VERSION ""

NS_ :

BS_:

BU_: MDC PAS

BO_ 517 PAS_SonarInfo_Rear: 64 PAS
 SG_ PAS_Sonar6_Echo_TOF1 : 7|16@0+ (1,0) [0|65535] "us"  MDC
 SG_ PAS_Sonar6_Echo_Width1 : 23|8@0+ (16,0) [0|4080] "us"  MDC
 SG_ PAS_Sonar6_Echo_TOF2 : 31|16@0+ (1,0) [0|65535] "us"  MDC
 SG_ PAS_Sonar6_Echo_Width2 : 47|8@0+ (16,0) [0|4080] "us"  MDC
 SG_ PAS_Sonar6_Echo_Peak1 : 391|6@0+ (1,0) [0|63] ""  MDC
 SG_ PAS_Sonar6_Echo_Peak2 : 385|6@0+ (1,0) [0|63] ""  MDC
 SG_ PAS_Sonar6_Emit : 457|2@0+ (1,0) [0|2] "bit"  MDC
 SG_ PAS_Sonar6_RingingTime : 55|16@0+ (0.0412,300) [300|3000] "us"  MDC
 SG_ PAS_Sonar6_Counter : 471|4@0+ (1,0) [0|15] "bit"  MDC
 SG_ PAS_Sonar7_Echo_TOF1 : 71|16@0+ (1,0) [0|65535] "us"  MDC
 SG_ PAS_Sonar7_Echo_Width1 : 87|8@0+ (16,0) [0|4080] "us"  MDC
 SG_ PAS_Sonar7_Echo_TOF2 : 95|16@0+ (1,0) [0|65535] "us"  MDC
 SG_ PAS_Sonar7_Echo_Width2 : 111|8@0+ (16,0) [0|4080] "us"  MDC
 SG_ PAS_Sonar7_Echo_Peak1 : 395|6@0+ (1,0) [0|63] ""  MDC
 SG_ PAS_Sonar7_Echo_Peak2 : 405|6@0+ (1,0) [0|63] ""  MDC
 SG_ PAS_Sonar7_Emit : 459|2@0+ (1,0) [0|2] "bit"  MDC
 SG_ PAS_Sonar7_RingingTime : 119|16@0+ (0.0412,300) [300|3000] "us"  MDC
 SG_ PAS_Sonar7_Counter : 475|4@0+ (1,0) [0|15] "bit"  MDC
 SG_ PAS_Sonar8_Echo_TOF1 : 135|16@0+ (1,0) [0|65535] "us"  MDC
 SG_ PAS_Sonar8_Echo_Width1 : 151|8@0+ (16,0) [0|4080] "us"  MDC
 SG_ PAS_Sonar8_Echo_TOF2 : 159|16@0+ (1,0) [0|65535] "us"  MDC
 SG_ PAS_Sonar8_Echo_Width2 : 175|8@0+ (16,0) [0|4080] "us"  MDC
 SG_ PAS_Sonar8_Echo_Peak1 : 415|6@0+ (1,0) [0|63] ""  MDC
 SG_ PAS_Sonar8_Echo_Peak2 : 409|6@0+ (1,0) [0|63] ""  MDC
 SG_ PAS_Sonar8_Emit : 461|2@0+ (1,0) [0|2] "bit"  MDC
 SG_ PAS_Sonar8_RingingTime : 183|16@0+ (0.0412,300) [300|3000] "us"  MDC
 SG_ PAS_Sonar8_Counter : 479|4@0+ (1,0) [0|15] "bit"  MDC
 SG_ PAS_Sonar9_Echo_TOF1 : 199|16@0+ (1,0) [0|65535] "us"  MDC
 SG_ PAS_Sonar9_Echo_Width1 : 215|8@0+ (16,0) [0|4080] "us"  MDC
 SG_ PAS_Sonar9_Echo_TOF2 : 223|16@0+ (1,0) [0|65535] "us"  MDC
 SG_ PAS_Sonar9_Echo_Width2 : 239|8@0+ (16,0) [0|4080] "us"  MDC
 SG_ PAS_Sonar9_Echo_Peak1 : 419|6@0+ (1,0) [0|63] ""  MDC
 SG_ PAS_Sonar9_Echo_Peak2 : 429|6@0+ (1,0) [0|63] ""  MDC
 SG_ PAS_Sonar9_Emit : 463|2@0+ (1,0) [0|2] "bit"  MDC
 SG_ PAS_Sonar9_RingingTime : 247|16@0+ (0.0412,300) [300|3000] "us"  MDC
 SG_ PAS_Sonar9_Counter : 483|4@0+ (1,0) [0|15] "bit"  MDC
 SG_ PAS_Sonar10_Echo_TOF1 : 263|16@0+ (1,0) [0|65535] "us"  MDC
 SG_ PAS_Sonar10_Echo_Width1 : 279|8@0+ (16,0) [0|4080] "us"  MDC
 SG_ PAS_Sonar10_Echo_TOF2 : 287|16@0+ (1,0) [0|65535] "us"  MDC
 SG_ PAS_Sonar10_Echo_Width2 : 303|8@0+ (16,0) [0|4080] "us"  MDC
 SG_ PAS_Sonar10_Echo_Peak1 : 439|6@0+ (1,0) [0|63] ""  MDC
 SG_ PAS_Sonar10_Echo_Peak2 : 433|6@0+ (1,0) [0|63] ""  MDC
 SG_ PAS_Sonar10_Emit : 465|2@0+ (1,0) [0|2] "bit"  MDC
 SG_ PAS_Sonar10_RingingTime : 311|16@0+ (0.0412,300) [300|3000] "us"  MDC
 SG_ PAS_Sonar10_Counter : 487|4@0+ (1,0) [0|15] "bit"  MDC
 SG_ PAS_Sonar11_Echo_TOF1 : 327|16@0+ (1,0) [0|65535] "us"  MDC
 SG_ PAS_Sonar11_Echo_Width1 : 343|8@0+ (16,0) [0|4080] "us"  MDC
 SG_ PAS_Sonar11_Echo_TOF2 : 351|16@0+ (1,0) [0|65535] "us"  MDC
 SG_ PAS_Sonar11_Echo_Width2 : 367|8@0+ (16,0) [0|4080] "us"  MDC
 SG_ PAS_Sonar11_Echo_Peak1 : 443|6@0+ (1,0) [0|63] ""  MDC
 SG_ PAS_Sonar11_Echo_Peak2 : 453|6@0+ (1,0) [0|63] ""  MDC
 SG_ PAS_Sonar11_Emit : 467|2@0+ (1,0) [0|2] "bit"  MDC
 SG_ PAS_Sonar11_RingingTime : 375|16@0+ (0.0412,300) [300|3000] "us"  MDC
 SG_ PAS_Sonar11_Counter : 491|4@0+ (1,0) [0|15] "bit"  MDC
 SG_ PASSonarInfoRearRollingCounter : 507|4@0+ (1,0) [0|14] "bit"  MDC
 SG_ PAS_SonarInfo_Rear_Checksum : 503|8@0+ (1,0) [0|255] "bit"  MDC
 SG_ Fill4bit : 511|4@0+ (1,0) [0|15] "bit"  MDC

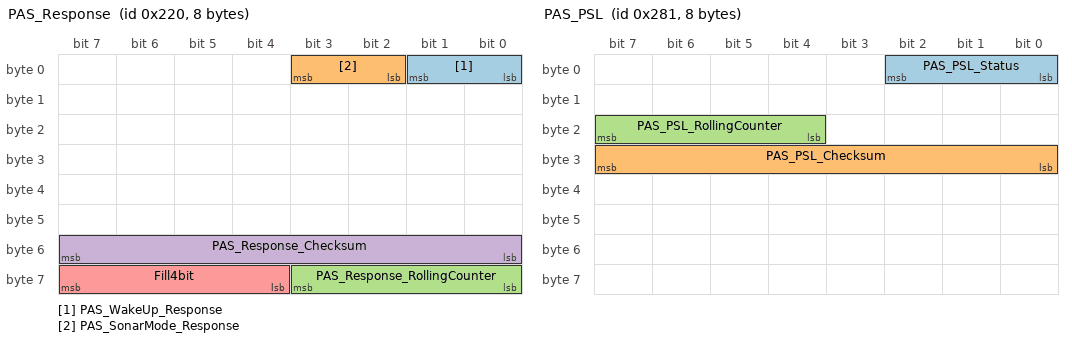
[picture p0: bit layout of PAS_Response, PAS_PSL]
BO_ 544 PAS_Response: 8 PAS
 SG_ PAS_WakeUp_Response : 1|2@0+ (1,0) [0|1] "bit"  MDC
 SG_ PAS_SonarMode_Response : 3|2@0+ (1,0) [0|1] "bit"  MDC
 SG_ PAS_Response_RollingCounter : 59|4@0+ (1,0) [0|14] "bit"  MDC
 SG_ PAS_Response_Checksum : 55|8@0+ (1,0) [0|255] "bit"  MDC
 SG_ Fill4bit : 63|4@0+ (1,0) [0|15] "bit"  MDC

BO_ 560 PAS_SensorStatus: 8 PAS
 SG_ PAS_SensorStsLR_FLS : 1|2@0+ (1,0) [0|1] "bit"  MDC
 SG_ PAS_SensorStsLR_FRS : 3|2@0+ (1,0) [0|1] "bit"  MDC
 SG_ PAS_SensorStsSR_FL : 5|2@0+ (1,0) [0|1] "bit"  MDC
 SG_ PAS_SensorStsSR_FML : 7|2@0+ (1,0) [0|1] "bit"  MDC
 SG_ PAS_SensorStsSR_FMR : 9|2@0+ (1,0) [0|1] "bit"  MDC
 SG_ PAS_SensorStsSR_FR : 11|2@0+ (1,0) [0|1] "bit"  MDC
 SG_ PAS_SensorStsLR_RLS : 13|2@0+ (1,0) [0|1] "bit"  MDC
 SG_ PAS_SensorStsLR_RRS : 15|2@0+ (1,0) [0|1] "bit"  MDC
 SG_ PAS_SensorStsSR_RL : 17|2@0+ (1,0) [0|1] "bit"  MDC
 SG_ PAS_SensorStsSR_RML : 19|2@0+ (1,0) [0|1] "bit"  MDC
 SG_ PAS_SensorStsSR_RMR : 21|2@0+ (1,0) [0|1] "bit"  MDC
 SG_ PAS_SensorStsSR_RR : 23|2@0+ (1,0) [0|1] "bit"  MDC
 SG_ PAS_ECU_Status : 25|2@0+ (1,0) [0|1] "bit"  MDC
 SG_ PAS_ECU_VehStatus_Reponse : 27|2@0+ (1,0) [0|1] "bit"  MDC
 SG_ sensorVersion_Status : 33|2@0+ (1,0) [0|1] "bit"  MDC
 SG_ PAS_SensorStatus_RollingCounter : 59|4@0+ (1,0) [0|14] "bit"  MDC
 SG_ PAS_SensorStatus_Checksum : 55|8@0+ (1,0) [0|255] "bit"  MDC
 SG_ Fill4bit : 63|4@0+ (1,0) [0|15] "bit"  MDC

BO_ 576 PAS_ECU_Version: 12 PAS
 SG_ PAS_ECU_Information_Ver_Hard : 7|8@0+ (1,0) [0|255] "bit"  MDC
 SG_ PAS_ECU_Information_Ver_Soft : 15|8@0+ (1,0) [0|255] "bit"  MDC
 SG_ PAS_ECU_Information_Ver_Boot : 23|8@0+ (1,0) [0|255] "bit"  MDC
 SG_ PAS_ECU_Information_Date_Year : 31|16@0+ (1,0) [0|65535] "bit"  MDC
 SG_ PAS_ECU_Information_Date_Month : 47|8@0+ (1,0) [0|255] "bit"  MDC
 SG_ PAS_ECU_Information_Date_Day : 55|8@0+ (1,0) [0|255] "bit"  MDC
 SG_ PAS_ECU_Version_Checksum : 87|8@0+ (1,0) [0|255] "bit"  MDC
 SG_ PAS_ECUInfo_RollingCounter : 91|4@0+ (1,0) [0|14] "bit"  MDC
 SG_ Fill4bit : 95|4@0+ (1,0) [0|15] "bit"  MDC

BO_ 592 PAS_RptAlarm: 12 PAS
 SG_ Rpt_Alarm_Id : 7|8@0+ (1,0) [0|255] "bit"  MDC
 SG_ Rpt_Alarm_State : 8|1@0+ (1,0) [0|1] "bit"  MDC
 SG_ Rpt_Alarm_Level : 11|2@0+ (1,0) [0|2] "bit"  MDC
 SG_ Rpt_Transaction_Id : 15|4@0+ (1,0) [0|15] "bit"  MDC
 SG_ Rpt_Alarm_Para1 : 23|16@0+ (1,0) [0|65535] "bit"  MDC
 SG_ Rpt_Alarm_Para2 : 39|16@0+ (1,0) [0|65535] "bit"  MDC
 SG_ Rpt_Alarm_Para3 : 55|16@0+ (1,0) [0|65535] "bit"  MDC
 SG_ Rpt_Alarm_Checksum : 87|8@0+ (1,0) [0|255] "bit"  MDC
 SG_ Rpt_Alarm_RollingCounter : 91|4@0+ (1,0) [0|14] "bit"  MDC
 SG_ Fill4bit : 95|4@0+ (1,0) [0|15] "bit"  MDC

BO_ 593 PAS_DiagnosisInfo: 16 PAS
 SG_ PAS_Sonar1_ControlBusFailure : 0|1@0+ (1,0) [0|1] "bit"  MDC
 SG_ PAS_Sonar1_RingingTimeFailure : 1|1@0+ (1,0) [0|1] "bit"  MDC
 SG_ PAS_Sonar1_ShortToGND : 2|1@0+ (1,0) [0|1] "bit"  MDC
 SG_ PAS_Sonar1_ShortToPositivePole : 3|1@0+ (1,0) [0|1] "bit"  MDC
 SG_ PAS_Sonar1_TypeMismatch : 4|1@0+ (1,0) [0|1] "bit"  MDC
 SG_ PAS_Sonar2_ControlBusFailure : 8|1@0+ (1,0) [0|1] "bit"  MDC
 SG_ PAS_Sonar2_RingingTimeFailure : 9|1@0+ (1,0) [0|1] "bit"  MDC
 SG_ PAS_Sonar2_ShortToGND : 10|1@0+ (1,0) [0|1] "bit"  MDC
 SG_ PAS_Sonar2_ShortToPositivePole : 11|1@0+ (1,0) [0|1] "bit"  MDC
 SG_ PAS_Sonar2_TypeMismatch : 12|1@0+ (1,0) [0|1] "bit"  MDC
 SG_ PAS_Sonar3_ControlBusFailure : 16|1@0+ (1,0) [0|1] "bit"  MDC
 SG_ PAS_Sonar3_RingingTimeFailure : 17|1@0+ (1,0) [0|1] "bit"  MDC
 SG_ PAS_Sonar3_ShortToGND : 18|1@0+ (1,0) [0|1] "bit"  MDC
 SG_ PAS_Sonar3_ShortToPositivePole : 19|1@0+ (1,0) [0|1] "bit"  MDC
 SG_ PAS_Sonar3_TypeMismatch : 20|1@0+ (1,0) [0|1] "bit"  MDC
 SG_ PAS_Sonar3_PowerVoltage_Low : 21|1@0+ (1,0) [0|1] "bit"  MDC
 SG_ PAS_Sonar3_PowerVoltage_High : 22|1@0+ (1,0) [0|1] "bit"  MDC
 SG_ PAS_Sonar4_ControlBusFailure : 24|1@0+ (1,0) [0|1] "bit"  MDC
 SG_ PAS_Sonar4_RingingTimeFailure : 25|1@0+ (1,0) [0|1] "bit"  MDC
 SG_ PAS_Sonar4_ShortToGND : 26|1@0+ (1,0) [0|1] "bit"  MDC
 SG_ PAS_Sonar4_ShortToPositivePole : 27|1@0+ (1,0) [0|1] "bit"  MDC
 SG_ PAS_Sonar4_TypeMismatch : 28|1@0+ (1,0) [0|1] "bit"  MDC
 SG_ PAS_Sonar7_ControlBusFailure : 32|1@0+ (1,0) [0|1] "bit"  MDC
 SG_ PAS_Sonar7_RingingTimeFailure : 33|1@0+ (1,0) [0|1] "bit"  MDC
 SG_ PAS_Sonar7_ShortToGND : 34|1@0+ (1,0) [0|1] "bit"  MDC
 SG_ PAS_Sonar7_ShortToPositivePole : 35|1@0+ (1,0) [0|1] "bit"  MDC
 SG_ PAS_Sonar7_TypeMismatch : 36|1@0+ (1,0) [0|1] "bit"  MDC
 SG_ PAS_Sonar8_ControlBusFailure : 40|1@0+ (1,0) [0|1] "bit"  MDC
 SG_ PAS_Sonar8_RingingTimeFailure : 41|1@0+ (1,0) [0|1] "bit"  MDC
 SG_ PAS_Sonar8_ShortToGND : 42|1@0+ (1,0) [0|1] "bit"  MDC
 SG_ PAS_Sonar8_ShortToPositivePole : 43|1@0+ (1,0) [0|1] "bit"  MDC
 SG_ PAS_Sonar8_TypeMismatch : 44|1@0+ (1,0) [0|1] "bit"  MDC
 SG_ PAS_Sonar9_ControlBusFailure : 48|1@0+ (1,0) [0|1] "bit"  MDC
 SG_ PAS_Sonar9_RingingTimeFailure : 49|1@0+ (1,0) [0|1] "bit"  MDC
 SG_ PAS_Sonar9_ShortToGND : 50|1@0+ (1,0) [0|1] "bit"  MDC
 SG_ PAS_Sonar9_ShortToPositivePole : 51|1@0+ (1,0) [0|1] "bit"  MDC
 SG_ PAS_Sonar9_TypeMismatch : 52|1@0+ (1,0) [0|1] "bit"  MDC
 SG_ PAS_Sonar10_ControlBusFailure : 56|1@0+ (1,0) [0|1] "bit"  MDC
 SG_ PAS_Sonar10_RingingTimeFailure : 57|1@0+ (1,0) [0|1] "bit"  MDC
 SG_ PAS_Sonar10_ShortToGND : 58|1@0+ (1,0) [0|1] "bit"  MDC
 SG_ PAS_Sonar10_ShortToPositivePole : 59|1@0+ (1,0) [0|1] "bit"  MDC
 SG_ PAS_Sonar10_TypeMismatch : 60|1@0+ (1,0) [0|1] "bit"  MDC
 SG_ PAS_Sonar0_ControlBusFailure : 64|1@0+ (1,0) [0|1] "bit"  MDC
 SG_ PAS_Sonar0_RingingTimeFailure : 65|1@0+ (1,0) [0|1] "bit"  MDC
 SG_ PAS_Sonar0_ShortToGND : 66|1@0+ (1,0) [0|1] "bit"  MDC
 SG_ PAS_Sonar0_ShortToPositivePole : 67|1@0+ (1,0) [0|1] "bit"  MDC
 SG_ PAS_Sonar0_TypeMismatch : 68|1@0+ (1,0) [0|1] "bit"  MDC
 SG_ PAS_Sonar5_ControlBusFailure : 72|1@0+ (1,0) [0|1] "bit"  MDC
 SG_ PAS_Sonar5_RingingTimeFailure : 73|1@0+ (1,0) [0|1] "bit"  MDC
 SG_ PAS_Sonar5_ShortToGND : 74|1@0+ (1,0) [0|1] "bit"  MDC
 SG_ PAS_Sonar5_ShortToPositivePole : 75|1@0+ (1,0) [0|1] "bit"  MDC
 SG_ PAS_Sonar5_TypeMismatch : 76|1@0+ (1,0) [0|1] "bit"  MDC
 SG_ PAS_Sonar6_ControlBusFailure : 80|1@0+ (1,0) [0|1] "bit"  MDC
 SG_ PAS_Sonar6_RingingTimeFailure : 81|1@0+ (1,0) [0|1] "bit"  MDC
 SG_ PAS_Sonar6_ShortToGND : 82|1@0+ (1,0) [0|1] "bit"  MDC
 SG_ PAS_Sonar6_ShortToPositivePole : 83|1@0+ (1,0) [0|1] "bit"  MDC
 SG_ PAS_Sonar6_TypeMismatch : 84|1@0+ (1,0) [0|1] "bit"  MDC
 SG_ PAS_Sonar11_ControlBusFailure : 88|1@0+ (1,0) [0|1] "bit"  MDC
 SG_ PAS_Sonar11_RingingTimeFailure : 89|1@0+ (1,0) [0|1] "bit"  MDC
 SG_ PAS_Sonar11_ShortToGND : 90|1@0+ (1,0) [0|1] "bit"  MDC
 SG_ PAS_Sonar11_ShortToPositivePole : 91|1@0+ (1,0) [0|1] "bit"  MDC
 SG_ PAS_Sonar11_TypeMismatch : 92|1@0+ (1,0) [0|1] "bit"  MDC
 SG_ PAS_ECU_OverVoltage : 96|1@0+ (1,0) [0|1] "bit"  MDC
 SG_ PAS_ECU_UnderVoltage : 97|1@0+ (1,0) [0|1] "bit"  MDC
 SG_ PAS_ECU_BusOff_ERROR : 98|1@0+ (1,0) [0|1] "bit"  MDC
 SG_ PAS_MDC_COMMU_ERROR : 99|1@0+ (1,0) [0|1] "bit"  MDC
 SG_ PAS_ECU_EEPROM_ERROR : 100|1@0+ (1,0) [0|1] "bit"  MDC
 SG_ PAS_DiagnosisInfo_RollingCounter : 123|4@0+ (1,0) [0|14] "bit"  MDC
 SG_ PAS_DiagnosisInfo_Checksum : 119|8@0+ (1,0) [0|255] "bit"  MDC
 SG_ Fill4bit : 127|4@0+ (1,0) [0|15] "bit"  MDC
 SG_ PAS_MDCSIGNAL_ERROR : 109|1@0+ (1,0) [0|1] "bit"  MDC
 SG_ PAS_ECU_INTERNAL_ERROR : 105|1@0+ (1,0) [0|1] "bit"  MDC
 SG_ PAS_TIMESYNC_ERROR : 106|1@0+ (1,0) [0|1] "bit"  MDC
 SG_ PAS_KEYLEARN_ERROR : 107|1@0+ (1,0) [0|1] "bit"  MDC
 SG_ PAS_AUTHEN_ERROR : 108|1@0+ (1,0) [0|1] "bit"  MDC
 SG_ PAS_Sonar0_Internal_failure : 29|1@0+ (1,0) [0|1] "bit"  MDC
 SG_ PAS_Sonar1_Internal_failure : 30|1@0+ (1,0) [0|1] "bit"  MDC
 SG_ PAS_Sonar2_Internal_failure : 31|1@0+ (1,0) [0|1] "bit"  MDC
 SG_ PAS_Sonar3_Internal_failure : 37|1@0+ (1,0) [0|1] "bit"  MDC
 SG_ PAS_Sonar4_Internal_failure : 38|1@0+ (1,0) [0|1] "bit"  MDC
 SG_ PAS_Sonar5_Internal_failure : 39|1@0+ (1,0) [0|1] "bit"  MDC
 SG_ PAS_Sonar6_Internal_failure : 45|1@0+ (1,0) [0|1] "bit"  MDC
 SG_ PAS_Sonar7_Internal_failure : 46|1@0+ (1,0) [0|1] "bit"  MDC
 SG_ PAS_Sonar8_Internal_failure : 47|1@0+ (1,0) [0|1] "bit"  MDC
 SG_ PAS_Sonar9_Internal_failure : 53|1@0+ (1,0) [0|1] "bit"  MDC
 SG_ PAS_Sonar10_Internal_failure : 54|1@0+ (1,0) [0|1] "bit"  MDC
 SG_ PAS_Sonar11_Internal_failure : 55|1@0+ (1,0) [0|1] "bit"  MDC
 SG_ USS_Front_ShortToGND : 61|1@0+ (1,0) [0|1] "bit"  MDC
 SG_ USS_Front_ShortToUbat : 62|1@0+ (1,0) [0|1] "bit"  MDC
 SG_ USS_Rear_ShortToGND : 63|1@0+ (1,0) [0|1] "bit"  MDC
 SG_ USS_Rear_ShortToUbat : 69|1@0+ (1,0) [0|1] "bit"  MDC
 SG_ VHM_Error : 70|1@0+ (1,0) [0|1] "bit"  MDC
 SG_ Sensor_Version_Fail : 71|1@0+ (1,0) [0|1] "bit"  MDC

BO_ 672 PAS_DeviceVertifyReq: 8 PAS
 SG_ PAS_Device_Vertify_Times : 7|8@0+ (1,0) [0|255] ""  MDC
 SG_ PAS_Device_Vertify_Status : 15|8@0+ (1,0) [0|1] ""  MDC

BO_ 673 PAS_Challenge_K1: 12 PAS
 SG_ PAS_RandomByte1 : 7|8@0+ (1,0) [0|255] "bit"  MDC
 SG_ PAS_RandomByte2 : 15|8@0+ (1,0) [0|255] "bit"  MDC
 SG_ PAS_RandomByte3 : 23|8@0+ (1,0) [0|255] "bit"  MDC
 SG_ PAS_RandomByte4 : 31|8@0+ (1,0) [0|255] "bit"  MDC
 SG_ PAS_RandomByte5 : 39|8@0+ (1,0) [0|255] "bit"  MDC
 SG_ PAS_RandomByte6 : 47|8@0+ (1,0) [0|255] "bit"  MDC
 SG_ PAS_RandomByte7 : 55|8@0+ (1,0) [0|255] "bit"  MDC
 SG_ PAS_RandomByte8 : 63|8@0+ (1,0) [0|255] "bit"  MDC
 SG_ PAS_SessionID : 71|8@0+ (1,0) [0|255] "bit"  MDC

BO_ 674 PAS_Response_K2: 12 PAS
 SG_ PAS_Verification_Result : 2|3@0+ (1,0) [0|1] ""  MDC
 SG_ PAS_SessionID : 15|8@0+ (1,0) [0|255] "" Vector__XXX
 SG_ PAS_CMACByte1 : 23|8@0+ (1,0) [0|255] "bit"  MDC
 SG_ PAS_CMACByte2 : 31|8@0+ (1,0) [0|255] "bit"  MDC
 SG_ PAS_CMACByte3 : 39|8@0+ (1,0) [0|255] "bit"  MDC
 SG_ PAS_CMACByte4 : 47|8@0+ (1,0) [0|255] "bit"  MDC
 SG_ PAS_CMACByte5 : 55|8@0+ (1,0) [0|255] "bit"  MDC
 SG_ PAS_CMACByte6 : 63|8@0+ (1,0) [0|255] "bit"  MDC
 SG_ PAS_CMACByte7 : 71|8@0+ (1,0) [0|255] "bit"  MDC
 SG_ PAS_CMACByte8 : 79|8@0+ (1,0) [0|255] "bit"  MDC

BO_ 706 PAS_Key_Learn_Status: 64 PAS
 SG_ PAS_Key_Learn_SubID : 7|8@0+ (1,0) [0|7] ""  MDC
 SG_ PAS_Key_Learn_Numbers : 15|8@0+ (1,0) [1|12] ""  MDC
 SG_ PAS_SKID1 : 23|8@0+ (1,0) [1|12] ""  MDC
 SG_ PAS_SK_Learn_Status1 : 31|8@0+ (1,0) [0|1] ""  MDC
 SG_ PAS_SKID2 : 39|8@0+ (1,0) [1|12] ""  MDC
 SG_ PAS_SK_Learn_Status2 : 47|8@0+ (1,0) [0|1] ""  MDC
 SG_ PAS_SKID3 : 55|8@0+ (1,0) [1|12] ""  MDC
 SG_ PAS_SK_Learn_Status3 : 63|8@0+ (1,0) [0|1] ""  MDC
 SG_ PAS_SKID4 : 71|8@0+ (1,0) [1|12] ""  MDC
 SG_ PAS_SK_Learn_Status4 : 79|8@0+ (1,0) [0|1] ""  MDC
 SG_ PAS_SKID5 : 87|8@0+ (1,0) [1|12] ""  MDC
 SG_ PAS_SK_Learn_Status5 : 95|8@0+ (1,0) [0|1] ""  MDC
 SG_ PAS_SKID6 : 103|8@0+ (1,0) [1|12] ""  MDC
 SG_ PAS_SK_Learn_Status6 : 111|8@0+ (1,0) [0|1] ""  MDC
 SG_ PAS_SKID7 : 119|8@0+ (1,0) [1|12] ""  MDC
 SG_ PAS_SK_Learn_Status7 : 127|8@0+ (1,0) [0|1] ""  MDC
 SG_ PAS_SKID8 : 135|8@0+ (1,0) [1|12] ""  MDC
 SG_ PAS_SK_Learn_Status8 : 143|8@0+ (1,0) [0|1] ""  MDC
 SG_ PAS_SKID9 : 151|8@0+ (1,0) [1|12] ""  MDC
 SG_ PAS_SK_Learn_Status9 : 159|8@0+ (1,0) [0|1] ""  MDC
 SG_ PAS_SKID10 : 167|8@0+ (1,0) [1|12] ""  MDC
 SG_ PAS_SK_Learn_Status10 : 175|8@0+ (1,0) [0|1] ""  MDC
 SG_ PAS_SKID11 : 183|8@0+ (1,0) [1|12] ""  MDC
 SG_ PAS_SK_Learn_Status11 : 191|8@0+ (1,0) [0|1] ""  MDC
 SG_ PAS_SKID12 : 199|8@0+ (1,0) [1|12] ""  MDC
 SG_ PAS_SK_Learn_Status12 : 207|8@0+ (1,0) [0|1] ""  MDC

BO_ 708 PAS_SK_Setting_Status: 64 PAS
 SG_ PASKeyLearnSubIDSettingResponse : 7|8@0+ (1,0) [0|7] ""  MDC
 SG_ PAS_SK_Setting_Response : 15|8@0+ (1,0) [1|12] ""  MDC
 SG_ PAS_SK_Setting_Status : 23|8@0+ (1,0) [0|1] ""  MDC

BO_ 707 PAS_SK_Verify_Result: 64 PAS
 SG_ PAS_VerifySubID : 7|8@0+ (1,0) [0|6] ""  MDC
 SG_ PAS_Verify_SKID : 15|8@0+ (1,0) [1|12] ""  MDC
 SG_ PAS_Verify_AES_Result : 23|32@0+ (1,0) [0|255] ""  MDC
 SG_ PAS_Verify_MACbyte1 : 55|8@0+ (1,0) [0|255] ""  MDC
 SG_ PAS_Verify_MACbyte2 : 63|8@0+ (1,0) [0|255] "" Vector__XXX
 SG_ PAS_Verify_MACbyte3 : 71|8@0+ (1,0) [0|255] "" Vector__XXX
 SG_ PAS_Verify_MACbyte4 : 79|8@0+ (1,0) [0|255] "" Vector__XXX
 SG_ PAS_Verify_MACbyte5 : 87|8@0+ (1,0) [0|255] "" Vector__XXX
 SG_ PAS_Verify_MACbyte6 : 95|8@0+ (1,0) [0|255] "" Vector__XXX
 SG_ PAS_Verify_MACbyte7 : 103|8@0+ (1,0) [0|255] "" Vector__XXX
 SG_ PAS_Verify_MACbyte8 : 111|8@0+ (1,0) [0|255] "" Vector__XXX
 SG_ PAS_Verify_MACbyte9 : 119|8@0+ (1,0) [0|255] "" Vector__XXX
 SG_ PAS_Verify_MACbyte10 : 127|8@0+ (1,0) [0|255] "" Vector__XXX
 SG_ PAS_Verify_MACbyte11 : 135|8@0+ (1,0) [0|255] "" Vector__XXX
 SG_ PAS_Verify_MACbyte12 : 143|8@0+ (1,0) [0|255] "" Vector__XXX
 SG_ PAS_Verify_MACbyte13 : 151|8@0+ (1,0) [0|255] "" Vector__XXX
 SG_ PAS_Verify_MACbyte14 : 159|8@0+ (1,0) [0|255] "" Vector__XXX
 SG_ PAS_Verify_MACbyte15 : 167|8@0+ (1,0) [0|255] "" Vector__XXX
 SG_ PAS_Verify_MACbyte16 : 175|8@0+ (1,0) [0|255] "" Vector__XXX
 SG_ PAS_Verify_IVByte1 : 183|8@0+ (1,0) [0|255] ""  MDC
 SG_ PAS_Verify_IVByte2 : 191|8@0+ (1,0) [0|255] "" Vector__XXX
 SG_ PAS_Verify_IVByte3 : 199|8@0+ (1,0) [0|255] "" Vector__XXX
 SG_ PAS_Verify_IVByte4 : 207|8@0+ (1,0) [0|255] "" Vector__XXX
 SG_ PAS_Verify_IVByte5 : 215|8@0+ (1,0) [0|255] "" Vector__XXX
 SG_ PAS_Verify_IVByte6 : 223|8@0+ (1,0) [0|255] "" Vector__XXX
 SG_ PAS_Verify_IVByte7 : 231|8@0+ (1,0) [0|255] "" Vector__XXX
 SG_ PAS_Verify_IVByte8 : 239|8@0+ (1,0) [0|255] "" Vector__XXX
 SG_ PAS_Verify_IVByte9 : 247|8@0+ (1,0) [0|255] "" Vector__XXX
 SG_ PAS_Verify_IVByte10 : 255|8@0+ (1,0) [0|255] "" Vector__XXX
 SG_ PAS_Verify_IVByte11 : 263|8@0+ (1,0) [0|255] "" Vector__XXX
 SG_ PAS_Verify_IVByte12 : 271|8@0+ (1,0) [0|255] "" Vector__XXX

BO_ 608 UPC_Object1_5: 64 PAS
 SG_ UPC_Object1_Type : 2|3@0+ (1,0) [0|7] ""  MDC
 SG_ UPC_Object1_ExistProbability : 14|7@0+ (1,0) [0|100] "%"  MDC
 SG_ UPC_Object1_Height : 4|2@0+ (1,0) [0|3] ""  MDC
 SG_ UPC_Object1_HeightProbability : 7|3@0+ (20,0) [0|100] "%"  MDC
 SG_ UPCObject1PositionUpdateTime : 23|12@0+ (0.5,0) [0|1000] "ms"  MDC
 SG_ UPC_Object1_Point1PositionX : 26|11@0+ (1,-1024) [-1024|1023] "cm"  MDC
 SG_ UPC_Object1_Point1PositionY : 47|11@0+ (1,-1024) [-1024|1023] "cm"  MDC
 SG_ UPC_Object1_Point2PositionX : 50|11@0+ (1,-1024) [-1024|1023] "cm"  MDC
 SG_ UPC_Object1_Point2PositionY : 71|11@0+ (1,-1024) [-1024|1023] "cm"  MDC
 SG_ UPC_Object1_ID : 87|16@0+ (1,0) [0|65535] ""  MDC
 SG_ UPC_Object2_Type : 98|3@0+ (1,0) [0|7] ""  MDC
 SG_ UPC_Object2_ExistProbability : 110|7@0+ (1,0) [0|100] "%"  MDC
 SG_ UPC_Object2_Height : 100|2@0+ (1,0) [0|3] ""  MDC
 SG_ UPC_Object2_HeightProbability : 103|3@0+ (20,0) [0|100] "%"  MDC
 SG_ UPCObject2PositionUpdateTime : 119|12@0+ (0.5,0) [0|1000] "ms"  MDC
 SG_ UPC_Object2_Point1PositionX : 122|11@0+ (1,-1024) [-1024|1023] "cm"  MDC
 SG_ UPC_Object2_Point1PositionY : 143|11@0+ (1,-1024) [-1024|1023] "cm"  MDC
 SG_ UPC_Object2_Point2PositionX : 146|11@0+ (1,-1024) [-1024|1023] "cm"  MDC
 SG_ UPC_Object2_Point2PositionY : 167|11@0+ (1,-1024) [-1024|1023] "cm"  MDC
 SG_ UPC_Object2_ID : 183|16@0+ (1,0) [0|65535] ""  MDC
 SG_ UPC_Object3_Type : 194|3@0+ (1,0) [0|7] ""  MDC
 SG_ UPC_Object3_ExistProbability : 206|7@0+ (1,0) [0|100] "%"  MDC
 SG_ UPC_Object3_Height : 196|2@0+ (1,0) [0|3] ""  MDC
 SG_ UPC_Object3_HeightProbability : 199|3@0+ (20,0) [0|100] "%"  MDC
 SG_ UPCObject3PositionUpdateTime : 215|12@0+ (0.5,0) [0|1000] "ms"  MDC
 SG_ UPC_Object3_Point1PositionX : 218|11@0+ (1,-1024) [-1024|1023] "cm"  MDC
 SG_ UPC_Object3_Point1PositionY : 239|11@0+ (1,-1024) [-1024|1023] "cm"  MDC
 SG_ UPC_Object3_Point2PositionX : 242|11@0+ (1,-1024) [-1024|1023] "cm"  MDC
 SG_ UPC_Object3_Point2PositionY : 263|11@0+ (1,-1024) [-1024|1023] "cm"  MDC
 SG_ UPC_Object3_ID : 279|16@0+ (1,0) [0|65535] ""  MDC
 SG_ UPC_Object4_Type : 290|3@0+ (1,0) [0|7] ""  MDC
 SG_ UPC_Object4_ExistProbability : 302|7@0+ (1,0) [0|100] "%"  MDC
 SG_ UPC_Object4_Height : 292|2@0+ (1,0) [0|3] ""  MDC
 SG_ UPC_Object4_HeightProbability : 295|3@0+ (20,0) [0|100] "%"  MDC
 SG_ UPCObject4PositionUpdateTime : 311|12@0+ (0.5,0) [0|1000] "ms"  MDC
 SG_ UPC_Object4_Point1PositionX : 314|11@0+ (1,-1024) [-1024|1023] "cm"  MDC
 SG_ UPC_Object4_Point1PositionY : 335|11@0+ (1,-1024) [-1024|1023] "cm"  MDC
 SG_ UPC_Object4_Point2PositionX : 338|11@0+ (1,-1024) [-1024|1023] "cm"  MDC
 SG_ UPC_Object4_Point2PositionY : 359|11@0+ (1,-1024) [-1024|1023] "cm"  MDC
 SG_ UPC_Object4_ID : 375|16@0+ (1,0) [0|65535] ""  MDC
 SG_ UPC_Object5_Type : 386|3@0+ (1,0) [0|7] ""  MDC
 SG_ UPC_Object5_ExistProbability : 398|7@0+ (1,0) [0|100] "%"  MDC
 SG_ UPC_Object5_Height : 388|2@0+ (1,0) [0|3] ""  MDC
 SG_ UPC_Object5_HeightProbability : 391|3@0+ (20,0) [0|100] "%"  MDC
 SG_ UPCObject5PositionUpdateTime : 407|12@0+ (0.5,0) [0|1000] "ms"  MDC
 SG_ UPC_Object5_Point1PositionX : 410|11@0+ (1,-1024) [-1024|1023] "cm"  MDC
 SG_ UPC_Object5_Point1PositionY : 431|11@0+ (1,-1024) [-1024|1023] "cm"  MDC
 SG_ UPC_Object5_Point2PositionX : 434|11@0+ (1,-1024) [-1024|1023] "cm"  MDC
 SG_ UPC_Object5_Point2PositionY : 455|11@0+ (1,-1024) [-1024|1023] "cm"  MDC
 SG_ UPC_Object5_ID : 471|16@0+ (1,0) [0|65535] ""  MDC
 SG_ PAS_Obj1_5_Checksum : 511|8@0+ (1,0) [0|255] "bit"  MDC
 SG_ PAS_Obj1_5_RollingCounter : 499|4@0+ (1,0) [0|14] "bit"  MDC

BO_ 609 UPC_Object6_10: 64 PAS
 SG_ UPC_Object6_Type : 2|3@0+ (1,0) [0|7] ""  MDC
 SG_ UPC_Object6_ExistProbability : 14|7@0+ (1,0) [0|100] "%"  MDC
 SG_ UPC_Object6_Height : 4|2@0+ (1,0) [0|3] ""  MDC
 SG_ UPC_Object6_HeightProbability : 7|3@0+ (20,0) [0|100] "%"  MDC
 SG_ UPCObject6PositionUpdateTime : 23|12@0+ (0.5,0) [0|1000] "ms"  MDC
 SG_ UPC_Object6_Point1PositionX : 26|11@0+ (1,-1024) [-1024|1023] "cm"  MDC
 SG_ UPC_Object6_Point1PositionY : 47|11@0+ (1,-1024) [-1024|1023] "cm"  MDC
 SG_ UPC_Object6_Point2PositionX : 50|11@0+ (1,-1024) [-1024|1023] "cm"  MDC
 SG_ UPC_Object6_Point2PositionY : 71|11@0+ (1,-1024) [-1024|1023] "cm"  MDC
 SG_ UPC_Object6_ID : 87|16@0+ (1,0) [0|65535] ""  MDC
 SG_ UPC_Object7_Type : 98|3@0+ (1,0) [0|7] ""  MDC
 SG_ UPC_Object7_ExistProbability : 110|7@0+ (1,0) [0|100] "%"  MDC
 SG_ UPC_Object7_Height : 100|2@0+ (1,0) [0|3] ""  MDC
 SG_ UPC_Object7_HeightProbability : 103|3@0+ (20,0) [0|100] "%"  MDC
 SG_ UPCObject7PositionUpdateTime : 119|12@0+ (0.5,0) [0|1000] "ms"  MDC
 SG_ UPC_Object7_Point1PositionX : 122|11@0+ (1,-1024) [-1024|1023] "cm"  MDC
 SG_ UPC_Object7_Point1PositionY : 143|11@0+ (1,-1024) [-1024|1023] "cm"  MDC
 SG_ UPC_Object7_Point2PositionX : 146|11@0+ (1,-1024) [-1024|1023] "cm"  MDC
 SG_ UPC_Object7_Point2PositionY : 167|11@0+ (1,-1024) [-1024|1023] "cm"  MDC
 SG_ UPC_Object7_ID : 183|16@0+ (1,0) [0|65535] ""  MDC
 SG_ UPC_Object8_Type : 194|3@0+ (1,0) [0|7] ""  MDC
 SG_ UPC_Object8_ExistProbability : 206|7@0+ (1,0) [0|100] "%"  MDC
 SG_ UPC_Object8_Height : 196|2@0+ (1,0) [0|3] ""  MDC
 SG_ UPC_Object8_HeightProbability : 199|3@0+ (20,0) [0|100] "%"  MDC
 SG_ UPCObject8PositionUpdateTime : 215|12@0+ (0.5,0) [0|1000] "ms"  MDC
 SG_ UPC_Object8_Point1PositionX : 218|11@0+ (1,-1024) [-1024|1023] "cm"  MDC
 SG_ UPC_Object8_Point1PositionY : 239|11@0+ (1,-1024) [-1024|1023] "cm"  MDC
 SG_ UPC_Object8_Point2PositionX : 242|11@0+ (1,-1024) [-1024|1023] "cm"  MDC
 SG_ UPC_Object8_Point2PositionY : 263|11@0+ (1,-1024) [-1024|1023] "cm"  MDC
 SG_ UPC_Object8_ID : 279|16@0+ (1,0) [0|65535] ""  MDC
 SG_ UPC_Object9_Type : 290|3@0+ (1,0) [0|7] ""  MDC
 SG_ UPC_Object9_ExistProbability : 302|7@0+ (1,0) [0|100] "%"  MDC
 SG_ UPC_Object9_Height : 292|2@0+ (1,0) [0|3] ""  MDC
 SG_ UPC_Object9_HeightProbability : 295|3@0+ (20,0) [0|100] "%"  MDC
 SG_ UPCObject9PositionUpdateTime : 311|12@0+ (0.5,0) [0|1000] "ms"  MDC
 SG_ UPC_Object9_Point1PositionX : 314|11@0+ (1,-1024) [-1024|1023] "cm"  MDC
 SG_ UPC_Object9_Point1PositionY : 335|11@0+ (1,-1024) [-1024|1023] "cm"  MDC
 SG_ UPC_Object9_Point2PositionX : 338|11@0+ (1,-1024) [-1024|1023] "cm"  MDC
 SG_ UPC_Object9_Point2PositionY : 359|11@0+ (1,-1024) [-1024|1023] "cm"  MDC
 SG_ UPC_Object9_ID : 375|16@0+ (1,0) [0|65535] ""  MDC
 SG_ UPC_Object10_Type : 386|3@0+ (1,0) [0|7] ""  MDC
 SG_ UPC_Object10_ExistProbability : 398|7@0+ (1,0) [0|100] "%"  MDC
 SG_ UPC_Object10_Height : 388|2@0+ (1,0) [0|3] ""  MDC
 SG_ UPC_Object10_HeightProbability : 391|3@0+ (20,0) [0|100] "%"  MDC
 SG_ UPCObject10PositionUpdateTime : 407|12@0+ (0.5,0) [0|1000] "ms"  MDC
 SG_ UPC_Object10_Point1PositionX : 410|11@0+ (1,-1024) [-1024|1023] "cm"  MDC
 SG_ UPC_Object10_Point1PositionY : 431|11@0+ (1,-1024) [-1024|1023] "cm"  MDC
 SG_ UPC_Object10_Point2PositionX : 434|11@0+ (1,-1024) [-1024|1023] "cm"  MDC
 SG_ UPC_Object10_Point2PositionY : 455|11@0+ (1,-1024) [-1024|1023] "cm"  MDC
 SG_ UPC_Object10_ID : 471|16@0+ (1,0) [0|65535] ""  MDC
 SG_ PAS_Obj6_10_Checksum : 511|8@0+ (1,0) [0|255] "bit"  MDC
 SG_ PAS_Obj6_10_RollingCounter : 499|4@0+ (1,0) [0|14] "bit"  MDC

BO_ 610 UPC_Object11_15: 64 PAS
 SG_ UPC_Object11_Type : 2|3@0+ (1,0) [0|7] ""  MDC
 SG_ UPC_Object11_ExistProbability : 14|7@0+ (1,0) [0|100] "%"  MDC
 SG_ UPC_Object11_Height : 4|2@0+ (1,0) [0|3] ""  MDC
 SG_ UPC_Object11_HeightProbability : 7|3@0+ (20,0) [0|100] "%"  MDC
 SG_ UPCObject11PositionUpdateTime : 23|12@0+ (0.5,0) [0|1000] "ms"  MDC
 SG_ UPC_Object11_Point1PositionX : 26|11@0+ (1,-1024) [-1024|1023] "cm"  MDC
 SG_ UPC_Object11_Point1PositionY : 47|11@0+ (1,-1024) [-1024|1023] "cm"  MDC
 SG_ UPC_Object11_Point2PositionX : 50|11@0+ (1,-1024) [-1024|1023] "cm"  MDC
 SG_ UPC_Object11_Point2PositionY : 71|11@0+ (1,-1024) [-1024|1023] "cm"  MDC
 SG_ UPC_Object11_ID : 87|16@0+ (1,0) [0|65535] ""  MDC
 SG_ UPC_Object12_Type : 98|3@0+ (1,0) [0|7] ""  MDC
 SG_ UPC_Object12_ExistProbability : 110|7@0+ (1,0) [0|100] "%"  MDC
 SG_ UPC_Object12_Height : 100|2@0+ (1,0) [0|3] ""  MDC
 SG_ UPC_Object12_HeightProbability : 103|3@0+ (20,0) [0|100] "%"  MDC
 SG_ UPCObject12PositionUpdateTime : 119|12@0+ (0.5,0) [0|1000] "ms"  MDC
 SG_ UPC_Object12_Point1PositionX : 122|11@0+ (1,-1024) [-1024|1023] "cm"  MDC
 SG_ UPC_Object12_Point1PositionY : 143|11@0+ (1,-1024) [-1024|1023] "cm"  MDC
 SG_ UPC_Object12_Point2PositionX : 146|11@0+ (1,-1024) [-1024|1023] "cm"  MDC
 SG_ UPC_Object12_Point2PositionY : 167|11@0+ (1,-1024) [-1024|1023] "cm"  MDC
 SG_ UPC_Object12_ID : 183|16@0+ (1,0) [0|65535] ""  MDC
 SG_ UPC_Object13_Type : 194|3@0+ (1,0) [0|7] ""  MDC
 SG_ UPC_Object13_ExistProbability : 206|7@0+ (1,0) [0|100] "%"  MDC
 SG_ UPC_Object13_Height : 196|2@0+ (1,0) [0|3] ""  MDC
 SG_ UPC_Object13_HeightProbability : 199|3@0+ (20,0) [0|100] "%"  MDC
 SG_ UPCObject13PositionUpdateTime : 215|12@0+ (0.5,0) [0|1000] "ms"  MDC
 SG_ UPC_Object13_Point1PositionX : 218|11@0+ (1,-1024) [-1024|1023] "cm"  MDC
 SG_ UPC_Object13_Point1PositionY : 239|11@0+ (1,-1024) [-1024|1023] "cm"  MDC
 SG_ UPC_Object13_Point2PositionX : 242|11@0+ (1,-1024) [-1024|1023] "cm"  MDC
 SG_ UPC_Object13_Point2PositionY : 263|11@0+ (1,-1024) [-1024|1023] "cm"  MDC
 SG_ UPC_Object13_ID : 279|16@0+ (1,0) [0|65535] ""  MDC
 SG_ UPC_Object14_Type : 290|3@0+ (1,0) [0|7] ""  MDC
 SG_ UPC_Object14_ExistProbability : 302|7@0+ (1,0) [0|100] "%"  MDC
 SG_ UPC_Object14_Height : 292|2@0+ (1,0) [0|3] ""  MDC
 SG_ UPC_Object14_HeightProbability : 295|3@0+ (20,0) [0|100] "%"  MDC
 SG_ UPCObject14PositionUpdateTime : 311|12@0+ (0.5,0) [0|1000] "ms"  MDC
 SG_ UPC_Object14_Point1PositionX : 314|11@0+ (1,-1024) [-1024|1023] "cm"  MDC
 SG_ UPC_Object14_Point1PositionY : 335|11@0+ (1,-1024) [-1024|1023] "cm"  MDC
 SG_ UPC_Object14_Point2PositionX : 338|11@0+ (1,-1024) [-1024|1023] "cm"  MDC
 SG_ UPC_Object14_Point2PositionY : 359|11@0+ (1,-1024) [-1024|1023] "cm"  MDC
 SG_ UPC_Object14_ID : 375|16@0+ (1,0) [0|65535] ""  MDC
 SG_ UPC_Object15_Type : 386|3@0+ (1,0) [0|7] ""  MDC
 SG_ UPC_Object15_ExistProbability : 398|7@0+ (1,0) [0|100] "%"  MDC
 SG_ UPC_Object15_Height : 388|2@0+ (1,0) [0|3] ""  MDC
 SG_ UPC_Object15_HeightProbability : 391|3@0+ (20,0) [0|100] "%"  MDC
 SG_ UPCObject15PositionUpdateTime : 407|12@0+ (0.5,0) [0|1000] "ms"  MDC
 SG_ UPC_Object15_Point1PositionX : 410|11@0+ (1,-1024) [-1024|1023] "cm"  MDC
 SG_ UPC_Object15_Point1PositionY : 431|11@0+ (1,-1024) [-1024|1023] "cm"  MDC
 SG_ UPC_Object15_Point2PositionX : 434|11@0+ (1,-1024) [-1024|1023] "cm"  MDC
 SG_ UPC_Object15_Point2PositionY : 455|11@0+ (1,-1024) [-1024|1023] "cm"  MDC
 SG_ UPC_Object15_ID : 471|16@0+ (1,0) [0|65535] ""  MDC
 SG_ PAS_Obj11_15_Checksum : 511|8@0+ (1,0) [0|255] "bit"  MDC
 SG_ PAS_Obj11_15_RollingCounter : 499|4@0+ (1,0) [0|14] "bit"  MDC

BO_ 611 UPC_Object16_20: 64 PAS
 SG_ UPC_Object16_Type : 2|3@0+ (1,0) [0|7] ""  MDC
 SG_ UPC_Object16_ExistProbability : 14|7@0+ (1,0) [0|100] "%"  MDC
 SG_ UPC_Object16_Height : 4|2@0+ (1,0) [0|3] ""  MDC
 SG_ UPC_Object16_HeightProbability : 7|3@0+ (20,0) [0|100] "%"  MDC
 SG_ UPCObject16PositionUpdateTime : 23|12@0+ (0.5,0) [0|1000] "ms"  MDC
 SG_ UPC_Object16_Point1PositionX : 26|11@0+ (1,-1024) [-1024|1023] "cm"  MDC
 SG_ UPC_Object16_Point1PositionY : 47|11@0+ (1,-1024) [-1024|1023] "cm"  MDC
 SG_ UPC_Object16_Point2PositionX : 50|11@0+ (1,-1024) [-1024|1023] "cm"  MDC
 SG_ UPC_Object16_Point2PositionY : 71|11@0+ (1,-1024) [-1024|1023] "cm"  MDC
 SG_ UPC_Object16_ID : 87|16@0+ (1,0) [0|65535] ""  MDC
 SG_ UPC_Object17_Type : 98|3@0+ (1,0) [0|7] ""  MDC
 SG_ UPC_Object17_ExistProbability : 110|7@0+ (1,0) [0|100] "%"  MDC
 SG_ UPC_Object17_Height : 100|2@0+ (1,0) [0|3] ""  MDC
 SG_ UPC_Object17_HeightProbability : 103|3@0+ (20,0) [0|100] "%"  MDC
 SG_ UPCObject17PositionUpdateTime : 119|12@0+ (0.5,0) [0|1000] "ms"  MDC
 SG_ UPC_Object17_Point1PositionX : 122|11@0+ (1,-1024) [-1024|1023] "cm"  MDC
 SG_ UPC_Object17_Point1PositionY : 143|11@0+ (1,-1024) [-1024|1023] "cm"  MDC
 SG_ UPC_Object17_Point2PositionX : 146|11@0+ (1,-1024) [-1024|1023] "cm"  MDC
 SG_ UPC_Object17_Point2PositionY : 167|11@0+ (1,-1024) [-1024|1023] "cm"  MDC
 SG_ UPC_Object17_ID : 183|16@0+ (1,0) [0|65535] ""  MDC
 SG_ UPC_Object18_Type : 194|3@0+ (1,0) [0|7] ""  MDC
 SG_ UPC_Object18_ExistProbability : 206|7@0+ (1,0) [0|100] "%"  MDC
 SG_ UPC_Object18_Height : 196|2@0+ (1,0) [0|3] ""  MDC
 SG_ UPC_Object18_HeightProbability : 199|3@0+ (20,0) [0|100] "%"  MDC
 SG_ UPCObject18PositionUpdateTime : 215|12@0+ (0.5,0) [0|1000] "ms"  MDC
 SG_ UPC_Object18_Point1PositionX : 218|11@0+ (1,-1024) [-1024|1023] "cm"  MDC
 SG_ UPC_Object18_Point1PositionY : 239|11@0+ (1,-1024) [-1024|1023] "cm"  MDC
 SG_ UPC_Object18_Point2PositionX : 242|11@0+ (1,-1024) [-1024|1023] "cm"  MDC
 SG_ UPC_Object18_Point2PositionY : 263|11@0+ (1,-1024) [-1024|1023] "cm"  MDC
 SG_ UPC_Object18_ID : 279|16@0+ (1,0) [0|65535] ""  MDC
 SG_ UPC_Object19_Type : 290|3@0+ (1,0) [0|7] ""  MDC
 SG_ UPC_Object19_ExistProbability : 302|7@0+ (1,0) [0|100] "%"  MDC
 SG_ UPC_Object19_Height : 292|2@0+ (1,0) [0|3] ""  MDC
 SG_ UPC_Object19_HeightProbability : 295|3@0+ (20,0) [0|100] "%"  MDC
 SG_ UPCObject19PositionUpdateTime : 311|12@0+ (0.5,0) [0|1000] "ms"  MDC
 SG_ UPC_Object19_Point1PositionX : 314|11@0+ (1,-1024) [-1024|1023] "cm"  MDC
 SG_ UPC_Object19_Point1PositionY : 335|11@0+ (1,-1024) [-1024|1023] "cm"  MDC
 SG_ UPC_Object19_Point2PositionX : 338|11@0+ (1,-1024) [-1024|1023] "cm"  MDC
 SG_ UPC_Object19_Point2PositionY : 359|11@0+ (1,-1024) [-1024|1023] "cm"  MDC
 SG_ UPC_Object19_ID : 375|16@0+ (1,0) [0|65535] ""  MDC
 SG_ UPC_Object20_Type : 386|3@0+ (1,0) [0|7] ""  MDC
 SG_ UPC_Object20_ExistProbability : 398|7@0+ (1,0) [0|100] "%"  MDC
 SG_ UPC_Object20_Height : 388|2@0+ (1,0) [0|3] ""  MDC
 SG_ UPC_Object20_HeightProbability : 391|3@0+ (20,0) [0|100] "%"  MDC
 SG_ UPCObject20PositionUpdateTime : 407|12@0+ (0.5,0) [0|1000] "ms"  MDC
 SG_ UPC_Object20_Point1PositionX : 410|11@0+ (1,-1024) [-1024|1023] "cm"  MDC
 SG_ UPC_Object20_Point1PositionY : 431|11@0+ (1,-1024) [-1024|1023] "cm"  MDC
 SG_ UPC_Object20_Point2PositionX : 434|11@0+ (1,-1024) [-1024|1023] "cm"  MDC
 SG_ UPC_Object20_Point2PositionY : 455|11@0+ (1,-1024) [-1024|1023] "cm"  MDC
 SG_ UPC_Object20_ID : 471|16@0+ (1,0) [0|65535] ""  MDC
 SG_ PAS_Obj16_20_Checksum : 511|8@0+ (1,0) [0|255] "bit"  MDC
 SG_ PAS_Obj16_20_RollingCounter : 499|4@0+ (1,0) [0|14] "bit"  MDC

BO_ 624 UPC_ParkingSlot1_3: 64 PAS
 SG_ UPC_ParkingSlot1_ID : 7|8@0+ (1,0) [0|255] ""  MDC
 SG_ UPC_ParkingSlot1_Status : 20|2@0+ (1,0) [0|3] ""  MDC
 SG_ UPC_ParkingSlot1_Type : 18|3@0+ (1,0) [0|7] ""  MDC
 SG_ UPC_ParkingSlot1_ObjectType : 37|3@0+ (1,0) [0|7] ""  MDC
 SG_ UPC_ParkingSlot1_Length : 15|11@0+ (1,0) [0|2045] "cm"  MDC
 SG_ UPC_ParkingSlot1_Depth : 31|10@0+ (1,0) [0|1021] "cm"  MDC
 SG_ UPCParkSlot1Point1ObjectType : 34|2@0+ (1,0) [0|3] ""  MDC
 SG_ UPCParkSlot1Point2ObjectType : 74|2@0+ (1,0) [0|3] ""  MDC
 SG_ UPCParkSlot1Point1PositionAngle : 46|7@0+ (1,-64) [-64|63] "degree"  MDC
 SG_ UPCParkSlot1Point2PositionAngle : 62|7@0+ (1,-64) [-64|63] "degree"  MDC
 SG_ UPCParkSlot1Point1PositionX : 71|13@0+ (1,-4095) [-4095|4094] "cm"  MDC
 SG_ UPCParkSlot1Point1PositionY : 87|13@0+ (1,-4095) [-4095|4094] "cm"  MDC
 SG_ UPCParkSlot1Point2PositionX : 103|13@0+ (1,-4095) [-4095|4094] "cm"  MDC
 SG_ UPCParkSlot1Point2PositionY : 119|13@0+ (1,-4095) [-4095|4094] "cm"  MDC
 SG_ UPCParkSlot1PositionUpdateTime : 135|12@0+ (0.5,0) [0|1000] "ms"  MDC
 SG_ UPC_ParkingSlot2_ID : 151|8@0+ (1,0) [0|255] ""  MDC
 SG_ UPC_ParkingSlot2_Status : 164|2@0+ (1,0) [0|3] ""  MDC
 SG_ UPC_ParkingSlot2_Type : 162|3@0+ (1,0) [0|7] ""  MDC
 SG_ UPC_ParkingSlot2_ObjectType : 181|3@0+ (1,0) [0|7] ""  MDC
 SG_ UPC_ParkingSlot2_Length : 159|11@0+ (1,0) [0|2045] "cm"  MDC
 SG_ UPC_ParkingSlot2_Depth : 175|10@0+ (1,0) [0|1021] "cm"  MDC
 SG_ UPCParkSlot2Point1ObjectType : 178|2@0+ (1,0) [0|3] ""  MDC
 SG_ UPCParkSlot2Point2ObjectType : 218|2@0+ (1,0) [0|3] ""  MDC
 SG_ UPCParkSlot2Point1PositionAngle : 190|7@0+ (1,-64) [-64|63] "degree"  MDC
 SG_ UPCParkSlot2Point2PositionAngle : 206|7@0+ (1,-64) [-64|63] "degree"  MDC
 SG_ UPCParkSlot2Point1PositionX : 215|13@0+ (1,-4095) [-4095|4094] "cm"  MDC
 SG_ UPCParkSlot2Point1PositionY : 231|13@0+ (1,-4095) [-4095|4094] "cm"  MDC
 SG_ UPCParkSlot2Point2PositionX : 247|13@0+ (1,-4095) [-4095|4094] "cm"  MDC
 SG_ UPCParkSlot2Point2PositionY : 263|13@0+ (1,-4095) [-4095|4094] "cm"  MDC
 SG_ UPCParkSlot2PositionUpdateTime : 279|12@0+ (0.5,0) [0|1000] "ms"  MDC
 SG_ UPC_ParkingSlot3_ID : 295|8@0+ (1,0) [0|255] ""  MDC
 SG_ UPC_ParkingSlot3_Status : 308|2@0+ (1,0) [0|3] ""  MDC
 SG_ UPC_ParkingSlot3_Type : 306|3@0+ (1,0) [0|7] ""  MDC
 SG_ UPC_ParkingSlot3_ObjectType : 325|3@0+ (1,0) [0|7] ""  MDC
 SG_ UPC_ParkingSlot3_Length : 303|11@0+ (1,0) [0|2045] "cm"  MDC
 SG_ UPC_ParkingSlot3_Depth : 319|10@0+ (1,0) [0|1021] "cm"  MDC
 SG_ UPCParkSlot3Point1ObjectType : 322|2@0+ (1,0) [0|3] ""  MDC
 SG_ UPCParkSlot3Point2ObjectType : 362|2@0+ (1,0) [0|3] ""  MDC
 SG_ UPCParkSlot3Point1PositionAngle : 334|7@0+ (1,-64) [-64|63] "degree"  MDC
 SG_ UPCParkSlot3Point2PositionAngle : 350|7@0+ (1,-64) [-64|63] "degree"  MDC
 SG_ UPCParkSlot3Point1PositionX : 359|13@0+ (1,-4095) [-4095|4094] "cm"  MDC
 SG_ UPCParkSlot3Point1PositionY : 375|13@0+ (1,-4095) [-4095|4094] "cm"  MDC
 SG_ UPCParkSlot3Point2PositionX : 391|13@0+ (1,-4095) [-4095|4094] "cm"  MDC
 SG_ UPCParkSlot3Point2PositionY : 407|13@0+ (1,-4095) [-4095|4094] "cm"  MDC
 SG_ UPCParkSlot3PositionUpdateTime : 423|12@0+ (0.5,0) [0|1000] "ms"  MDC
 SG_ PAS_Slot1_3_Checksum : 511|8@0+ (1,0) [0|255] "bit"  MDC
 SG_ PAS_Slot1_3_RollingCounter : 503|4@0+ (1,0) [0|14] "bit"  MDC

BO_ 625 UPC_ParkingSlot4_6: 64 PAS
 SG_ UPC_ParkingSlot4_ID : 7|8@0+ (1,0) [0|255] ""  MDC
 SG_ UPC_ParkingSlot4_Status : 20|2@0+ (1,0) [0|3] ""  MDC
 SG_ UPC_ParkingSlot4_Type : 18|3@0+ (1,0) [0|7] ""  MDC
 SG_ UPC_ParkingSlot4_ObjectType : 37|3@0+ (1,0) [0|7] ""  MDC
 SG_ UPC_ParkingSlot4_Length : 15|11@0+ (1,0) [0|2045] "cm"  MDC
 SG_ UPC_ParkingSlot4_Depth : 31|10@0+ (1,0) [0|1021] "cm"  MDC
 SG_ UPCParkSlot4Point1ObjectType : 34|2@0+ (1,0) [0|3] ""  MDC
 SG_ UPCParkSlot4Point2ObjectType : 74|2@0+ (1,0) [0|3] ""  MDC
 SG_ UPCParkSlot4Point1PositionAngle : 46|7@0+ (1,-64) [-64|63] "degree"  MDC
 SG_ UPCParkSlot4Point2PositionAngle : 62|7@0+ (1,-64) [-64|63] "degree"  MDC
 SG_ UPCParkSlot4Point1PositionX : 71|13@0+ (1,-4095) [-4095|4094] "cm"  MDC
 SG_ UPCParkSlot4Point1PositionY : 87|13@0+ (1,-4095) [-4095|4094] "cm"  MDC
 SG_ UPCParkSlot4Point2PositionX : 103|13@0+ (1,-4095) [-4095|4094] "cm"  MDC
 SG_ UPCParkSlot4Point2PositionY : 119|13@0+ (1,-4095) [-4095|4094] "cm"  MDC
 SG_ UPCParkSlot4PositionUpdateTime : 135|12@0+ (0.5,0) [0|1000] "ms"  MDC
 SG_ UPC_ParkingSlot5_ID : 151|8@0+ (1,0) [0|255] ""  MDC
 SG_ UPC_ParkingSlot5_Status : 164|2@0+ (1,0) [0|3] ""  MDC
 SG_ UPC_ParkingSlot5_Type : 162|3@0+ (1,0) [0|7] ""  MDC
 SG_ UPC_ParkingSlot5_ObjectType : 181|3@0+ (1,0) [0|7] ""  MDC
 SG_ UPC_ParkingSlot5_Length : 159|11@0+ (1,0) [0|2045] "cm"  MDC
 SG_ UPC_ParkingSlot5_Depth : 175|10@0+ (1,0) [0|1021] "cm"  MDC
 SG_ UPCParkSlot5Point1ObjectType : 178|2@0+ (1,0) [0|3] ""  MDC
 SG_ UPCParkSlot5Point2ObjectType : 218|2@0+ (1,0) [0|3] ""  MDC
 SG_ UPCParkSlot5Point1PositionAngle : 190|7@0+ (1,-64) [-64|63] "degree"  MDC
 SG_ UPCParkSlot5Point2PositionAngle : 206|7@0+ (1,-64) [-64|63] "degree"  MDC
 SG_ UPCParkSlot5Point1PositionX : 215|13@0+ (1,-4095) [-4095|4094] "cm"  MDC
 SG_ UPCParkSlot5Point1PositionY : 231|13@0+ (1,-4095) [-4095|4094] "cm"  MDC
 SG_ UPCParkSlot5Point2PositionX : 247|13@0+ (1,-4095) [-4095|4094] "cm"  MDC
 SG_ UPCParkSlot5Point2PositionY : 263|13@0+ (1,-4095) [-4095|4094] "cm"  MDC
 SG_ UPCParkSlot5PositionUpdateTime : 279|12@0+ (0.5,0) [0|1000] "ms"  MDC
 SG_ UPC_ParkingSlot6_ID : 295|8@0+ (1,0) [0|255] ""  MDC
 SG_ UPC_ParkingSlot6_Status : 308|2@0+ (1,0) [0|3] ""  MDC
 SG_ UPC_ParkingSlot6_Type : 306|3@0+ (1,0) [0|7] ""  MDC
 SG_ UPC_ParkingSlot6_ObjectType : 325|3@0+ (1,0) [0|7] ""  MDC
 SG_ UPC_ParkingSlot6_Length : 303|11@0+ (1,0) [0|2045] "cm"  MDC
 SG_ UPC_ParkingSlot6_Depth : 319|10@0+ (1,0) [0|1021] "cm"  MDC
 SG_ UPCParkSlot6Point1ObjectType : 322|2@0+ (1,0) [0|3] ""  MDC
 SG_ UPCParkSlot6Point2ObjectType : 362|2@0+ (1,0) [0|3] ""  MDC
 SG_ UPCParkSlot6Point1PositionAngle : 334|7@0+ (1,-64) [-64|63] "degree"  MDC
 SG_ UPCParkSlot6Point2PositionAngle : 350|7@0+ (1,-64) [-64|63] "degree"  MDC
 SG_ UPCParkSlot6Point1PositionX : 359|13@0+ (1,-4095) [-4095|4094] "cm"  MDC
 SG_ UPCParkSlot6Point1PositionY : 375|13@0+ (1,-4095) [-4095|4094] "cm"  MDC
 SG_ UPCParkSlot6Point2PositionX : 391|13@0+ (1,-4095) [-4095|4094] "cm"  MDC
 SG_ UPCParkSlot6Point2PositionY : 407|13@0+ (1,-4095) [-4095|4094] "cm"  MDC
 SG_ UPCParkSlot6PositionUpdateTime : 423|12@0+ (0.5,0) [0|1000] "ms"  MDC
 SG_ PAS_Slot4_6_Checksum : 511|8@0+ (1,0) [0|255] "bit"  MDC
 SG_ PAS_Slot4_6_RollingCounter : 503|4@0+ (1,0) [0|14] "bit"  MDC

BO_ 626 UPC_ParkingSlot7_8: 48 PAS
 SG_ UPC_ParkingSlot7_ID : 7|8@0+ (1,0) [0|255] ""  MDC
 SG_ UPC_ParkingSlot7_Status : 20|2@0+ (1,0) [0|3] ""  MDC
 SG_ UPC_ParkingSlot7_Type : 18|3@0+ (1,0) [0|7] ""  MDC
 SG_ UPC_ParkingSlot7_ObjectType : 37|3@0+ (1,0) [0|7] ""  MDC
 SG_ UPC_ParkingSlot7_Length : 15|11@0+ (1,0) [0|2045] "cm"  MDC
 SG_ UPC_ParkingSlot7_Depth : 31|10@0+ (1,0) [0|1021] "cm"  MDC
 SG_ UPCParkSlot7Point1ObjectType : 34|2@0+ (1,0) [0|3] ""  MDC
 SG_ UPCParkSlot7Point2ObjectType : 74|2@0+ (1,0) [0|3] ""  MDC
 SG_ UPCParkSlot7Point1PositionAngle : 46|7@0+ (1,-64) [-64|63] "degree"  MDC
 SG_ UPCParkSlot7Point2PositionAngle : 62|7@0+ (1,-64) [-64|63] "degree"  MDC
 SG_ UPCParkSlot7Point1PositionX : 71|13@0+ (1,-4095) [-4095|4094] "cm"  MDC
 SG_ UPCParkSlot7Point1PositionY : 87|13@0+ (1,-4095) [-4095|4094] "cm"  MDC
 SG_ UPCParkSlot7Point2PositionX : 103|13@0+ (1,-4095) [-4095|4094] "cm"  MDC
 SG_ UPCParkSlot7Point2PositionY : 119|13@0+ (1,-4095) [-4095|4094] "cm"  MDC
 SG_ UPCParkSlot7PositionUpdateTime : 135|12@0+ (0.5,0) [0|1000] "ms"  MDC
 SG_ UPC_ParkingSlot8_ID : 151|8@0+ (1,0) [0|255] ""  MDC
 SG_ UPC_ParkingSlot8_Status : 164|2@0+ (1,0) [0|3] ""  MDC
 SG_ UPC_ParkingSlot8_Type : 162|3@0+ (1,0) [0|7] ""  MDC
 SG_ UPC_ParkingSlot8_ObjectType : 181|3@0+ (1,0) [0|7] ""  MDC
 SG_ UPC_ParkingSlot8_Length : 159|11@0+ (1,0) [0|2045] "cm"  MDC
 SG_ UPC_ParkingSlot8_Depth : 175|10@0+ (1,0) [0|1021] "cm"  MDC
 SG_ UPCParkSlot8Point1ObjectType : 178|2@0+ (1,0) [0|3] ""  MDC
 SG_ UPCParkSlot8Point2ObjectType : 218|2@0+ (1,0) [0|3] ""  MDC
 SG_ UPCParkSlot8Point1PositionAngle : 190|7@0+ (1,-64) [-64|63] "degree"  MDC
 SG_ UPCParkSlot8Point2PositionAngle : 206|7@0+ (1,-64) [-64|63] "degree"  MDC
 SG_ UPCParkSlot8Point1PositionX : 215|13@0+ (1,-4095) [-4095|4094] "cm"  MDC
 SG_ UPCParkSlot8Point1PositionY : 231|13@0+ (1,-4095) [-4095|4094] "cm"  MDC
 SG_ UPCParkSlot8Point2PositionX : 247|13@0+ (1,-4095) [-4095|4094] "cm"  MDC
 SG_ UPCParkSlot8Point2PositionY : 263|13@0+ (1,-4095) [-4095|4094] "cm"  MDC
 SG_ UPCParkSlot8PositionUpdateTime : 279|12@0+ (0.5,0) [0|1000] "ms"  MDC
 SG_ PAS_Slot7_8_Checksum : 367|8@0+ (1,0) [0|255] "bit"  MDC
 SG_ PAS_Slot7_8_RollingCounter : 359|4@0+ (1,0) [0|14] "bit" Vector__XXX

BO_ 640 UPC_VehiclePosition: 24 PAS
 SG_ UPC_VehiclePosition_X : 7|16@0+ (0.01,-327.68) [-327.68|327.67] "m"  MDC
 SG_ UPC_VehiclePosition_Y : 23|16@0+ (0.01,-327.68) [-327.68|327.67] "m"  MDC
 SG_ UPCVehiclePositionUpdateTime : 39|12@0+ (0.5,0) [0|1000] "ms"  MDC
 SG_ UPC_VehiclePosition_Curvature : 43|17@0+ (6.103515625E-005,-2) [-2|2] "1/m"  MDC
 SG_ UPC_VehiclePosition_YawAngle : 71|16@0+ (0.000244140625,-3.1415926536) [-3.1415926536|3.1415926536] "rad"  MDC
 SG_ UPCVehiclePositionDriveDistance : 87|16@0+ (0.01,-327.68) [-327.68|327.67] "m"  MDC
 SG_ PAS_VehPos_Checksum : 175|8@0+ (1,0) [0|255] "bit"  MDC
 SG_ PAS_VehPos_RollingCounter : 167|4@0+ (1,0) [0|14] "bit"  MDC

BO_ 641 PAS_PSL: 8 PAS
 SG_ PAS_PSL_Status : 2|3@0+ (1,0) [0|7] ""  MDC
 SG_ PAS_PSL_Checksum : 31|8@0+ (1,0) [0|255] "bit"  MDC
 SG_ PAS_PSL_RollingCounter : 23|4@0+ (1,0) [0|14] "bit"  MDC

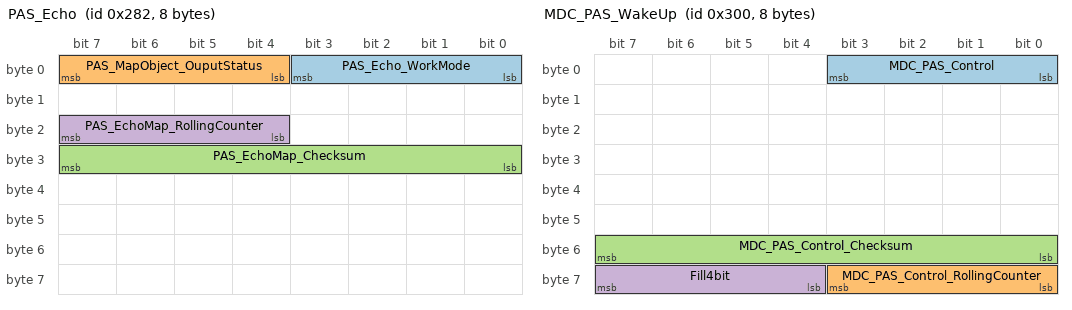
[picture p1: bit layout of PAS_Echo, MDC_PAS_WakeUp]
BO_ 642 PAS_Echo: 8 PAS
 SG_ PAS_Echo_WorkMode : 3|4@0+ (1,0) [0|15] ""  MDC
 SG_ PAS_MapObject_OuputStatus : 7|4@0+ (1,0) [0|15] ""  MDC
 SG_ PAS_EchoMap_Checksum : 31|8@0+ (1,0) [0|255] "bit"  MDC
 SG_ PAS_EchoMap_RollingCounter : 23|4@0+ (1,0) [0|14] "bit"  MDC

BO_ 768 MDC_PAS_WakeUp: 8 MDC
 SG_ MDC_PAS_Control : 3|4@0+ (1,0) [0|3] ""  PAS
 SG_ MDC_PAS_Control_RollingCounter : 59|4@0+ (1,0) [0|15] ""  PAS
 SG_ MDC_PAS_Control_Checksum : 55|8@0+ (1,0) [0|255] "bit"  PAS
 SG_ Fill4bit : 63|4@0+ (1,0) [0|15] "bit"  PAS

BO_ 769 MDC_VehStatus: 48 MDC
 SG_ MDC_ESC_VehicleSpeed : 87|14@0+ (0.1,-100) [-100|500] "KPH"  PAS
 SG_ MDC_ESC_VehicleSpeed_Valid : 108|1@0+ (1,0) [0|1] "bit"  PAS
 SG_ MDC_SAS_SteerWheelAngle : 55|16@0+ (0.1,-780) [-780|780] "°"  PAS
 SG_ MDC_SAS_SteerWheelAngle_Valid : 106|1@0+ (1,0) [0|1] "bit"  PAS
 SG_ MDC_BCM_OutTemp : 71|16@0+ (1,-45) [-45|80] "℃"  PAS
 SG_ MDC_BCM_OutTemp_Valid : 107|1@0+ (1,0) [0|1] "bit"  PAS
 SG_ MDC_VCU_GearStatus : 119|4@0+ (1,0) [0|3] "bit"  PAS
 SG_ MDC_VCU_GearStatus_Valid : 120|1@0+ (1,0) [0|1] "bit"  PAS
 SG_ MDC_ESC_FLWheelSpeedRC : 7|12@0+ (1,0) [0|4095] "bit"  PAS
 SG_ MDC_ESC_FLWheelSpeedRC_Valid : 102|1@0+ (1,0) [0|1] "bit"  PAS
 SG_ MDC_ESC_FRWheelSpeedRC : 11|12@0+ (1,0) [0|4095] "bit"  PAS
 SG_ MDC_ESC_FRWheelSpeedRC_Valid : 103|1@0+ (1,0) [0|1] "bit"  PAS
 SG_ MDC_ESC_RLWheelSpeedRC : 31|12@0+ (1,0) [0|4095] "bit"  PAS
 SG_ MDC_ESC_RLWheelSpeedRC_Valid : 104|1@0+ (1,0) [0|1] "bit"  PAS
 SG_ MDC_ESC_RRWheelSpeedRC : 35|12@0+ (1,0) [0|4095] "bit"  PAS
 SG_ MDC_ESC_RRWheelSpeedRC_Valid : 105|1@0+ (1,0) [0|1] "bit"  PAS
 SG_ MDC_ESC_FLWheelDirection : 89|2@0+ (1,0) [0|3] "bit"  PAS
 SG_ MDC_ESC_FLWheelDirection_Valid : 109|1@0+ (1,0) [0|1] "bit"  PAS
 SG_ MDC_ESC_FRWheelDirection : 97|2@0+ (1,0) [0|3] "bit"  PAS
 SG_ MDC_ESC_FRWheelDirection_Valid : 110|1@0+ (1,0) [0|1] "bit"  PAS
 SG_ MDC_ESC_RLWheelDirection : 99|2@0+ (1,0) [0|3] "bit"  PAS
 SG_ MDC_ESC_RLWheelDirection_Valid : 111|1@0+ (1,0) [0|1] "bit"  PAS
 SG_ MDC_ESC_RRWheelDirection : 101|2@0+ (1,0) [0|3] "bit"  PAS
 SG_ MDC_ESC_RRWheelDirection_Valid : 121|1@0+ (1,0) [0|1] "bit"  PAS
 SG_ MDC_VehStatus_RollingCounter : 155|4@0+ (1,0) [0|15] ""  PAS
 SG_ MDC_VehStatus_Checksum : 151|8@0+ (1,0) [0|255] "bit"  PAS
 SG_ YawRate : 135|16@0+ (0.01,-300) [-300|300] "°/s"  PAS
 SG_ YawRateSensor_St : 122|1@0+ (1,0) [0|1] ""  PAS
 SG_ wheelspeedValid : 167|1@0+ (1,0) [0|1] ""  PAS
 SG_ wheelspeedFl : 166|15@0+ (0.01,-100) [-100|100] "m/s"  PAS
 SG_ wheelspeedFr : 182|15@0+ (0.01,-100) [-100|100] "m/s"  PAS
 SG_ wheelspeedRr : 198|15@0+ (0.01,-100) [-100|100] "m/s"  PAS
 SG_ wheelspeedRl : 214|15@0+ (0.01,-100) [-100|100] "m/s"  PAS
 SG_ ecasVehiclePositionState : 226|3@0+ (1,0) [0|7] "bit" Vector__XXX
 SG_ ecasVehicleUpDownState : 230|3@0+ (1,0) [0|7] "bit" Vector__XXX
 SG_ VehiclePositionStateValid : 227|1@0+ (1,0) [0|1] "bit" Vector__XXX
 SG_ VehicleUpDownStateValid : 231|1@0+ (1,0) [0|1] "bit" Vector__XXX

BO_ 770 PAS_SonarMode_Req: 12 MDC
 SG_ PAS_Sonar1_Req : 7|2@0+ (1,0) [0|2] ""  PAS
 SG_ PAS_Sonar1_Req_counter : 5|4@0+ (1,0) [0|15] ""  PAS
 SG_ PAS_Sonar2_Req : 1|2@0+ (1,0) [0|2] ""  PAS
 SG_ PAS_Sonar2_Req_counter : 15|4@0+ (1,0) [0|15] ""  PAS
 SG_ PAS_Sonar3_Req : 11|2@0+ (1,0) [0|2] ""  PAS
 SG_ PAS_Sonar3_Req_counter : 9|4@0+ (1,0) [0|15] ""  PAS
 SG_ PAS_Sonar4_Req : 21|2@0+ (1,0) [0|2] ""  PAS
 SG_ PAS_Sonar4_Req_counter : 19|4@0+ (1,0) [0|15] ""  PAS
 SG_ PAS_Sonar7_Req : 31|2@0+ (1,0) [0|2] ""  PAS
 SG_ PAS_Sonar7_Req_counter : 29|4@0+ (1,0) [0|15] ""  PAS
 SG_ PAS_Sonar8_Req : 25|2@0+ (1,0) [0|2] ""  PAS
 SG_ PAS_Sonar8_Req_counter : 39|4@0+ (1,0) [0|15] ""  PAS
 SG_ PAS_Sonar9_Req : 35|2@0+ (1,0) [0|2] ""  PAS
 SG_ PAS_Sonar9_Req_counter : 33|4@0+ (1,0) [0|15] ""  PAS
 SG_ PAS_Sonar10_Req : 45|2@0+ (1,0) [0|2] ""  PAS
 SG_ PAS_Sonar10_Req_counter : 43|4@0+ (1,0) [0|15] ""  PAS
 SG_ PAS_Sonar0_Req : 55|2@0+ (1,0) [0|2] ""  PAS
 SG_ PAS_Sonar0_Req_counter : 53|4@0+ (1,0) [0|15] ""  PAS
 SG_ PAS_Sonar5_Req : 49|2@0+ (1,0) [0|2] ""  PAS
 SG_ PAS_Sonar5_Req_counter : 63|4@0+ (1,0) [0|15] ""  PAS
 SG_ PAS_Sonar6_Req : 59|2@0+ (1,0) [0|2] ""  PAS
 SG_ PAS_Sonar6_Req_counter : 57|4@0+ (1,0) [0|15] ""  PAS
 SG_ PAS_Sonar11_Req : 69|2@0+ (1,0) [0|2] ""  PAS
 SG_ PAS_Sonar11_Req_counter : 67|4@0+ (1,0) [0|15] ""  PAS
 SG_ Sonar_Req_RollingCounter : 91|4@0+ (1,0) [0|15] ""  PAS
 SG_ Sonar_Req_Checksum : 87|8@0+ (1,0) [0|255] "bit"  PAS
 SG_ Fill4bit : 95|4@0+ (1,0) [0|15] "bit"  PAS
 SG_ PAS_Function_Req : 74|3@0+ (1,0) [0|7] "bit"  PAS

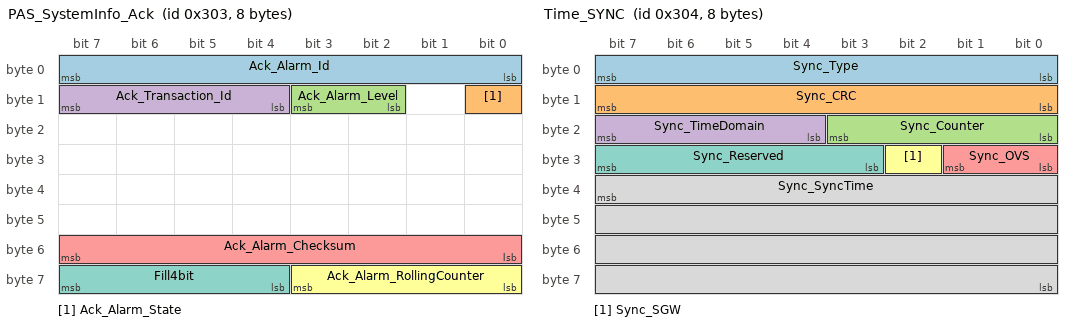
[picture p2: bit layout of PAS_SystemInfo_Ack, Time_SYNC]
BO_ 771 PAS_SystemInfo_Ack: 8 MDC
 SG_ Ack_Alarm_Id : 7|8@0+ (1,0) [0|255] "bit"  PAS
 SG_ Ack_Alarm_State : 8|1@0+ (1,0) [0|1] "bit"  PAS
 SG_ Ack_Alarm_Level : 11|2@0+ (1,0) [0|2] "bit"  PAS
 SG_ Ack_Transaction_Id : 15|4@0+ (1,0) [0|15] "bit"  PAS
 SG_ Ack_Alarm_Checksum : 55|8@0+ (1,0) [0|255] "bit"  PAS
 SG_ Ack_Alarm_RollingCounter : 59|4@0+ (1,0) [0|15] "bit"  PAS
 SG_ Fill4bit : 63|4@0+ (1,0) [0|15] "bit"  PAS

BO_ 772 Time_SYNC: 8 MDC
 SG_ Sync_Type : 7|8@0+ (1,0) [0|255] ""  PAS
 SG_ Sync_CRC : 15|8@0+ (1,0) [0|255] ""  PAS
 SG_ Sync_Counter : 19|4@0+ (1,0) [0|15] ""  PAS
 SG_ Sync_TimeDomain : 23|4@0+ (1,0) [0|15] ""  PAS
 SG_ Sync_OVS : 25|2@0+ (1,0) [0|3] ""  PAS
 SG_ Sync_SGW : 26|1@0+ (1,0) [0|1] ""  PAS
 SG_ Sync_Reserved : 31|5@0+ (1,0) [0|31] ""  PAS
 SG_ Sync_SyncTime : 39|32@0+ (1,0) [0|4294967295] ""  PAS

BO_ 928 MDC_Challenge_M1: 12 MDC
 SG_ MDC_RandomByte1 : 7|8@0+ (1,0) [0|255] ""  PAS
 SG_ MDC_RandomByte2 : 15|8@0+ (1,0) [0|255] ""  PAS
 SG_ MDC_RandomByte3 : 23|8@0+ (1,0) [0|255] ""  PAS
 SG_ MDC_RandomByte4 : 31|8@0+ (1,0) [0|255] ""  PAS
 SG_ MDC_RandomByte5 : 39|8@0+ (1,0) [0|255] ""  PAS
 SG_ MDC_RandomByte6 : 47|8@0+ (1,0) [0|255] ""  PAS
 SG_ MDC_RandomByte7 : 55|8@0+ (1,0) [0|255] ""  PAS
 SG_ MDC_RandomByte8 : 63|8@0+ (1,0) [0|255] ""  PAS
 SG_ MDC_SessionID : 71|8@0+ (1,0) [0|255] ""  PAS

BO_ 929 MDC_Response_CMAC_M2: 12 MDC
 SG_ MDC_Response_Result : 2|3@0+ (1,0) [0|1] ""  PAS
 SG_ MDC_Response_SessionID : 15|8@0+ (1,0) [0|255] ""  PAS
 SG_ MDC_Response_CMACByte1 : 23|8@0+ (1,0) [0|255] ""  PAS
 SG_ MDC_Response_CMACByte2 : 31|8@0+ (1,0) [0|255] ""  PAS
 SG_ MDC_Response_CMACByte3 : 39|8@0+ (1,0) [0|255] ""  PAS
 SG_ MDC_Response_CMACByte4 : 47|8@0+ (1,0) [0|255] ""  PAS
 SG_ MDC_Response_CMACByte5 : 55|8@0+ (1,0) [0|255] ""  PAS
 SG_ MDC_Response_CMACByte6 : 63|8@0+ (1,0) [0|255] ""  PAS
 SG_ MDC_Response_CMACByte7 : 71|8@0+ (1,0) [0|255] ""  PAS
 SG_ MDC_Response_CMACByte8 : 79|8@0+ (1,0) [0|255] ""  PAS

BO_ 960 Mdc_KeyLearn_Status: 64 MDC
 SG_ Mdc_KeyLearnSubID : 7|8@0+ (1,0) [0|7] ""  PAS
 SG_ Mdc_KeyLearn_Numbers : 15|8@0+ (1,0) [1|12] ""  PAS
 SG_ Mdc_KeyLearn_SKID1 : 23|8@0+ (1,0) [1|12] ""  PAS
 SG_ Mdc_KeyLearn_SKID2 : 31|8@0+ (1,0) [1|12] ""  PAS
 SG_ Mdc_KeyLearn_SKID3 : 39|8@0+ (1,0) [1|12] ""  PAS
 SG_ Mdc_KeyLearn_SKID4 : 47|8@0+ (1,0) [1|12] ""  PAS
 SG_ Mdc_KeyLearn_SKID5 : 55|8@0+ (1,0) [1|12] ""  PAS
 SG_ Mdc_KeyLearn_SKID6 : 63|8@0+ (1,0) [1|12] ""  PAS
 SG_ Mdc_KeyLearn_SKID7 : 71|8@0+ (1,0) [1|12] ""  PAS
 SG_ Mdc_KeyLearn_SKID8 : 79|8@0+ (1,0) [1|12] ""  PAS
 SG_ Mdc_KeyLearn_SKID9 : 87|8@0+ (1,0) [1|12] ""  PAS
 SG_ Mdc_KeyLearn_SKID10 : 95|8@0+ (1,0) [1|12] ""  PAS
 SG_ Mdc_KeyLearn_SKID11 : 103|8@0+ (1,0) [1|12] ""  PAS
 SG_ Mdc_KeyLearn_SKID12 : 111|8@0+ (1,0) [1|12] ""  PAS

BO_ 962 Mdc_KeyLearn_SendSKCSC: 64 MDC
 SG_ Mdc_KeyLearnSubID_Send : 7|8@0+ (1,0) [0|7] ""  PAS
 SG_ Mdc_KeyLearn_transmit_SKID : 15|8@0+ (1,0) [1|12] ""  PAS
 SG_ Mdc_KeyLearn_update_SKID : 23|8@0+ (1,0) [1|12] ""  PAS
 SG_ Mdc_KeyLearn_SKCByte1 : 31|8@0+ (1,0) [0|255] ""  PAS
 SG_ Mdc_KeyLearn_SKCByte2 : 39|8@0+ (1,0) [0|255] ""  PAS
 SG_ Mdc_KeyLearn_SKCByte3 : 47|8@0+ (1,0) [0|255] ""  PAS
 SG_ Mdc_KeyLearn_SKCByte4 : 55|8@0+ (1,0) [0|255] ""  PAS
 SG_ Mdc_KeyLearn_SKCByte5 : 63|8@0+ (1,0) [0|255] ""  PAS
 SG_ Mdc_KeyLearn_SKCByte6 : 71|8@0+ (1,0) [0|255] ""  PAS
 SG_ Mdc_KeyLearn_SKCByte7 : 79|8@0+ (1,0) [0|255] ""  PAS
 SG_ Mdc_KeyLearn_SKCByte8 : 87|8@0+ (1,0) [0|255] ""  PAS
 SG_ Mdc_KeyLearn_SKCByte9 : 95|8@0+ (1,0) [0|255] ""  PAS
 SG_ Mdc_KeyLearn_SKCByte10 : 103|8@0+ (1,0) [0|255] ""  PAS
 SG_ Mdc_KeyLearn_SKCByte11 : 111|8@0+ (1,0) [0|255] ""  PAS
 SG_ Mdc_KeyLearn_SKCByte12 : 119|8@0+ (1,0) [0|255] ""  PAS
 SG_ Mdc_KeyLearn_SKCByte13 : 127|8@0+ (1,0) [0|255] ""  PAS
 SG_ Mdc_KeyLearn_SKCByte14 : 135|8@0+ (1,0) [0|255] ""  PAS
 SG_ Mdc_KeyLearn_SKCByte15 : 143|8@0+ (1,0) [0|255] ""  PAS
 SG_ Mdc_KeyLearn_SKCByte16 : 151|8@0+ (1,0) [0|255] ""  PAS
 SG_ Mdc_KeyLearn_MACByte1 : 159|8@0+ (1,0) [0|255] ""  PAS
 SG_ Mdc_KeyLearn_MACByte2 : 167|8@0+ (1,0) [0|255] ""  PAS
 SG_ Mdc_KeyLearn_MACByte3 : 175|8@0+ (1,0) [0|255] ""  PAS
 SG_ Mdc_KeyLearn_MACByte4 : 183|8@0+ (1,0) [0|255] ""  PAS
 SG_ Mdc_KeyLearn_MACByte5 : 191|8@0+ (1,0) [0|255] ""  PAS
 SG_ Mdc_KeyLearn_MACByte6 : 199|8@0+ (1,0) [0|255] ""  PAS
 SG_ Mdc_KeyLearn_MACByte7 : 207|8@0+ (1,0) [0|255] ""  PAS
 SG_ Mdc_KeyLearn_MACByte8 : 215|8@0+ (1,0) [0|255] ""  PAS
 SG_ Mdc_KeyLearn_MACByte9 : 223|8@0+ (1,0) [0|255] ""  PAS
 SG_ Mdc_KeyLearn_MACByte10 : 231|8@0+ (1,0) [0|255] ""  PAS
 SG_ Mdc_KeyLearn_MACByte11 : 239|8@0+ (1,0) [0|255] ""  PAS
 SG_ Mdc_KeyLearn_MACByte12 : 247|8@0+ (1,0) [0|255] ""  PAS
 SG_ Mdc_KeyLearn_MACByte13 : 255|8@0+ (1,0) [0|255] ""  PAS
 SG_ Mdc_KeyLearn_MACByte14 : 263|8@0+ (1,0) [0|255] ""  PAS
 SG_ Mdc_KeyLearn_MACByte15 : 271|8@0+ (1,0) [0|255] ""  PAS
 SG_ Mdc_KeyLearn_MACByte16 : 279|8@0+ (1,0) [0|255] ""  PAS
 SG_ Mdc_KeyLearn_IVByte1 : 287|8@0+ (1,0) [0|255] ""  PAS
 SG_ Mdc_KeyLearn_IVByte2 : 295|8@0+ (1,0) [0|255] ""  PAS
 SG_ Mdc_KeyLearn_IVByte3 : 303|8@0+ (1,0) [0|255] ""  PAS
 SG_ Mdc_KeyLearn_IVByte4 : 311|8@0+ (1,0) [0|255] ""  PAS
 SG_ Mdc_KeyLearn_IVByte5 : 319|8@0+ (1,0) [0|255] ""  PAS
 SG_ Mdc_KeyLearn_IVByte6 : 327|8@0+ (1,0) [0|255] ""  PAS
 SG_ Mdc_KeyLearn_IVByte7 : 335|8@0+ (1,0) [0|255] ""  PAS
 SG_ Mdc_KeyLearn_IVByte8 : 343|8@0+ (1,0) [0|255] ""  PAS
 SG_ Mdc_KeyLearn_IVByte9 : 351|8@0+ (1,0) [0|255] ""  PAS
 SG_ Mdc_KeyLearn_IVByte10 : 359|8@0+ (1,0) [0|255] ""  PAS
 SG_ Mdc_KeyLearn_IVByte11 : 367|8@0+ (1,0) [0|255] ""  PAS
 SG_ Mdc_KeyLearn_IVByte12 : 375|8@0+ (1,0) [0|255] ""  PAS
 SG_ Mdc_KeyLearn_SC : 383|24@0+ (1,0) [0|16777215] ""  PAS

BO_ 963 Mdc_KeyLearn_SKSetting: 64 MDC
 SG_ Mdc_KeyLearnSubID_SKSetting : 7|8@0+ (1,0) [0|7] ""  PAS
 SG_ Mdc_KeyLearn_SKID : 15|8@0+ (1,0) [1|12] ""  PAS

BO_ 964 Mdc_KeyLearn_Clean: 64 MDC
 SG_ Mdc_KeyLearnSubID_CleanID : 7|8@0+ (1,0) [0|7] ""  PAS
 SG_ Mdc_KeyLearn_Clean_SKID : 15|8@0+ (1,0) [1|12] ""  PAS
 SG_ Mdc_KeyLearn_Clean_SCByte1 : 23|8@0+ (1,0) [0|255] ""  PAS
 SG_ Mdc_KeyLearn_Clean_SCByte2 : 31|8@0+ (1,0) [0|255] ""  PAS
 SG_ Mdc_KeyLearn_Clean_SCByte3 : 39|8@0+ (1,0) [0|255] ""  PAS
 SG_ Mdc_KeyLearn_Clean_SCByte4 : 47|8@0+ (1,0) [0|255] ""  PAS
 SG_ Mdc_KeyLearn_Clean_SCByte5 : 55|8@0+ (1,0) [0|255] ""  PAS
 SG_ Mdc_KeyLearn_Clean_SCByte6 : 63|8@0+ (1,0) [0|255] ""  PAS
 SG_ Mdc_KeyLearn_Clean_SCByte7 : 71|8@0+ (1,0) [0|255] ""  PAS
 SG_ Mdc_KeyLearn_Clean_SCByte8 : 79|8@0+ (1,0) [0|255] ""  PAS
 SG_ Mdc_KeyLearn_Clean_SCByte9 : 87|8@0+ (1,0) [0|255] ""  PAS
 SG_ Mdc_KeyLearn_Clean_SCByte10 : 95|8@0+ (1,0) [0|255] ""  PAS
 SG_ Mdc_KeyLearn_Clean_SCByte11 : 103|8@0+ (1,0) [0|255] ""  PAS
 SG_ Mdc_KeyLearn_Clean_SCByte12 : 111|8@0+ (1,0) [0|255] ""  PAS
 SG_ Mdc_KeyLearn_Clean_SCByte13 : 119|8@0+ (1,0) [0|255] ""  PAS
 SG_ Mdc_KeyLearn_Clean_SCByte14 : 127|8@0+ (1,0) [0|255] ""  PAS
 SG_ Mdc_KeyLearn_Clean_SCByte15 : 135|8@0+ (1,0) [0|255] ""  PAS
 SG_ Mdc_KeyLearn_Clean_SCByte16 : 143|8@0+ (1,0) [0|255] ""  PAS
 SG_ Mdc_KeyLearn_Clean_MACByte1 : 151|8@0+ (1,0) [0|255] ""  PAS
 SG_ Mdc_KeyLearn_Clean_MACByte2 : 159|8@0+ (1,0) [0|255] ""  PAS
 SG_ Mdc_KeyLearn_Clean_MACByte3 : 167|8@0+ (1,0) [0|255] ""  PAS
 SG_ Mdc_KeyLearn_Clean_MACByte4 : 175|8@0+ (1,0) [0|255] ""  PAS
 SG_ Mdc_KeyLearn_Clean_MACByte5 : 183|8@0+ (1,0) [0|255] ""  PAS
 SG_ Mdc_KeyLearn_Clean_MACByte6 : 191|8@0+ (1,0) [0|255] ""  PAS
 SG_ Mdc_KeyLearn_Clean_MACByte7 : 199|8@0+ (1,0) [0|255] ""  PAS
 SG_ Mdc_KeyLearn_Clean_MACByte8 : 207|8@0+ (1,0) [0|255] ""  PAS
 SG_ Mdc_KeyLearn_Clean_MACByte9 : 215|8@0+ (1,0) [0|255] ""  PAS
 SG_ Mdc_KeyLearn_Clean_MACByte10 : 223|8@0+ (1,0) [0|255] ""  PAS
 SG_ Mdc_KeyLearn_Clean_MACByte11 : 231|8@0+ (1,0) [0|255] ""  PAS
 SG_ Mdc_KeyLearn_Clean_MACByte12 : 239|8@0+ (1,0) [0|255] ""  PAS
 SG_ Mdc_KeyLearn_Clean_MACByte13 : 247|8@0+ (1,0) [0|255] ""  PAS
 SG_ Mdc_KeyLearn_Clean_MACByte14 : 255|8@0+ (1,0) [0|255] ""  PAS
 SG_ Mdc_KeyLearn_Clean_MACByte15 : 263|8@0+ (1,0) [0|255] ""  PAS
 SG_ Mdc_KeyLearn_Clean_MACByte16 : 271|8@0+ (1,0) [0|255] ""  PAS
 SG_ Mdc_KeyLearn_Clean_IVByte1 : 279|8@0+ (1,0) [0|255] ""  PAS
 SG_ Mdc_KeyLearn_Clean_IVByte2 : 287|8@0+ (1,0) [0|255] ""  PAS
 SG_ Mdc_KeyLearn_Clean_IVByte3 : 295|8@0+ (1,0) [0|255] ""  PAS
 SG_ Mdc_KeyLearn_Clean_IVByte4 : 303|8@0+ (1,0) [0|255] ""  PAS
 SG_ Mdc_KeyLearn_Clean_IVByte5 : 311|8@0+ (1,0) [0|255] ""  PAS
 SG_ Mdc_KeyLearn_Clean_IVByte6 : 319|8@0+ (1,0) [0|255] ""  PAS
 SG_ Mdc_KeyLearn_Clean_IVByte7 : 327|8@0+ (1,0) [0|255] ""  PAS
 SG_ Mdc_KeyLearn_Clean_IVByte8 : 335|8@0+ (1,0) [0|255] ""  PAS
 SG_ Mdc_KeyLearn_Clean_IVByte9 : 343|8@0+ (1,0) [0|255] ""  PAS
 SG_ Mdc_KeyLearn_Clean_IVByte10 : 351|8@0+ (1,0) [0|255] ""  PAS
 SG_ Mdc_KeyLearn_Clean_IVByte11 : 359|8@0+ (1,0) [0|255] ""  PAS
 SG_ Mdc_KeyLearn_Clean_IVByte12 : 367|8@0+ (1,0) [0|255] ""  PAS

BO_ 961 Mdc_Verify_Random: 64 MDC
 SG_ Mdc_VerifySubID_Random : 7|8@0+ (1,0) [0|2] ""  PAS
 SG_ Mdc_Verify_SKID : 15|8@0+ (1,0) [1|12] ""  PAS
 SG_ Mdc_Verify_Random : 23|32@0+ (1,0) [0|4294967295] ""  PAS

BO_ 965 Mdc_Verify_Result: 64 MDC
 SG_ Mdc_Verify_ResultID : 7|8@0+ (1,0) [0|2] ""  PAS
 SG_ Mdc_Verify_Result_SKID : 15|8@0+ (1,0) [1|12] ""  PAS
 SG_ Mdc_Verify_Result_Status : 23|8@0+ (1,0) [0|1] ""  PAS

BO_ 773 Mdc_Sensor_Version: 8 MDC
 SG_ sensorVersion : 7|8@0+ (1,0) [0|255] "bit"  PAS

CM_ SG_ 517 PAS_Sonar6_Echo_TOF1 "第一次回波时间";
CM_ SG_ 517 PAS_Sonar6_Echo_Width1 "第一次回波宽度";
CM_ SG_ 517 PAS_Sonar6_Echo_TOF2 "第二次回波时间";
CM_ SG_ 517 PAS_Sonar6_Echo_Width2 "第二次回波宽度";
CM_ SG_ 517 PAS_Sonar6_Echo_Peak1 "第一次回波高度";
CM_ SG_ 517 PAS_Sonar6_Echo_Peak2 "第二次回波高度";
CM_ SG_ 517 PAS_Sonar6_Emit "对应探头是否发波";
CM_ SG_ 517 PAS_Sonar6_RingingTime "余振时间";
CM_ SG_ 517 PAS_Sonar6_Counter "探头工作计数器";
CM_ SG_ 517 PAS_Sonar7_Echo_TOF1 "第一次回波时间";
CM_ SG_ 517 PAS_Sonar7_Echo_Width1 "第一次回波宽度";
CM_ SG_ 517 PAS_Sonar7_Echo_TOF2 "第二次回波时间";
CM_ SG_ 517 PAS_Sonar7_Echo_Width2 "第二次回波宽度";
CM_ SG_ 517 PAS_Sonar7_Echo_Peak1 "第一次回波高度";
CM_ SG_ 517 PAS_Sonar7_Echo_Peak2 "第二次回波高度";
CM_ SG_ 517 PAS_Sonar7_Emit "对应探头是否发波";
CM_ SG_ 517 PAS_Sonar7_RingingTime "余振时间";
CM_ SG_ 517 PAS_Sonar7_Counter "探头工作计数器";
CM_ SG_ 517 PAS_Sonar8_Echo_TOF1 "第一次回波时间";
CM_ SG_ 517 PAS_Sonar8_Echo_Width1 "第一次回波宽度";
CM_ SG_ 517 PAS_Sonar8_Echo_TOF2 "第二次回波时间";
CM_ SG_ 517 PAS_Sonar8_Echo_Width2 "第二次回波宽度";
CM_ SG_ 517 PAS_Sonar8_Echo_Peak1 "第一次回波高度";
CM_ SG_ 517 PAS_Sonar8_Echo_Peak2 "第二次回波高度";
CM_ SG_ 517 PAS_Sonar8_Emit "对应探头是否发波";
CM_ SG_ 517 PAS_Sonar8_RingingTime "余振时间";
CM_ SG_ 517 PAS_Sonar8_Counter "探头工作计数器";
CM_ SG_ 517 PAS_Sonar9_Echo_TOF1 "第一次回波时间";
CM_ SG_ 517 PAS_Sonar9_Echo_Width1 "第一次回波宽度";
CM_ SG_ 517 PAS_Sonar9_Echo_TOF2 "第二次回波时间";
CM_ SG_ 517 PAS_Sonar9_Echo_Width2 "第二次回波宽度";
CM_ SG_ 517 PAS_Sonar9_Echo_Peak1 "第一次回波高度";
CM_ SG_ 517 PAS_Sonar9_Echo_Peak2 "第二次回波高度";
CM_ SG_ 517 PAS_Sonar9_Emit "对应探头是否发波";
CM_ SG_ 517 PAS_Sonar9_RingingTime "余振时间";
CM_ SG_ 517 PAS_Sonar9_Counter "探头工作计数器";
CM_ SG_ 517 PAS_Sonar10_Echo_TOF1 "第一次回波时间";
CM_ SG_ 517 PAS_Sonar10_Echo_Width1 "第一次回波宽度";
CM_ SG_ 517 PAS_Sonar10_Echo_TOF2 "第二次回波时间";
CM_ SG_ 517 PAS_Sonar10_Echo_Width2 "第二次回波宽度";
CM_ SG_ 517 PAS_Sonar10_Echo_Peak1 "第一次回波高度";
CM_ SG_ 517 PAS_Sonar10_Echo_Peak2 "第二次回波高度";
CM_ SG_ 517 PAS_Sonar10_Emit "对应探头是否发波";
CM_ SG_ 517 PAS_Sonar10_RingingTime "余振时间";
CM_ SG_ 517 PAS_Sonar10_Counter "探头工作计数器";
CM_ SG_ 517 PAS_Sonar11_Echo_TOF1 "第一次回波时间";
CM_ SG_ 517 PAS_Sonar11_Echo_Width1 "第一次回波宽度";
CM_ SG_ 517 PAS_Sonar11_Echo_TOF2 "第二次回波时间";
CM_ SG_ 517 PAS_Sonar11_Echo_Width2 "第二次回波宽度";
CM_ SG_ 517 PAS_Sonar11_Echo_Peak1 "第一次回波高度";
CM_ SG_ 517 PAS_Sonar11_Echo_Peak2 "第二次回波高度";
CM_ SG_ 517 PAS_Sonar11_Emit "对应探头是否发波";
CM_ SG_ 517 PAS_Sonar11_RingingTime "余振时间";
CM_ SG_ 517 PAS_Sonar11_Counter "探头工作计数器";
CM_ SG_ 517 PASSonarInfoRearRollingCounter "消息计数器";
CM_ SG_ 517 PAS_SonarInfo_Rear_Checksum "校验码";
CM_ SG_ 517 Fill4bit "填充位";
CM_ SG_ 544 PAS_WakeUp_Response "反馈是否收到MDC的唤醒报文（0x300）";
CM_ SG_ 544 PAS_SonarMode_Response "反馈是否收到MDC的探头工作模式指令（0x302）";
CM_ SG_ 544 PAS_Response_RollingCounter "消息计数器";
CM_ SG_ 544 PAS_Response_Checksum "校验码";
CM_ SG_ 544 Fill4bit "填充位";
CM_ SG_ 560 PAS_SensorStsLR_FLS "左前长距离传感器工作状态";
CM_ SG_ 560 PAS_SensorStsLR_FRS "右前长距离传感器工作状态";
CM_ SG_ 560 PAS_SensorStsSR_FL "左前短距离传感器工作状态";
CM_ SG_ 560 PAS_SensorStsSR_FML "左中前短距离传感器工作状态";
CM_ SG_ 560 PAS_SensorStsSR_FMR "右中前短距离传感器工作状态";
CM_ SG_ 560 PAS_SensorStsSR_FR "右前短距离传感器工作状态";
CM_ SG_ 560 PAS_SensorStsLR_RLS "左后长距离传感器工作状态";
CM_ SG_ 560 PAS_SensorStsLR_RRS "右后长距离传感器工作状态";
CM_ SG_ 560 PAS_SensorStsSR_RL "左后短距离传感器工作状态";
CM_ SG_ 560 PAS_SensorStsSR_RML "左中后短距离传感器工作状态";
CM_ SG_ 560 PAS_SensorStsSR_RMR "右中后短距离传感器工作状态";
CM_ SG_ 560 PAS_SensorStsSR_RR "右后短距离传感器工作状态";
CM_ SG_ 560 PAS_ECU_Status "ECU工作状态";
CM_ SG_ 560 PAS_ECU_VehStatus_Reponse "反馈是否接受的车辆状态信息";
CM_ SG_ 560 sensorVersion_Status "反馈是否收到传感器版本信息（0x305）";
CM_ SG_ 560 PAS_SensorStatus_RollingCounter "消息计数器";
CM_ SG_ 560 PAS_SensorStatus_Checksum "校验码";
CM_ SG_ 560 Fill4bit "填充位";
CM_ SG_ 576 PAS_ECU_Information_Ver_Hard "ECU 硬件版本";
CM_ SG_ 576 PAS_ECU_Information_Ver_Soft "ECU 软件版本";
CM_ SG_ 576 PAS_ECU_Information_Ver_Boot "ECU Boot版本";
CM_ SG_ 576 PAS_ECU_Information_Date_Year "升级版本年";
CM_ SG_ 576 PAS_ECU_Information_Date_Month "升级版本月";
CM_ SG_ 576 PAS_ECU_Information_Date_Day "升级版本日";
CM_ SG_ 576 PAS_ECU_Version_Checksum "校验码";
CM_ SG_ 576 PAS_ECUInfo_RollingCounter "消息计数器";
CM_ SG_ 576 Fill4bit "填充位";
CM_ SG_ 592 Rpt_Alarm_Id "告警Id";
CM_ SG_ 592 Rpt_Alarm_State "告警状态";
CM_ SG_ 592 Rpt_Alarm_Level "告警级别";
CM_ SG_ 592 Rpt_Transaction_Id "告警序列号-本质是记录故障发生几次后才得到303应答";
CM_ SG_ 592 Rpt_Alarm_Para1 "告警描述参数1(电压值)";
CM_ SG_ 592 Rpt_Alarm_Para2 "告警描述参数2";
CM_ SG_ 592 Rpt_Alarm_Para3 "告警描述参数3";
CM_ SG_ 592 Rpt_Alarm_Checksum "校验码";
CM_ SG_ 592 Rpt_Alarm_RollingCounter "消息计数器";
CM_ SG_ 592 Fill4bit "填充位";
CM_ SG_ 593 PAS_Sonar1_ControlBusFailure "控制器通信是否失败";
CM_ SG_ 593 PAS_Sonar1_RingingTimeFailure "余震时间是否正常";
CM_ SG_ 593 PAS_Sonar1_ShortToGND "信号线是否对地短路或信号线断开";
CM_ SG_ 593 PAS_Sonar1_ShortToPositivePole "信号线是否对Ubat短路或电源GND开路";
CM_ SG_ 593 PAS_Sonar1_TypeMismatch "探头类型不匹配";
CM_ SG_ 593 PAS_Sonar2_ControlBusFailure "控制器通信是否失败";
CM_ SG_ 593 PAS_Sonar2_RingingTimeFailure "余震时间是否正常";
CM_ SG_ 593 PAS_Sonar2_ShortToGND "是否对地短路或信号线断开";
CM_ SG_ 593 PAS_Sonar2_ShortToPositivePole "是否对Ubat短路或GND开路";
CM_ SG_ 593 PAS_Sonar2_TypeMismatch "探头类型不匹配";
CM_ SG_ 593 PAS_Sonar3_ControlBusFailure "控制器通信是否失败";
CM_ SG_ 593 PAS_Sonar3_RingingTimeFailure "余震时间是否正常";
CM_ SG_ 593 PAS_Sonar3_ShortToGND "是否对地短路或信号线断开";
CM_ SG_ 593 PAS_Sonar3_ShortToPositivePole "是否对Ubat短路或GND开路";
CM_ SG_ 593 PAS_Sonar3_TypeMismatch "探头类型不匹配";
CM_ SG_ 593 PAS_Sonar3_PowerVoltage_Low "供电电压过低";
CM_ SG_ 593 PAS_Sonar3_PowerVoltage_High "供电电压过高";
CM_ SG_ 593 PAS_Sonar4_ControlBusFailure "控制器通信是否失败";
CM_ SG_ 593 PAS_Sonar4_RingingTimeFailure "余震时间是否正常";
CM_ SG_ 593 PAS_Sonar4_ShortToGND "是否对地短路或信号线断开";
CM_ SG_ 593 PAS_Sonar4_ShortToPositivePole "是否对Ubat短路或GND开路";
CM_ SG_ 593 PAS_Sonar4_TypeMismatch "探头类型不匹配";
CM_ SG_ 593 PAS_Sonar7_ControlBusFailure "控制器通信是否失败";
CM_ SG_ 593 PAS_Sonar7_RingingTimeFailure "余震时间是否正常";
CM_ SG_ 593 PAS_Sonar7_ShortToGND "是否对地短路或信号线断开";
CM_ SG_ 593 PAS_Sonar7_ShortToPositivePole "是否对Ubat短路或GND开路";
CM_ SG_ 593 PAS_Sonar7_TypeMismatch "探头类型不匹配";
CM_ SG_ 593 PAS_Sonar8_ControlBusFailure "控制器通信是否失败";
CM_ SG_ 593 PAS_Sonar8_RingingTimeFailure "余震时间是否正常";
CM_ SG_ 593 PAS_Sonar8_ShortToGND "是否对地短路或信号线断开";
CM_ SG_ 593 PAS_Sonar8_ShortToPositivePole "是否对Ubat短路或GND开路";
CM_ SG_ 593 PAS_Sonar8_TypeMismatch "探头类型不匹配";
CM_ SG_ 593 PAS_Sonar9_ControlBusFailure "控制器通信是否失败";
CM_ SG_ 593 PAS_Sonar9_RingingTimeFailure "余震时间是否正常";
CM_ SG_ 593 PAS_Sonar9_ShortToGND "是否对地短路或信号线断开";
CM_ SG_ 593 PAS_Sonar9_ShortToPositivePole "是否对Ubat短路或GND开路";
CM_ SG_ 593 PAS_Sonar9_TypeMismatch "探头类型不匹配";
CM_ SG_ 593 PAS_Sonar10_ControlBusFailure "控制器通信是否失败";
CM_ SG_ 593 PAS_Sonar10_RingingTimeFailure "余震时间是否正常";
CM_ SG_ 593 PAS_Sonar10_ShortToGND "是否对地短路或信号线断开";
CM_ SG_ 593 PAS_Sonar10_ShortToPositivePole "是否对Ubat短路或GND开路";
CM_ SG_ 593 PAS_Sonar10_TypeMismatch "探头类型不匹配";
CM_ SG_ 593 PAS_Sonar0_ControlBusFailure "控制器通信是否失败";
CM_ SG_ 593 PAS_Sonar0_RingingTimeFailure "余震时间是否正常";
CM_ SG_ 593 PAS_Sonar0_ShortToGND "是否对地短路或信号线断开";
CM_ SG_ 593 PAS_Sonar0_ShortToPositivePole "是否对Ubat短路或GND开路";
CM_ SG_ 593 PAS_Sonar0_TypeMismatch "探头类型不匹配";
CM_ SG_ 593 PAS_Sonar5_ControlBusFailure "控制器通信是否失败";
CM_ SG_ 593 PAS_Sonar5_RingingTimeFailure "余震时间是否正常";
CM_ SG_ 593 PAS_Sonar5_ShortToGND "是否对地短路或信号线断开";
CM_ SG_ 593 PAS_Sonar5_ShortToPositivePole "是否对Ubat短路或GND开路";
CM_ SG_ 593 PAS_Sonar5_TypeMismatch "探头类型不匹配";
CM_ SG_ 593 PAS_Sonar6_ControlBusFailure "控制器通信是否失败";
CM_ SG_ 593 PAS_Sonar6_RingingTimeFailure "余震时间是否正常";
CM_ SG_ 593 PAS_Sonar6_ShortToGND "是否对地短路或信号线断开";
CM_ SG_ 593 PAS_Sonar6_ShortToPositivePole "是否对Ubat短路或GND开路";
CM_ SG_ 593 PAS_Sonar6_TypeMismatch "探头类型不匹配";
CM_ SG_ 593 PAS_Sonar11_ControlBusFailure "控制器通信是否失败";
CM_ SG_ 593 PAS_Sonar11_RingingTimeFailure "余震时间是否正常";
CM_ SG_ 593 PAS_Sonar11_ShortToGND "是否对地短路或信号线断开";
CM_ SG_ 593 PAS_Sonar11_ShortToPositivePole "是否对Ubat短路或GND开路";
CM_ SG_ 593 PAS_Sonar11_TypeMismatch "探头类型不匹配";
CM_ SG_ 593 PAS_ECU_OverVoltage "系统过压";
CM_ SG_ 593 PAS_ECU_UnderVoltage "系统欠压";
CM_ SG_ 593 PAS_ECU_BusOff_ERROR "ECU CAN Busoff错误";
CM_ SG_ 593 PAS_MDC_COMMU_ERROR "MDC通信丢失";
CM_ SG_ 593 PAS_ECU_EEPROM_ERROR "EEPROM错误";
CM_ SG_ 593 PAS_DiagnosisInfo_RollingCounter "消息计数器";
CM_ SG_ 593 PAS_DiagnosisInfo_Checksum "校验码";
CM_ SG_ 593 Fill4bit "填充位";
CM_ SG_ 593 PAS_MDCSIGNAL_ERROR "MDC信号无效";
CM_ SG_ 593 PAS_ECU_INTERNAL_ERROR "USS ECU 内部故障";
CM_ SG_ 593 PAS_TIMESYNC_ERROR "时间同步异常";
CM_ SG_ 593 PAS_KEYLEARN_ERROR "密钥学习异常";
CM_ SG_ 593 PAS_AUTHEN_ERROR "设备认证异常";
CM_ SG_ 593 PAS_Sonar0_Internal_failure "Sonar0内部故障";
CM_ SG_ 593 PAS_Sonar1_Internal_failure "Sonar1内部故障";
CM_ SG_ 593 PAS_Sonar2_Internal_failure "Sonar2内部故障";
CM_ SG_ 593 PAS_Sonar3_Internal_failure "Sonar3内部故障";
CM_ SG_ 593 PAS_Sonar4_Internal_failure "Sonar4内部故障";
CM_ SG_ 593 PAS_Sonar5_Internal_failure "Sonar5内部故障";
CM_ SG_ 593 PAS_Sonar6_Internal_failure "Sonar6内部故障";
CM_ SG_ 593 PAS_Sonar7_Internal_failure "Sonar7内部故障";
CM_ SG_ 593 PAS_Sonar8_Internal_failure "Sonar8内部故障";
CM_ SG_ 593 PAS_Sonar9_Internal_failure "Sonar9内部故障";
CM_ SG_ 593 PAS_Sonar10_Internal_failure "Sonar10内部故障";
CM_ SG_ 593 PAS_Sonar11_Internal_failure "Sonar11内部故障";
CM_ SG_ 593 USS_Front_ShortToGND "前部USS系统对地短路";
CM_ SG_ 593 USS_Front_ShortToUbat "前部USS系统对电源短路";
CM_ SG_ 593 USS_Rear_ShortToGND "后部USS系统对地短路";
CM_ SG_ 593 USS_Rear_ShortToUbat "后部USS系统对电源短路";
CM_ SG_ 593 VHM_Error "车辆模型错误";
CM_ SG_ 593 Sensor_Version_Fail "配置失败故障";
CM_ SG_ 672 PAS_Device_Vertify_Times "设备认证次数";
CM_ SG_ 672 PAS_Device_Vertify_Status "当前设备认证状态";
CM_ SG_ 673 PAS_RandomByte1 "随机数_传感器";
CM_ SG_ 673 PAS_RandomByte2 "随机数_传感器";
CM_ SG_ 673 PAS_RandomByte3 "随机数_传感器";
CM_ SG_ 673 PAS_RandomByte4 "随机数_传感器";
CM_ SG_ 673 PAS_RandomByte5 "随机数_传感器";
CM_ SG_ 673 PAS_RandomByte6 "随机数_传感器";
CM_ SG_ 673 PAS_RandomByte7 "随机数_传感器";
CM_ SG_ 673 PAS_RandomByte8 "随机数_传感器";
CM_ SG_ 673 PAS_SessionID "当前挑战应答的会话ID";
CM_ SG_ 674 PAS_Verification_Result "传感器校验结果。如果传感器校验会话ID失败，或者校验CMAC值不一致，设置该值为失败，结束本次认证流程";
CM_ SG_ 674 PAS_SessionID "密钥协商会话ID";
CM_ SG_ 674 PAS_CMACByte1 "CMAC（随机数拼接会话ID）后，取结果的高64位";
CM_ SG_ 674 PAS_CMACByte2 "CMAC（随机数拼接会话ID）后，取结果的高64位";
CM_ SG_ 674 PAS_CMACByte3 "CMAC（随机数拼接会话ID）后，取结果的高64位";
CM_ SG_ 674 PAS_CMACByte4 "CMAC（随机数拼接会话ID）后，取结果的高64位";
CM_ SG_ 674 PAS_CMACByte5 "CMAC（随机数拼接会话ID）后，取结果的高64位";
CM_ SG_ 674 PAS_CMACByte6 "CMAC（随机数拼接会话ID）后，取结果的高64位";
CM_ SG_ 674 PAS_CMACByte7 "CMAC（随机数拼接会话ID）后，取结果的高64位";
CM_ SG_ 674 PAS_CMACByte8 "CMAC（随机数拼接会话ID）后，取结果的高64位";
CM_ SG_ 706 PAS_Key_Learn_SubID "传感器_KeyLearnSubID";
CM_ SG_ 706 PAS_Key_Learn_Numbers "反馈的密钥学习状态个数";
CM_ SG_ 706 PAS_SKID1 "密钥ID1";
CM_ SG_ 706 PAS_SK_Learn_Status1 "密钥学习状态1";
CM_ SG_ 706 PAS_SKID2 "密钥ID2";
CM_ SG_ 706 PAS_SK_Learn_Status2 "密钥学习状态2";
CM_ SG_ 706 PAS_SKID3 "密钥ID3";
CM_ SG_ 706 PAS_SK_Learn_Status3 "密钥学习状态3";
CM_ SG_ 706 PAS_SKID4 "密钥ID4";
CM_ SG_ 706 PAS_SK_Learn_Status4 "密钥学习状态4";
CM_ SG_ 706 PAS_SKID5 "密钥ID5";
CM_ SG_ 706 PAS_SK_Learn_Status5 "密钥学习状态5";
CM_ SG_ 706 PAS_SKID6 "密钥ID6";
CM_ SG_ 706 PAS_SK_Learn_Status6 "密钥学习状态6";
CM_ SG_ 706 PAS_SKID7 "密钥ID7";
CM_ SG_ 706 PAS_SK_Learn_Status7 "密钥学习状态7";
CM_ SG_ 706 PAS_SKID8 "密钥ID8";
CM_ SG_ 706 PAS_SK_Learn_Status8 "密钥学习状态8";
CM_ SG_ 706 PAS_SKID9 "密钥ID9";
CM_ SG_ 706 PAS_SK_Learn_Status9 "密钥学习状态9";
CM_ SG_ 706 PAS_SKID10 "密钥ID10";
CM_ SG_ 706 PAS_SK_Learn_Status10 "密钥学习状态10";
CM_ SG_ 706 PAS_SKID11 "密钥ID11";
CM_ SG_ 706 PAS_SK_Learn_Status11 "密钥学习状态11";
CM_ SG_ 706 PAS_SKID12 "密钥ID12";
CM_ SG_ 706 PAS_SK_Learn_Status12 "密钥学习状态12";
CM_ SG_ 708 PASKeyLearnSubIDSettingResponse "传感器_KeyLearnSubID";
CM_ SG_ 708 PAS_SK_Setting_Response "设置学习状态反馈的密钥ID";
CM_ SG_ 708 PAS_SK_Setting_Status "学习状态";
CM_ SG_ 707 PAS_VerifySubID "传感器反馈AES计算结果，此字段携带1";
CM_ SG_ 707 PAS_Verify_SKID "设置学习状态反馈的密钥ID";
CM_ SG_ 707 PAS_Verify_AES_Result "32bit的加密密文，AES128-GCM，none-padding";
CM_ SG_ 707 PAS_Verify_MACbyte1 "GCM计算的MAC，AES128-GCM，none-padding";
CM_ SG_ 707 PAS_Verify_MACbyte2 "GCM计算的MAC，AES128-GCM，none-padding";
CM_ SG_ 707 PAS_Verify_MACbyte3 "GCM计算的MAC，AES128-GCM，none-padding";
CM_ SG_ 707 PAS_Verify_MACbyte4 "GCM计算的MAC，AES128-GCM，none-padding";
CM_ SG_ 707 PAS_Verify_MACbyte5 "GCM计算的MAC，AES128-GCM，none-padding";
CM_ SG_ 707 PAS_Verify_MACbyte6 "GCM计算的MAC，AES128-GCM，none-padding";
CM_ SG_ 707 PAS_Verify_MACbyte7 "GCM计算的MAC，AES128-GCM，none-padding";
CM_ SG_ 707 PAS_Verify_MACbyte8 "GCM计算的MAC，AES128-GCM，none-padding";
CM_ SG_ 707 PAS_Verify_MACbyte9 "GCM计算的MAC，AES128-GCM，none-padding";
CM_ SG_ 707 PAS_Verify_MACbyte10 "GCM计算的MAC，AES128-GCM，none-padding";
CM_ SG_ 707 PAS_Verify_MACbyte11 "GCM计算的MAC，AES128-GCM，none-padding";
CM_ SG_ 707 PAS_Verify_MACbyte12 "GCM计算的MAC，AES128-GCM，none-padding";
CM_ SG_ 707 PAS_Verify_MACbyte13 "GCM计算的MAC，AES128-GCM，none-padding";
CM_ SG_ 707 PAS_Verify_MACbyte14 "GCM计算的MAC，AES128-GCM，none-padding";
CM_ SG_ 707 PAS_Verify_MACbyte15 "GCM计算的MAC，AES128-GCM，none-padding";
CM_ SG_ 707 PAS_Verify_MACbyte16 "GCM计算的MAC，AES128-GCM，none-padding";
CM_ SG_ 707 PAS_Verify_IVByte1 "96bit 的IV";
CM_ SG_ 707 PAS_Verify_IVByte2 "96bit 的IV";
CM_ SG_ 707 PAS_Verify_IVByte3 "96bit 的IV";
CM_ SG_ 707 PAS_Verify_IVByte4 "96bit 的IV";
CM_ SG_ 707 PAS_Verify_IVByte5 "96bit 的IV";
CM_ SG_ 707 PAS_Verify_IVByte6 "96bit 的IV";
CM_ SG_ 707 PAS_Verify_IVByte7 "96bit 的IV";
CM_ SG_ 707 PAS_Verify_IVByte8 "96bit 的IV";
CM_ SG_ 707 PAS_Verify_IVByte9 "96bit 的IV";
CM_ SG_ 707 PAS_Verify_IVByte10 "96bit 的IV";
CM_ SG_ 707 PAS_Verify_IVByte11 "96bit 的IV";
CM_ SG_ 707 PAS_Verify_IVByte12 "96bit 的IV";
CM_ SG_ 608 UPC_Object1_Type "Map Object 1 Type
1号障碍物类型";
CM_ SG_ 608 UPC_Object1_ExistProbability "Map Object 1 Exist Propability1号障碍物的存在置信度";
CM_ SG_ 608 UPC_Object1_Height "Map Object 1 Height Classification1号障碍物的高度等级";
CM_ SG_ 608 UPC_Object1_HeightProbability "Map Object 1 Height Propability1号障碍物的高度置信度";
CM_ SG_ 608 UPCObject1PositionUpdateTime "Time Stamp for the time when the object 1 position update1号障碍物坐标位置更新的时间戳";
CM_ SG_ 608 UPC_Object1_Point1PositionX "Map object 1, X axis of point 1 in vehicle coordinate system.以车辆后轴中心为原点的1号障碍物point 1的X坐标";
CM_ SG_ 608 UPC_Object1_Point1PositionY "Map object 1, Y axis of point 1 in vehicle coordinate system.以车辆后轴中心为原点的1号障碍物point 1的Y坐标";
CM_ SG_ 608 UPC_Object1_Point2PositionX "Map object 1, X axis of point 2 in vehicle coordinate system.
以车辆后轴中心为原点的1号障碍物point 2的X坐标";
CM_ SG_ 608 UPC_Object1_Point2PositionY "Map object 1, Y axis of point 2 in vehicle coordinate system.
以车辆后轴中心为原点的1号障碍物point 2的Y坐标";
CM_ SG_ 608 UPC_Object1_ID "Object 1 ID
1号障碍物的ID号";
CM_ SG_ 608 UPC_Object2_Type "Map Object 2 Type
2号障碍物类型";
CM_ SG_ 608 UPC_Object2_ExistProbability "Map Object 2 Exist Propability
2号障碍物的存在置信度";
CM_ SG_ 608 UPC_Object2_Height "Map Object 2 Height Classification
2号障碍物的高度等级";
CM_ SG_ 608 UPC_Object2_HeightProbability "Map Object 2 Height Propability
2号障碍物的高度置信度";
CM_ SG_ 608 UPCObject2PositionUpdateTime "Time Stamp for the time when the object 2 position update
2号障碍物坐标位置更新的时间戳";
CM_ SG_ 608 UPC_Object2_Point1PositionX "Map object 2, X axis of point 1 in vehicle coordinate system.
以车辆后轴中心为原点的2号障碍物point 1的X坐标";
CM_ SG_ 608 UPC_Object2_Point1PositionY "Map object 2, Y axis of point 1 in vehicle coordinate system.
以车辆后轴中心为原点的2号障碍物point 1的Y坐标";
CM_ SG_ 608 UPC_Object2_Point2PositionX "Map object 2, X axis of point 2 in vehicle coordinate system.
以车辆后轴中心为原点的2号障碍物point 2的X坐标";
CM_ SG_ 608 UPC_Object2_Point2PositionY "Map object 2, Y axis of point 2 in vehicle coordinate system.
以车辆后轴中心为原点的2号障碍物point 2的Y坐标";
CM_ SG_ 608 UPC_Object2_ID "Object 2 ID
2号障碍物的ID号";
CM_ SG_ 608 UPC_Object3_Type "Map Object 3 Type
3号障碍物类型";
CM_ SG_ 608 UPC_Object3_ExistProbability "Map Object 3 Exist Propability
3号障碍物的存在置信度";
CM_ SG_ 608 UPC_Object3_Height "Map Object 3 Height Classification
3号障碍物的高度等级";
CM_ SG_ 608 UPC_Object3_HeightProbability "Map Object 3 Height Propability
3号障碍物的高度置信度";
CM_ SG_ 608 UPCObject3PositionUpdateTime "Time Stamp for the time when the object 3 position update
3号障碍物坐标位置更新的时间戳";
CM_ SG_ 608 UPC_Object3_Point1PositionX "Map object 3, X axis of point 1 in vehicle coordinate system.
以车辆后轴中心为原点的3号障碍物point 1的X坐标";
CM_ SG_ 608 UPC_Object3_Point1PositionY "Map object 3, Y axis of point 1 in vehicle coordinate system.
以车辆后轴中心为原点的3号障碍物point 1的Y坐标";
CM_ SG_ 608 UPC_Object3_Point2PositionX "Map object 3, X axis of point 2 in vehicle coordinate system.
以车辆后轴中心为原点的3号障碍物point 2的X坐标";
CM_ SG_ 608 UPC_Object3_Point2PositionY "Map object 3, Y axis of point 2 in vehicle coordinate system.
以车辆后轴中心为原点的3号障碍物point 2的Y坐标";
CM_ SG_ 608 UPC_Object3_ID "Object 3 ID
3号障碍物的ID号";
CM_ SG_ 608 UPC_Object4_Type "Map Object 4 Type
4号障碍物类型";
CM_ SG_ 608 UPC_Object4_ExistProbability "Map Object 4 Exist Propability
4号障碍物的存在置信度";
CM_ SG_ 608 UPC_Object4_Height "Map Object 4 Height Classification
4号障碍物的高度等级";
CM_ SG_ 608 UPC_Object4_HeightProbability "Map Object 4 Height Propability
4号障碍物的高度置信度";
CM_ SG_ 608 UPCObject4PositionUpdateTime "Time Stamp for the time when the object 4 position update
4号障碍物坐标位置更新的时间戳";
CM_ SG_ 608 UPC_Object4_Point1PositionX "Map object 4, X axis of point 1 in vehicle coordinate system.
以车辆后轴中心为原点的4号障碍物point 1的X坐标";
CM_ SG_ 608 UPC_Object4_Point1PositionY "Map object 4, Y axis of point 1 in vehicle coordinate system.
以车辆后轴中心为原点的4号障碍物point 1的Y坐标";
CM_ SG_ 608 UPC_Object4_Point2PositionX "Map object 4, X axis of point 2 in vehicle coordinate system.
以车辆后轴中心为原点的4号障碍物point 2的X坐标";
CM_ SG_ 608 UPC_Object4_Point2PositionY "Map object 4, Y axis of point 2 in vehicle coordinate system.
以车辆后轴中心为原点的4号障碍物point 2的Y坐标";
CM_ SG_ 608 UPC_Object4_ID "Object 4 ID
4号障碍物的ID号";
CM_ SG_ 608 UPC_Object5_Type "Map Object 5 Type
5号障碍物类型";
CM_ SG_ 608 UPC_Object5_ExistProbability "Map Object 5 Exist Propability
5号障碍物的存在置信度";
CM_ SG_ 608 UPC_Object5_Height "Map Object 5 Height Classification
5号障碍物的高度等级";
CM_ SG_ 608 UPC_Object5_HeightProbability "Map Object 5 Height Propability
5号障碍物的高度置信度";
CM_ SG_ 608 UPCObject5PositionUpdateTime "Time Stamp for the time when the object 5 position update
5号障碍物坐标位置更新的时间戳";
CM_ SG_ 608 UPC_Object5_Point1PositionX "Map object 5, X axis of point 1 in vehicle coordinate system.
以车辆后轴中心为原点的5号障碍物point 1的X坐标";
CM_ SG_ 608 UPC_Object5_Point1PositionY "Map object 5, Y axis of point 1 in vehicle coordinate system.
以车辆后轴中心为原点的5号障碍物point 1的Y坐标";
CM_ SG_ 608 UPC_Object5_Point2PositionX "Map object 5, X axis of point 2 in vehicle coordinate system.
以车辆后轴中心为原点的5号障碍物point 2的X坐标";
CM_ SG_ 608 UPC_Object5_Point2PositionY "Map object 5, Y axis of point 2 in vehicle coordinate system.
以车辆后轴中心为原点的5号障碍物point 2的Y坐标";
CM_ SG_ 608 UPC_Object5_ID "Object 5 ID
5号障碍物的ID号";
CM_ SG_ 608 PAS_Obj1_5_Checksum "校验码";
CM_ SG_ 608 PAS_Obj1_5_RollingCounter "消息计数器";
CM_ SG_ 609 UPC_Object6_Type "Map Object 6 Type
6号障碍物类型";
CM_ SG_ 609 UPC_Object6_ExistProbability "Map Object 6 Exist Propability
6号障碍物的存在置信度";
CM_ SG_ 609 UPC_Object6_Height "Map Object 6 Height Classification
6号障碍物的高度等级";
CM_ SG_ 609 UPC_Object6_HeightProbability "Map Object 6 Height Propability
6号障碍物的高度置信度";
CM_ SG_ 609 UPCObject6PositionUpdateTime "Time Stamp for the time when the object 6 position update
6号障碍物坐标位置更新的时间戳";
CM_ SG_ 609 UPC_Object6_Point1PositionX "Map object 6, X axis of point 1 in vehicle coordinate system.
以车辆后轴中心为原点的6号障碍物point 1的X坐标";
CM_ SG_ 609 UPC_Object6_Point1PositionY "Map object 6, Y axis of point 1 in vehicle coordinate system.
以车辆后轴中心为原点的6号障碍物point 1的Y坐标";
CM_ SG_ 609 UPC_Object6_Point2PositionX "Map object 6, X axis of point 2 in vehicle coordinate system.
以车辆后轴中心为原点的6号障碍物point 2的X坐标";
CM_ SG_ 609 UPC_Object6_Point2PositionY "Map object 6, Y axis of point 2 in vehicle coordinate system.
以车辆后轴中心为原点的6号障碍物point 2的Y坐标";
CM_ SG_ 609 UPC_Object6_ID "Object 6 ID
6号障碍物的ID号";
CM_ SG_ 609 UPC_Object7_Type "Map Object 7 Type
7号障碍物类型";
CM_ SG_ 609 UPC_Object7_ExistProbability "Map Object 7 Exist Propability
7号障碍物的存在置信度";
CM_ SG_ 609 UPC_Object7_Height "Map Object 7 Height Classification
7号障碍物的高度等级";
CM_ SG_ 609 UPC_Object7_HeightProbability "Map Object 7 Height Propability
7号障碍物的高度置信度";
CM_ SG_ 609 UPCObject7PositionUpdateTime "Time Stamp for the time when the object 7 position update
7号障碍物坐标位置更新的时间戳";
CM_ SG_ 609 UPC_Object7_Point1PositionX "Map object 7, X axis of point 1 in vehicle coordinate system.
以车辆后轴中心为原点的7号障碍物point 1的X坐标";
CM_ SG_ 609 UPC_Object7_Point1PositionY "Map object 7, Y axis of point 1 in vehicle coordinate system.
以车辆后轴中心为原点的7号障碍物point 1的Y坐标";
CM_ SG_ 609 UPC_Object7_Point2PositionX "Map object 7, X axis of point 2 in vehicle coordinate system.
以车辆后轴中心为原点的7号障碍物point 2的X坐标";
CM_ SG_ 609 UPC_Object7_Point2PositionY "Map object 7, Y axis of point 2 in vehicle coordinate system.
以车辆后轴中心为原点的7号障碍物point 2的Y坐标";
CM_ SG_ 609 UPC_Object7_ID "Object 7 ID
7号障碍物的ID号";
CM_ SG_ 609 UPC_Object8_Type "Map Object 8 Type
8号障碍物类型";
CM_ SG_ 609 UPC_Object8_ExistProbability "Map Object 8 Exist Propability
8号障碍物的存在置信度";
CM_ SG_ 609 UPC_Object8_Height "Map Object 8 Height Classification
8号障碍物的高度等级";
CM_ SG_ 609 UPC_Object8_HeightProbability "Map Object 8 Height Propability
8号障碍物的高度置信度";
CM_ SG_ 609 UPCObject8PositionUpdateTime "Time Stamp for the time when the object 8 position update
8号障碍物坐标位置更新的时间戳";
CM_ SG_ 609 UPC_Object8_Point1PositionX "Map object 8, X axis of point 1 in vehicle coordinate system.
以车辆后轴中心为原点的8号障碍物point 1的X坐标";
CM_ SG_ 609 UPC_Object8_Point1PositionY "Map object 8, Y axis of point 1 in vehicle coordinate system.
以车辆后轴中心为原点的8号障碍物point 1的Y坐标";
CM_ SG_ 609 UPC_Object8_Point2PositionX "Map object 8, X axis of point 2 in vehicle coordinate system.
以车辆后轴中心为原点的8号障碍物point 2的X坐标";
CM_ SG_ 609 UPC_Object8_Point2PositionY "Map object 8, Y axis of point 2 in vehicle coordinate system.
以车辆后轴中心为原点的8号障碍物point 2的Y坐标";
CM_ SG_ 609 UPC_Object8_ID "Object 8 ID
8号障碍物的ID号";
CM_ SG_ 609 UPC_Object9_Type "Map Object 9 Type
9号障碍物类型";
CM_ SG_ 609 UPC_Object9_ExistProbability "Map Object 9 Exist Propability
9号障碍物的存在置信度";
CM_ SG_ 609 UPC_Object9_Height "Map Object 9 Height Classification
9号障碍物的高度等级";
CM_ SG_ 609 UPC_Object9_HeightProbability "Map Object 9 Height Propability
9号障碍物的高度置信度";
CM_ SG_ 609 UPCObject9PositionUpdateTime "Time Stamp for the time when the object 9 position update
9号障碍物坐标位置更新的时间戳";
CM_ SG_ 609 UPC_Object9_Point1PositionX "Map object 9, X axis of point 1 in vehicle coordinate system.
以车辆后轴中心为原点的9号障碍物point 1的X坐标";
CM_ SG_ 609 UPC_Object9_Point1PositionY "Map object 9, Y axis of point 1 in vehicle coordinate system.
以车辆后轴中心为原点的9号障碍物point 1的Y坐标";
CM_ SG_ 609 UPC_Object9_Point2PositionX "Map object 9, X axis of point 2 in vehicle coordinate system.
以车辆后轴中心为原点的9号障碍物point 2的X坐标";
CM_ SG_ 609 UPC_Object9_Point2PositionY "Map object 9, Y axis of point 2 in vehicle coordinate system.
以车辆后轴中心为原点的9号障碍物point 2的Y坐标";
CM_ SG_ 609 UPC_Object9_ID "Object 9 ID
9号障碍物的ID号";
CM_ SG_ 609 UPC_Object10_Type "Map Object 10 Type
10号障碍物类型";
CM_ SG_ 609 UPC_Object10_ExistProbability "Map Object 10 Exist Propability
10号障碍物的存在置信度";
CM_ SG_ 609 UPC_Object10_Height "Map Object 10 Height Classification
10号障碍物的高度等级";
CM_ SG_ 609 UPC_Object10_HeightProbability "Map Object 10 Height Propability
10号障碍物的高度置信度";
CM_ SG_ 609 UPCObject10PositionUpdateTime "Time Stamp for the time when the object 10 position update
10号障碍物坐标位置更新的时间戳";
CM_ SG_ 609 UPC_Object10_Point1PositionX "Map object 10, X axis of point 1 in vehicle coordinate system.
以车辆后轴中心为原点的10号障碍物point 1的X坐标";
CM_ SG_ 609 UPC_Object10_Point1PositionY "Map object 10, Y axis of point 1 in vehicle coordinate system.
以车辆后轴中心为原点的10号障碍物point 1的Y坐标";
CM_ SG_ 609 UPC_Object10_Point2PositionX "Map object 10, X axis of point 2 in vehicle coordinate system.
以车辆后轴中心为原点的10号障碍物point 2的X坐标";
CM_ SG_ 609 UPC_Object10_Point2PositionY "Map object 10, Y axis of point 2 in vehicle coordinate system.
以车辆后轴中心为原点的10号障碍物point 2的Y坐标";
CM_ SG_ 609 UPC_Object10_ID "Object 10 ID
10号障碍物的ID号";
CM_ SG_ 609 PAS_Obj6_10_Checksum "Checksum";
CM_ SG_ 609 PAS_Obj6_10_RollingCounter "Message Rolling counter";
CM_ SG_ 610 UPC_Object11_Type "Map Object 11 Type
11号障碍物类型";
CM_ SG_ 610 UPC_Object11_ExistProbability "Map Object 11 Exist Propability
11号障碍物的存在置信度";
CM_ SG_ 610 UPC_Object11_Height "Map Object 11 Height Classification
11号障碍物的高度等级";
CM_ SG_ 610 UPC_Object11_HeightProbability "Map Object 11 Height Propability
11号障碍物的高度置信度";
CM_ SG_ 610 UPCObject11PositionUpdateTime "Time Stamp for the time when the object 11 position update
11号障碍物坐标位置更新的时间戳";
CM_ SG_ 610 UPC_Object11_Point1PositionX "Map object 11, X axis of point 1 in vehicle coordinate system.
以车辆后轴中心为原点的11号障碍物point 1的X坐标";
CM_ SG_ 610 UPC_Object11_Point1PositionY "Map object 11, Y axis of point 1 in vehicle coordinate system.
以车辆后轴中心为原点的11号障碍物point 1的Y坐标";
CM_ SG_ 610 UPC_Object11_Point2PositionX "Map object 11, X axis of point 2 in vehicle coordinate system.
以车辆后轴中心为原点的11号障碍物point 2的X坐标";
CM_ SG_ 610 UPC_Object11_Point2PositionY "Map object 11, Y axis of point 2 in vehicle coordinate system.
以车辆后轴中心为原点的11号障碍物point 2的Y坐标";
CM_ SG_ 610 UPC_Object11_ID "Object 11 ID
11号障碍物的ID号";
CM_ SG_ 610 UPC_Object12_Type "Map Object 12 Type
12号障碍物类型";
CM_ SG_ 610 UPC_Object12_ExistProbability "Map Object 12 Exist Propability
12号障碍物的存在置信度";
CM_ SG_ 610 UPC_Object12_Height "Map Object 12 Height Classification
12号障碍物的高度等级";
CM_ SG_ 610 UPC_Object12_HeightProbability "Map Object 12 Height Propability
12号障碍物的高度置信度";
CM_ SG_ 610 UPCObject12PositionUpdateTime "Time Stamp for the time when the object 12 position update
12号障碍物坐标位置更新的时间戳";
CM_ SG_ 610 UPC_Object12_Point1PositionX "Map object 12, X axis of point 1 in vehicle coordinate system.
以车辆后轴中心为原点的12号障碍物point 1的X坐标";
CM_ SG_ 610 UPC_Object12_Point1PositionY "Map object 12, Y axis of point 1 in vehicle coordinate system.
以车辆后轴中心为原点的12号障碍物point 1的Y坐标";
CM_ SG_ 610 UPC_Object12_Point2PositionX "Map object 12, X axis of point 2 in vehicle coordinate system.
以车辆后轴中心为原点的12号障碍物point 2的X坐标";
CM_ SG_ 610 UPC_Object12_Point2PositionY "Map object 12, Y axis of point 2 in vehicle coordinate system.
以车辆后轴中心为原点的12号障碍物point 2的Y坐标";
CM_ SG_ 610 UPC_Object12_ID "Object 12 ID
12号障碍物的ID号";
CM_ SG_ 610 UPC_Object13_Type "Map Object 13 Type
13号障碍物类型";
CM_ SG_ 610 UPC_Object13_ExistProbability "Map Object 13 Exist Propability
13号障碍物的存在置信度";
CM_ SG_ 610 UPC_Object13_Height "Map Object 13 Height Classification
13号障碍物的高度等级";
CM_ SG_ 610 UPC_Object13_HeightProbability "Map Object 13 Height Propability
13号障碍物的高度置信度";
CM_ SG_ 610 UPCObject13PositionUpdateTime "Time Stamp for the time when the object 13 position update
13号障碍物坐标位置更新的时间戳";
CM_ SG_ 610 UPC_Object13_Point1PositionX "Map object 13, X axis of point 1 in vehicle coordinate system.
以车辆后轴中心为原点的13号障碍物point 1的X坐标";
CM_ SG_ 610 UPC_Object13_Point1PositionY "Map object 13, Y axis of point 1 in vehicle coordinate system.
以车辆后轴中心为原点的13号障碍物point 1的Y坐标";
CM_ SG_ 610 UPC_Object13_Point2PositionX "Map object 13, X axis of point 2 in vehicle coordinate system.
以车辆后轴中心为原点的13号障碍物point 2的X坐标";
CM_ SG_ 610 UPC_Object13_Point2PositionY "Map object 13, Y axis of point 2 in vehicle coordinate system.
以车辆后轴中心为原点的13号障碍物point 2的Y坐标";
CM_ SG_ 610 UPC_Object13_ID "Object 13 ID
13号障碍物的ID号";
CM_ SG_ 610 UPC_Object14_Type "Map Object 14 Type
14号障碍物类型";
CM_ SG_ 610 UPC_Object14_ExistProbability "Map Object 14 Exist Propability
14号障碍物的存在置信度";
CM_ SG_ 610 UPC_Object14_Height "Map Object 14 Height Classification
14号障碍物的高度等级";
CM_ SG_ 610 UPC_Object14_HeightProbability "Map Object 14 Height Propability
14号障碍物的高度置信度";
CM_ SG_ 610 UPCObject14PositionUpdateTime "Time Stamp for the time when the object 14 position update
14号障碍物坐标位置更新的时间戳";
CM_ SG_ 610 UPC_Object14_Point1PositionX "Map object 14, X axis of point 1 in vehicle coordinate system.
以车辆后轴中心为原点的14号障碍物point 1的X坐标";
CM_ SG_ 610 UPC_Object14_Point1PositionY "Map object 14, Y axis of point 1 in vehicle coordinate system.
以车辆后轴中心为原点的14号障碍物point 1的Y坐标";
CM_ SG_ 610 UPC_Object14_Point2PositionX "Map object 14, X axis of point 2 in vehicle coordinate system.
以车辆后轴中心为原点的14号障碍物point 2的X坐标";
CM_ SG_ 610 UPC_Object14_Point2PositionY "Map object 14, Y axis of point 2 in vehicle coordinate system.
以车辆后轴中心为原点的14号障碍物point 2的Y坐标";
CM_ SG_ 610 UPC_Object14_ID "Object 14 ID
14号障碍物的ID号";
CM_ SG_ 610 UPC_Object15_Type "Map Object 15 Type
15号障碍物类型";
CM_ SG_ 610 UPC_Object15_ExistProbability "Map Object 15 Exist Propability
15号障碍物的存在置信度";
CM_ SG_ 610 UPC_Object15_Height "Map Object 15 Height Classification
15号障碍物的高度等级";
CM_ SG_ 610 UPC_Object15_HeightProbability "Map Object 15 Height Propability
15号障碍物的高度置信度";
CM_ SG_ 610 UPCObject15PositionUpdateTime "Time Stamp for the time when the object 15 position update
15号障碍物坐标位置更新的时间戳";
CM_ SG_ 610 UPC_Object15_Point1PositionX "Map object 15, X axis of point 1 in vehicle coordinate system.
以车辆后轴中心为原点的15号障碍物point 1的X坐标";
CM_ SG_ 610 UPC_Object15_Point1PositionY "Map object 15, Y axis of point 1 in vehicle coordinate system.
以车辆后轴中心为原点的15号障碍物point 1的Y坐标";
CM_ SG_ 610 UPC_Object15_Point2PositionX "Map object 15, X axis of point 2 in vehicle coordinate system.
以车辆后轴中心为原点的15号障碍物point 2的X坐标";
CM_ SG_ 610 UPC_Object15_Point2PositionY "Map object 15, Y axis of point 2 in vehicle coordinate system.
以车辆后轴中心为原点的15号障碍物point 2的Y坐标";
CM_ SG_ 610 UPC_Object15_ID "Object 15 ID
15号障碍物的ID号";
CM_ SG_ 610 PAS_Obj11_15_Checksum "Checksum";
CM_ SG_ 610 PAS_Obj11_15_RollingCounter "Message Rolling counter";
CM_ SG_ 611 UPC_Object16_Type "Map Object 16 Type
16号障碍物类型";
CM_ SG_ 611 UPC_Object16_ExistProbability "Map Object 16 Exist Propability
16号障碍物的存在置信度";
CM_ SG_ 611 UPC_Object16_Height "Map Object 16 Height Classification
16号障碍物的高度等级";
CM_ SG_ 611 UPC_Object16_HeightProbability "Map Object 16 Height Propability
16号障碍物的高度置信度";
CM_ SG_ 611 UPCObject16PositionUpdateTime "Time Stamp for the time when the object 16 position update
16号障碍物坐标位置更新的时间戳";
CM_ SG_ 611 UPC_Object16_Point1PositionX "Map object 16, X axis of point 1 in vehicle coordinate system.
以车辆后轴中心为原点的16号障碍物point 1的X坐标";
CM_ SG_ 611 UPC_Object16_Point1PositionY "Map object 16, Y axis of point 1 in vehicle coordinate system.
以车辆后轴中心为原点的16号障碍物point 1的Y坐标";
CM_ SG_ 611 UPC_Object16_Point2PositionX "Map object 16, X axis of point 2 in vehicle coordinate system.
以车辆后轴中心为原点的16号障碍物point 2的X坐标";
CM_ SG_ 611 UPC_Object16_Point2PositionY "Map object 16, Y axis of point 2 in vehicle coordinate system.
以车辆后轴中心为原点的16号障碍物point 2的Y坐标";
CM_ SG_ 611 UPC_Object16_ID "Object 16 ID
16号障碍物的ID号";
CM_ SG_ 611 UPC_Object17_Type "Map Object 17 Type
17号障碍物类型";
CM_ SG_ 611 UPC_Object17_ExistProbability "Map Object 17 Exist Propability
17号障碍物的存在置信度";
CM_ SG_ 611 UPC_Object17_Height "Map Object 17 Height Classification
17号障碍物的高度等级";
CM_ SG_ 611 UPC_Object17_HeightProbability "Map Object 17 Height Propability
17号障碍物的高度置信度";
CM_ SG_ 611 UPCObject17PositionUpdateTime "Time Stamp for the time when the object 17 position update
17号障碍物坐标位置更新的时间戳";
CM_ SG_ 611 UPC_Object17_Point1PositionX "Map object 17, X axis of point 1 in vehicle coordinate system.
以车辆后轴中心为原点的17号障碍物point 1的X坐标";
CM_ SG_ 611 UPC_Object17_Point1PositionY "Map object 17, Y axis of point 1 in vehicle coordinate system.
以车辆后轴中心为原点的17号障碍物point 1的Y坐标";
CM_ SG_ 611 UPC_Object17_Point2PositionX "Map object 17, X axis of point 2 in vehicle coordinate system.
以车辆后轴中心为原点的17号障碍物point 2的X坐标";
CM_ SG_ 611 UPC_Object17_Point2PositionY "Map object 17, Y axis of point 2 in vehicle coordinate system.
以车辆后轴中心为原点的17号障碍物point 2的Y坐标";
CM_ SG_ 611 UPC_Object17_ID "Object 17 ID
17号障碍物的ID号";
CM_ SG_ 611 UPC_Object18_Type "Map Object 18 Type
18号障碍物类型";
CM_ SG_ 611 UPC_Object18_ExistProbability "Map Object 18 Exist Propability
18号障碍物的存在置信度";
CM_ SG_ 611 UPC_Object18_Height "Map Object 18 Height Classification
18号障碍物的高度等级";
CM_ SG_ 611 UPC_Object18_HeightProbability "Map Object 18 Height Propability
18号障碍物的高度置信度";
CM_ SG_ 611 UPCObject18PositionUpdateTime "Time Stamp for the time when the object 18 position update
18号障碍物坐标位置更新的时间戳";
CM_ SG_ 611 UPC_Object18_Point1PositionX "Map object 18, X axis of point 1 in vehicle coordinate system.
以车辆后轴中心为原点的18号障碍物point 1的X坐标";
CM_ SG_ 611 UPC_Object18_Point1PositionY "Map object 18, Y axis of point 1 in vehicle coordinate system.
以车辆后轴中心为原点的18号障碍物point 1的Y坐标";
CM_ SG_ 611 UPC_Object18_Point2PositionX "Map object 18, X axis of point 2 in vehicle coordinate system.
以车辆后轴中心为原点的18号障碍物point 2的X坐标";
CM_ SG_ 611 UPC_Object18_Point2PositionY "Map object 18, Y axis of point 2 in vehicle coordinate system.
以车辆后轴中心为原点的18号障碍物point 2的Y坐标";
CM_ SG_ 611 UPC_Object18_ID "Object 18 ID
18号障碍物的ID号";
CM_ SG_ 611 UPC_Object19_Type "Map Object 19 Type
19号障碍物类型";
CM_ SG_ 611 UPC_Object19_ExistProbability "Map Object 19 Exist Propability
19号障碍物的存在置信度";
CM_ SG_ 611 UPC_Object19_Height "Map Object 19 Height Classification
19号障碍物的高度等级";
CM_ SG_ 611 UPC_Object19_HeightProbability "Map Object 19 Height Propability
19号障碍物的高度置信度";
CM_ SG_ 611 UPCObject19PositionUpdateTime "Time Stamp for the time when the object 19 position update
19号障碍物坐标位置更新的时间戳";
CM_ SG_ 611 UPC_Object19_Point1PositionX "Map object 19, X axis of point 1 in vehicle coordinate system.
以车辆后轴中心为原点的19号障碍物point 1的X坐标";
CM_ SG_ 611 UPC_Object19_Point1PositionY "Map object 19, Y axis of point 1 in vehicle coordinate system.
以车辆后轴中心为原点的19号障碍物point 1的Y坐标";
CM_ SG_ 611 UPC_Object19_Point2PositionX "Map object 19, X axis of point 2 in vehicle coordinate system.
以车辆后轴中心为原点的19号障碍物point 2的X坐标";
CM_ SG_ 611 UPC_Object19_Point2PositionY "Map object 19, Y axis of point 2 in vehicle coordinate system.
以车辆后轴中心为原点的19号障碍物point 2的Y坐标";
CM_ SG_ 611 UPC_Object19_ID "Object 19 ID
19号障碍物的ID号";
CM_ SG_ 611 UPC_Object20_Type "Map Object 20 Type
20号障碍物类型";
CM_ SG_ 611 UPC_Object20_ExistProbability "Map Object 20 Exist Propability
20号障碍物的存在置信度";
CM_ SG_ 611 UPC_Object20_Height "Map Object 20 Height Classification
20号障碍物的高度等级";
CM_ SG_ 611 UPC_Object20_HeightProbability "Map Object 20 Height Propability
20号障碍物的高度置信度";
CM_ SG_ 611 UPCObject20PositionUpdateTime "Time Stamp for the time when the object 20 position update
20号障碍物坐标位置更新的时间戳";
CM_ SG_ 611 UPC_Object20_Point1PositionX "Map object 20, X axis of point 1 in vehicle coordinate system.
以车辆后轴中心为原点的20号障碍物point 1的X坐标";
CM_ SG_ 611 UPC_Object20_Point1PositionY "Map object 20, Y axis of point 1 in vehicle coordinate system.
以车辆后轴中心为原点的20号障碍物point 1的Y坐标";
CM_ SG_ 611 UPC_Object20_Point2PositionX "Map object 20, X axis of point 2 in vehicle coordinate system.
以车辆后轴中心为原点的20号障碍物point 2的X坐标";
CM_ SG_ 611 UPC_Object20_Point2PositionY "Map object 20, Y axis of point 2 in vehicle coordinate system.
以车辆后轴中心为原点的20号障碍物point 2的Y坐标";
CM_ SG_ 611 UPC_Object20_ID "Object 20 ID
20号障碍物的ID号";
CM_ SG_ 611 PAS_Obj16_20_Checksum "Checksum";
CM_ SG_ 611 PAS_Obj16_20_RollingCounter "Message Rolling counter";
CM_ SG_ 624 UPC_ParkingSlot1_ID "Parking slot ID
车位ID号";
CM_ SG_ 624 UPC_ParkingSlot1_Status "Parking slot status
车位状态";
CM_ SG_ 624 UPC_ParkingSlot1_Type "Parking slot type
车位类型";
CM_ SG_ 624 UPC_ParkingSlot1_ObjectType "Object type behind the parking slot
车位深度的后侧的障碍物类型";
CM_ SG_ 624 UPC_ParkingSlot1_Length "The length of the parking slot
车位的长度";
CM_ SG_ 624 UPC_ParkingSlot1_Depth "The depth of the parking slot
车位的深度";
CM_ SG_ 624 UPCParkSlot1Point1ObjectType "Object type of first point of parking slot
探测到车位的第一个顶点障碍物类型";
CM_ SG_ 624 UPCParkSlot1Point2ObjectType "Object type of second point of parking slot
探测到车位的第二个顶点障碍物类型";
CM_ SG_ 624 UPCParkSlot1Point1PositionAngle "First point angle of parking slot
以车辆后轴中心为原点，车辆行进方向X轴延长线和车位第一个顶点障碍物的水平延长线的夹角角度";
CM_ SG_ 624 UPCParkSlot1Point2PositionAngle "Second point angle of parking slot
以车辆后轴中心为原点，车辆行进方向X轴延长线和车位第二个顶点障碍物的水平延长线的夹角角度";
CM_ SG_ 624 UPCParkSlot1Point1PositionX "Parking slot first point position in X Coordinates.
以车辆后轴中心为原点的x坐标";
CM_ SG_ 624 UPCParkSlot1Point1PositionY "Parking slot first point position in Y Coordinates.
以车辆后轴中心为原点的y坐标";
CM_ SG_ 624 UPCParkSlot1Point2PositionX "Parking slot second point position in X Coordinates.
以车辆后轴中心为原点的x坐标";
CM_ SG_ 624 UPCParkSlot1Point2PositionY "Parking slot second point position in Y Coordinates.
以车辆后轴中心为原点的y坐标";
CM_ SG_ 624 UPCParkSlot1PositionUpdateTime "Time Stamp for the time when the parking slot position update
车位坐标位置更新的时间戳";
CM_ SG_ 624 UPC_ParkingSlot2_ID "Parking slot ID
车位ID号";
CM_ SG_ 624 UPC_ParkingSlot2_Status "Parking slot status
车位状态";
CM_ SG_ 624 UPC_ParkingSlot2_Type "Parking slot type
车位类型";
CM_ SG_ 624 UPC_ParkingSlot2_ObjectType "Object type behind the parking slot
车位深度的后侧的障碍物类型";
CM_ SG_ 624 UPC_ParkingSlot2_Length "The length of the parking slot
车位的长度";
CM_ SG_ 624 UPC_ParkingSlot2_Depth "The depth of the parking slot
车位的深度";
CM_ SG_ 624 UPCParkSlot2Point1ObjectType "Object type of first point of parking slot
探测到车位的第一个顶点障碍物类型";
CM_ SG_ 624 UPCParkSlot2Point2ObjectType "Object type of second point of parking slot
探测到车位的第二个顶点障碍物类型";
CM_ SG_ 624 UPCParkSlot2Point1PositionAngle "First point angle of parking slot
以车辆后轴中心为原点，车辆行进方向X轴延长线和车位第一个顶点障碍物的水平延长线的夹角角度";
CM_ SG_ 624 UPCParkSlot2Point2PositionAngle "Second point angle of parking slot
以车辆后轴中心为原点，车辆行进方向X轴延长线和车位第二个顶点障碍物的水平延长线的夹角角度";
CM_ SG_ 624 UPCParkSlot2Point1PositionX "Parking slot first point position in X Coordinates.
以车辆后轴中心为原点的x坐标";
CM_ SG_ 624 UPCParkSlot2Point1PositionY "Parking slot first point position in Y Coordinates.
以车辆后轴中心为原点的y坐标";
CM_ SG_ 624 UPCParkSlot2Point2PositionX "Parking slot second point position in X Coordinates.
以车辆后轴中心为原点的x坐标";
CM_ SG_ 624 UPCParkSlot2Point2PositionY "Parking slot second point position in Y Coordinates.
以车辆后轴中心为原点的y坐标";
CM_ SG_ 624 UPCParkSlot2PositionUpdateTime "Time Stamp for the time when the parking slot position update
车位坐标位置更新的时间戳";
CM_ SG_ 624 UPC_ParkingSlot3_ID "Parking slot ID
车位ID号";
CM_ SG_ 624 UPC_ParkingSlot3_Status "Parking slot status
车位状态";
CM_ SG_ 624 UPC_ParkingSlot3_Type "Parking slot type
车位类型";
CM_ SG_ 624 UPC_ParkingSlot3_ObjectType "Object type behind the parking slot
车位深度的后侧的障碍物类型";
CM_ SG_ 624 UPC_ParkingSlot3_Length "The length of the parking slot
车位的长度";
CM_ SG_ 624 UPC_ParkingSlot3_Depth "The depth of the parking slot
车位的深度";
CM_ SG_ 624 UPCParkSlot3Point1ObjectType "Object type of first point of parking slot
探测到车位的第一个顶点障碍物类型";
CM_ SG_ 624 UPCParkSlot3Point2ObjectType "Object type of second point of parking slot
探测到车位的第二个顶点障碍物类型";
CM_ SG_ 624 UPCParkSlot3Point1PositionAngle "First point angle of parking slot
以车辆后轴中心为原点，车辆行进方向X轴延长线和车位第一个顶点障碍物的水平延长线的夹角角度";
CM_ SG_ 624 UPCParkSlot3Point2PositionAngle "Second point angle of parking slot
以车辆后轴中心为原点，车辆行进方向X轴延长线和车位第二个顶点障碍物的水平延长线的夹角角度";
CM_ SG_ 624 UPCParkSlot3Point1PositionX "Parking slot first point position in X Coordinates.
以车辆后轴中心为原点的x坐标";
CM_ SG_ 624 UPCParkSlot3Point1PositionY "Parking slot first point position in Y Coordinates.
以车辆后轴中心为原点的y坐标";
CM_ SG_ 624 UPCParkSlot3Point2PositionX "Parking slot second point position in X Coordinates.
以车辆后轴中心为原点的x坐标";
CM_ SG_ 624 UPCParkSlot3Point2PositionY "Parking slot second point position in Y Coordinates.
以车辆后轴中心为原点的y坐标";
CM_ SG_ 624 UPCParkSlot3PositionUpdateTime "Time Stamp for the time when the parking slot position update
车位坐标位置更新的时间戳";
CM_ SG_ 624 PAS_Slot1_3_Checksum "Checksum";
CM_ SG_ 624 PAS_Slot1_3_RollingCounter "Message Rolling counter";
CM_ SG_ 625 UPC_ParkingSlot4_ID "Parking slot ID
车位ID号";
CM_ SG_ 625 UPC_ParkingSlot4_Status "Parking slot status
车位状态";
CM_ SG_ 625 UPC_ParkingSlot4_Type "Parking slot type
车位类型";
CM_ SG_ 625 UPC_ParkingSlot4_ObjectType "Object type behind the parking slot
车位深度的后侧的障碍物类型";
CM_ SG_ 625 UPC_ParkingSlot4_Length "The length of the parking slot
车位的长度";
CM_ SG_ 625 UPC_ParkingSlot4_Depth "The depth of the parking slot
车位的深度";
CM_ SG_ 625 UPCParkSlot4Point1ObjectType "Object type of first point of parking slot
探测到车位的第一个顶点障碍物类型";
CM_ SG_ 625 UPCParkSlot4Point2ObjectType "Object type of second point of parking slot
探测到车位的第二个顶点障碍物类型";
CM_ SG_ 625 UPCParkSlot4Point1PositionAngle "First point angle of parking slot
以车辆后轴中心为原点，车辆行进方向X轴延长线和车位第一个顶点障碍物的水平延长线的夹角角度";
CM_ SG_ 625 UPCParkSlot4Point2PositionAngle "Second point angle of parking slot
以车辆后轴中心为原点，车辆行进方向X轴延长线和车位第二个顶点障碍物的水平延长线的夹角角度";
CM_ SG_ 625 UPCParkSlot4Point1PositionX "Parking slot first point position in X Coordinates.
以车辆后轴中心为原点的x坐标";
CM_ SG_ 625 UPCParkSlot4Point1PositionY "Parking slot first point position in Y Coordinates.
以车辆后轴中心为原点的y坐标";
CM_ SG_ 625 UPCParkSlot4Point2PositionX "Parking slot second point position in X Coordinates.
以车辆后轴中心为原点的x坐标";
CM_ SG_ 625 UPCParkSlot4Point2PositionY "Parking slot second point position in Y Coordinates.
以车辆后轴中心为原点的y坐标";
CM_ SG_ 625 UPCParkSlot4PositionUpdateTime "Time Stamp for the time when the parking slot position update
车位坐标位置更新的时间戳";
CM_ SG_ 625 UPC_ParkingSlot5_ID "Parking slot ID
车位ID号";
CM_ SG_ 625 UPC_ParkingSlot5_Status "Parking slot status
车位状态";
CM_ SG_ 625 UPC_ParkingSlot5_Type "Parking slot type
车位类型";
CM_ SG_ 625 UPC_ParkingSlot5_ObjectType "Object type behind the parking slot
车位深度的后侧的障碍物类型";
CM_ SG_ 625 UPC_ParkingSlot5_Length "The length of the parking slot
车位的长度";
CM_ SG_ 625 UPC_ParkingSlot5_Depth "The depth of the parking slot
车位的深度";
CM_ SG_ 625 UPCParkSlot5Point1ObjectType "Object type of first point of parking slot
探测到车位的第一个顶点障碍物类型";
CM_ SG_ 625 UPCParkSlot5Point2ObjectType "Object type of second point of parking slot
探测到车位的第二个顶点障碍物类型";
CM_ SG_ 625 UPCParkSlot5Point1PositionAngle "First point angle of parking slot
以车辆后轴中心为原点，车辆行进方向X轴延长线和车位第一个顶点障碍物的水平延长线的夹角角度";
CM_ SG_ 625 UPCParkSlot5Point2PositionAngle "Second point angle of parking slot
以车辆后轴中心为原点，车辆行进方向X轴延长线和车位第二个顶点障碍物的水平延长线的夹角角度";
CM_ SG_ 625 UPCParkSlot5Point1PositionX "Parking slot first point position in X Coordinates.
以车辆后轴中心为原点的x坐标";
CM_ SG_ 625 UPCParkSlot5Point1PositionY "Parking slot first point position in Y Coordinates.
以车辆后轴中心为原点的y坐标";
CM_ SG_ 625 UPCParkSlot5Point2PositionX "Parking slot second point position in X Coordinates.
以车辆后轴中心为原点的x坐标";
CM_ SG_ 625 UPCParkSlot5Point2PositionY "Parking slot second point position in Y Coordinates.
以车辆后轴中心为原点的y坐标";
CM_ SG_ 625 UPCParkSlot5PositionUpdateTime "Time Stamp for the time when the parking slot position update
车位坐标位置更新的时间戳";
CM_ SG_ 625 UPC_ParkingSlot6_ID "Parking slot ID
车位ID号";
CM_ SG_ 625 UPC_ParkingSlot6_Status "Parking slot status
车位状态";
CM_ SG_ 625 UPC_ParkingSlot6_Type "Parking slot type
车位类型";
CM_ SG_ 625 UPC_ParkingSlot6_ObjectType "Object type behind the parking slot
车位深度的后侧的障碍物类型";
CM_ SG_ 625 UPC_ParkingSlot6_Length "The length of the parking slot
车位的长度";
CM_ SG_ 625 UPC_ParkingSlot6_Depth "The depth of the parking slot
车位的深度";
CM_ SG_ 625 UPCParkSlot6Point1ObjectType "Object type of first point of parking slot
探测到车位的第一个顶点障碍物类型";
CM_ SG_ 625 UPCParkSlot6Point2ObjectType "Object type of second point of parking slot
探测到车位的第二个顶点障碍物类型";
CM_ SG_ 625 UPCParkSlot6Point1PositionAngle "First point angle of parking slot
以车辆后轴中心为原点，车辆行进方向X轴延长线和车位第一个顶点障碍物的水平延长线的夹角角度";
CM_ SG_ 625 UPCParkSlot6Point2PositionAngle "Second point angle of parking slot
以车辆后轴中心为原点，车辆行进方向X轴延长线和车位第二个顶点障碍物的水平延长线的夹角角度";
CM_ SG_ 625 UPCParkSlot6Point1PositionX "Parking slot first point position in X Coordinates.
以车辆后轴中心为原点的x坐标";
CM_ SG_ 625 UPCParkSlot6Point1PositionY "Parking slot first point position in Y Coordinates.
以车辆后轴中心为原点的y坐标";
CM_ SG_ 625 UPCParkSlot6Point2PositionX "Parking slot second point position in X Coordinates.
以车辆后轴中心为原点的x坐标";
CM_ SG_ 625 UPCParkSlot6Point2PositionY "Parking slot second point position in Y Coordinates.
以车辆后轴中心为原点的y坐标";
CM_ SG_ 625 UPCParkSlot6PositionUpdateTime "Time Stamp for the time when the parking slot position update
车位坐标位置更新的时间戳";
CM_ SG_ 625 PAS_Slot4_6_Checksum "Checksum";
CM_ SG_ 625 PAS_Slot4_6_RollingCounter "Message Rolling counter";
CM_ SG_ 626 UPC_ParkingSlot7_ID "Parking slot ID
车位ID号";
CM_ SG_ 626 UPC_ParkingSlot7_Status "Parking slot status
车位状态";
CM_ SG_ 626 UPC_ParkingSlot7_Type "Parking slot type
车位类型";
CM_ SG_ 626 UPC_ParkingSlot7_ObjectType "Object type behind the parking slot
车位深度的后侧的障碍物类型";
CM_ SG_ 626 UPC_ParkingSlot7_Length "The length of the parking slot
车位的长度";
CM_ SG_ 626 UPC_ParkingSlot7_Depth "The depth of the parking slot
车位的深度";
CM_ SG_ 626 UPCParkSlot7Point1ObjectType "Object type of first point of parking slot
探测到车位的第一个顶点障碍物类型";
CM_ SG_ 626 UPCParkSlot7Point2ObjectType "Object type of second point of parking slot
探测到车位的第二个顶点障碍物类型";
CM_ SG_ 626 UPCParkSlot7Point1PositionAngle "First point angle of parking slot
以车辆后轴中心为原点，车辆行进方向X轴延长线和车位第一个顶点障碍物的水平延长线的夹角角度";
CM_ SG_ 626 UPCParkSlot7Point2PositionAngle "Second point angle of parking slot
以车辆后轴中心为原点，车辆行进方向X轴延长线和车位第二个顶点障碍物的水平延长线的夹角角度";
CM_ SG_ 626 UPCParkSlot7Point1PositionX "Parking slot first point position in X Coordinates.
以车辆后轴中心为原点的x坐标";
CM_ SG_ 626 UPCParkSlot7Point1PositionY "Parking slot first point position in Y Coordinates.
以车辆后轴中心为原点的y坐标";
CM_ SG_ 626 UPCParkSlot7Point2PositionX "Parking slot second point position in X Coordinates.
以车辆后轴中心为原点的x坐标";
CM_ SG_ 626 UPCParkSlot7Point2PositionY "Parking slot second point position in Y Coordinates.
以车辆后轴中心为原点的y坐标";
CM_ SG_ 626 UPCParkSlot7PositionUpdateTime "Time Stamp for the time when the parking slot position update
车位坐标位置更新的时间戳";
CM_ SG_ 626 UPC_ParkingSlot8_ID "Parking slot ID
车位ID号";
CM_ SG_ 626 UPC_ParkingSlot8_Status "Parking slot status
车位状态";
CM_ SG_ 626 UPC_ParkingSlot8_Type "Parking slot type
车位类型";
CM_ SG_ 626 UPC_ParkingSlot8_ObjectType "Object type behind the parking slot
车位深度的后侧的障碍物类型";
CM_ SG_ 626 UPC_ParkingSlot8_Length "The length of the parking slot
车位的长度";
CM_ SG_ 626 UPC_ParkingSlot8_Depth "The depth of the parking slot
车位的深度";
CM_ SG_ 626 UPCParkSlot8Point1ObjectType "Object type of first point of parking slot
探测到车位的第一个顶点障碍物类型";
CM_ SG_ 626 UPCParkSlot8Point2ObjectType "Object type of second point of parking slot
探测到车位的第二个顶点障碍物类型";
CM_ SG_ 626 UPCParkSlot8Point1PositionAngle "First point angle of parking slot
以车辆后轴中心为原点，车辆行进方向X轴延长线和车位第一个顶点障碍物的水平延长线的夹角角度";
CM_ SG_ 626 UPCParkSlot8Point2PositionAngle "Second point angle of parking slot
以车辆后轴中心为原点，车辆行进方向X轴延长线和车位第二个顶点障碍物的水平延长线的夹角角度";
CM_ SG_ 626 UPCParkSlot8Point1PositionX "Parking slot first point position in X Coordinates.
以车辆后轴中心为原点的x坐标";
CM_ SG_ 626 UPCParkSlot8Point1PositionY "Parking slot first point position in Y Coordinates.
以车辆后轴中心为原点的y坐标";
CM_ SG_ 626 UPCParkSlot8Point2PositionX "Parking slot second point position in X Coordinates.
以车辆后轴中心为原点的x坐标";
CM_ SG_ 626 UPCParkSlot8Point2PositionY "Parking slot second point position in Y Coordinates.
以车辆后轴中心为原点的y坐标";
CM_ SG_ 626 UPCParkSlot8PositionUpdateTime "Time Stamp for the time when the parking slot position update
车位坐标位置更新的时间戳";
CM_ SG_ 626 PAS_Slot7_8_Checksum "Checksum";
CM_ SG_ 626 PAS_Slot7_8_RollingCounter "Message Rolling counter";
CM_ SG_ 640 UPC_VehiclePosition_X "Vehicle position in X Coordinate
车辆的X坐标";
CM_ SG_ 640 UPC_VehiclePosition_Y "Vehicle position in Y Coordinate
车辆的Y坐标";
CM_ SG_ 640 UPCVehiclePositionUpdateTime "Time Stamp for the time when the vehicle position update
车辆坐标更新的时间戳";
CM_ SG_ 640 UPC_VehiclePosition_Curvature "Vehicle curvature
车辆的行驶曲率半径";
CM_ SG_ 640 UPC_VehiclePosition_YawAngle "Vehicle yawangle
车辆的横摆角";
CM_ SG_ 640 UPCVehiclePositionDriveDistance "Vehicle drive distance
车辆的行驶距离";
CM_ SG_ 640 PAS_VehPos_Checksum "Checksum";
CM_ SG_ 640 PAS_VehPos_RollingCounter "Message Rolling counter";
CM_ SG_ 641 PAS_PSL_Checksum "校验码";
CM_ SG_ 641 PAS_PSL_RollingCounter "消息计数器";
CM_ SG_ 642 PAS_EchoMap_Checksum "校验码";
CM_ SG_ 642 PAS_EchoMap_RollingCounter "消息计数器";
CM_ SG_ 768 MDC_PAS_Control "MDC命令PAS的系统状态
0x00:system off (暂时Reserved，网络上有信号，自动维持standby状态，因此可以省略system off指令）
0x01:standby
0x02:Enable
0x03:reserved";
CM_ SG_ 768 MDC_PAS_Control_RollingCounter "消息计数器";
CM_ SG_ 768 MDC_PAS_Control_Checksum "校验码";
CM_ SG_ 768 Fill4bit "填充位";
CM_ SG_ 769 MDC_ESC_VehicleSpeed "ABS_ESC信号提示车速";
CM_ SG_ 769 MDC_ESC_VehicleSpeed_Valid "车速有效";
CM_ SG_ 769 MDC_SAS_SteerWheelAngle "实际方向盘转向角";
CM_ SG_ 769 MDC_SAS_SteerWheelAngle_Valid "方向盘转向角有效";
CM_ SG_ 769 MDC_BCM_OutTemp "用于温度补偿";
CM_ SG_ 769 MDC_BCM_OutTemp_Valid "温度有效";
CM_ SG_ 769 MDC_VCU_GearStatus "档位
0x00:P
0x01:N
0x02:D
0x03:R";
CM_ SG_ 769 MDC_VCU_GearStatus_Valid "档位有效";
CM_ SG_ 769 MDC_ESC_FLWheelSpeedRC "ESC信号提示左前轮速脉冲信号";
CM_ SG_ 769 MDC_ESC_FLWheelSpeedRC_Valid "ESC信号提示左前轮速脉冲信号有效";
CM_ SG_ 769 MDC_ESC_FRWheelSpeedRC "ESC信号提示右前轮速脉冲信号";
CM_ SG_ 769 MDC_ESC_FRWheelSpeedRC_Valid "ESC信号提示右前轮速脉冲信号有效";
CM_ SG_ 769 MDC_ESC_RLWheelSpeedRC "ESC 信号提示左后轮速脉冲信号";
CM_ SG_ 769 MDC_ESC_RLWheelSpeedRC_Valid "ESC 信号提示左后轮速脉冲信号有效";
CM_ SG_ 769 MDC_ESC_RRWheelSpeedRC "ESC信号提示右后轮速脉冲信号";
CM_ SG_ 769 MDC_ESC_RRWheelSpeedRC_Valid "ESC信号提示右后轮速脉冲信号有效";
CM_ SG_ 769 MDC_ESC_FLWheelDirection "ESC指示左前轮方向";
CM_ SG_ 769 MDC_ESC_FLWheelDirection_Valid "ESC指示左前轮方向有效";
CM_ SG_ 769 MDC_ESC_FRWheelDirection "ESC指示右前轮方向";
CM_ SG_ 769 MDC_ESC_FRWheelDirection_Valid "ESC指示右前轮方向有效";
CM_ SG_ 769 MDC_ESC_RLWheelDirection "ESC指示左后轮方向";
CM_ SG_ 769 MDC_ESC_RLWheelDirection_Valid "ESC指示左后轮方向有效";
CM_ SG_ 769 MDC_ESC_RRWheelDirection "ESC指示右后轮方向";
CM_ SG_ 769 MDC_ESC_RRWheelDirection_Valid "ESC指示右后轮方向有效";
CM_ SG_ 769 MDC_VehStatus_RollingCounter "消息计数器";
CM_ SG_ 769 MDC_VehStatus_Checksum "校验码";
CM_ SG_ 769 YawRate "Yaw RateWz横摆角速度";
CM_ SG_ 769 YawRateSensor_St "Yaw Rate Sensor State
Wz横摆角速度状态";
CM_ SG_ 769 wheelspeedValid "轮速信息有效性";
CM_ SG_ 769 wheelspeedFl "左前轮轮速";
CM_ SG_ 769 wheelspeedFr "右前轮轮速";
CM_ SG_ 769 wheelspeedRr "右后轮轮速";
CM_ SG_ 769 wheelspeedRl "左后轮轮速";
CM_ SG_ 769 ecasVehiclePositionState "整车位置状态";
CM_ SG_ 769 ecasVehicleUpDownState "整车升降状态";
CM_ SG_ 769 VehiclePositionStateValid "整车位置状态有效位";
CM_ SG_ 769 VehicleUpDownStateValid "整车升降状态有效位";
CM_ SG_ 770 PAS_Sonar1_Req "UPA1号探头工作模式指令";
CM_ SG_ 770 PAS_Sonar1_Req_counter "UPA1号探头工作模式指令计数";
CM_ SG_ 770 PAS_Sonar2_Req "UPA2号探头工作模式指令";
CM_ SG_ 770 PAS_Sonar2_Req_counter "UPA1号探头工作模式指令计数";
CM_ SG_ 770 PAS_Sonar3_Req "UPA3号探头工作模式指令";
CM_ SG_ 770 PAS_Sonar3_Req_counter "UPA1号探头工作模式指令计数";
CM_ SG_ 770 PAS_Sonar4_Req "UPA4号探头工作模式指令";
CM_ SG_ 770 PAS_Sonar4_Req_counter "UPA1号探头工作模式指令计数";
CM_ SG_ 770 PAS_Sonar7_Req "UPA7号探头工作模式指令";
CM_ SG_ 770 PAS_Sonar7_Req_counter "UPA1号探头工作模式指令计数";
CM_ SG_ 770 PAS_Sonar8_Req "UPA8号探头工作模式指令";
CM_ SG_ 770 PAS_Sonar8_Req_counter "UPA1号探头工作模式指令计数";
CM_ SG_ 770 PAS_Sonar9_Req "UPA9号探头工作模式指令";
CM_ SG_ 770 PAS_Sonar9_Req_counter "UPA1号探头工作模式指令计数";
CM_ SG_ 770 PAS_Sonar10_Req "UPA10号探头工作模式指令";
CM_ SG_ 770 PAS_Sonar10_Req_counter "UPA1号探头工作模式指令计数";
CM_ SG_ 770 PAS_Sonar0_Req "UPA0号探头工作模式指令";
CM_ SG_ 770 PAS_Sonar0_Req_counter "UPA1号探头工作模式指令计数";
CM_ SG_ 770 PAS_Sonar5_Req "UPA5号探头工作模式指令";
CM_ SG_ 770 PAS_Sonar5_Req_counter "UPA1号探头工作模式指令计数";
CM_ SG_ 770 PAS_Sonar6_Req "UPA6号探头工作模式指令";
CM_ SG_ 770 PAS_Sonar6_Req_counter "UPA1号探头工作模式指令计数";
CM_ SG_ 770 PAS_Sonar11_Req "UPA11号探头工作模式指令";
CM_ SG_ 770 PAS_Sonar11_Req_counter "UPA1号探头工作模式指令计数";
CM_ SG_ 770 Sonar_Req_RollingCounter "消息计数器";
CM_ SG_ 770 Sonar_Req_Checksum "校验码";
CM_ SG_ 770 Fill4bit "填充位";
CM_ SG_ 770 PAS_Function_Req "发波模式控制选择";
CM_ SG_ 771 Ack_Alarm_Id "告警Id";
CM_ SG_ 771 Ack_Alarm_State "告警状态";
CM_ SG_ 771 Ack_Alarm_Level "告警级别";
CM_ SG_ 771 Ack_Transaction_Id "告警序列号";
CM_ SG_ 771 Ack_Alarm_Checksum "校验码";
CM_ SG_ 771 Ack_Alarm_RollingCounter "消息计数器";
CM_ SG_ 771 Fill4bit "填充位";
CM_ SG_ 772 Sync_Type "Time synchronization message - type
时间同步报文的类型
(Type=0x20:Tsync,
Type=0x28:TSync FUP)";
CM_ SG_ 772 Sync_CRC "Time synchronization message - CRC (Cyclic Redundancy Check)
循环冗余校验值";
CM_ SG_ 772 Sync_Counter "Time synchronization message - sequence counter指令计数器";
CM_ SG_ 772 Sync_TimeDomain "Time synchronization message - time domain时间同步域";
CM_ SG_ 772 Sync_OVS "Time synchronization message - Overflow of second溢出时间";
CM_ SG_ 772 Sync_SGW "Time synchronization message - Time Gateway synchronization status网关时间同步状态";
CM_ SG_ 772 Sync_Reserved "in FUP PDU,default = 0Reserved for Time Sync function";
CM_ SG_ 772 Sync_SyncTime "Time synchronization message - Synchronization time同步时间";
CM_ SG_ 928 MDC_RandomByte1 "随机数_MDC";
CM_ SG_ 928 MDC_RandomByte2 "随机数_MDC";
CM_ SG_ 928 MDC_RandomByte3 "随机数_MDC";
CM_ SG_ 928 MDC_RandomByte4 "随机数_MDC";
CM_ SG_ 928 MDC_RandomByte5 "随机数_MDC";
CM_ SG_ 928 MDC_RandomByte6 "随机数_MDC";
CM_ SG_ 928 MDC_RandomByte7 "随机数_MDC";
CM_ SG_ 928 MDC_RandomByte8 "随机数_MDC";
CM_ SG_ 928 MDC_SessionID "密钥协商会话ID";
CM_ SG_ 929 MDC_Response_Result "MDC校验结果，如果会话ID不一致，MDC将该值设为失败，同时MDC结束本次认证流程。传感器收到该结果为失败，也结束本次认证流程；如果该结果为成功，则继续后需处理。";
CM_ SG_ 929 MDC_Response_SessionID "密钥协商会话ID";
CM_ SG_ 929 MDC_Response_CMACByte1 "MDC发送给传感器的挑战应答值，CMAC（随机数拼接会话ID）后，取结果的低64位";
CM_ SG_ 929 MDC_Response_CMACByte2 "MDC发送给传感器的挑战应答值，CMAC（随机数拼接会话ID）后，取结果的低64位";
CM_ SG_ 929 MDC_Response_CMACByte3 "MDC发送给传感器的挑战应答值，CMAC（随机数拼接会话ID）后，取结果的低64位";
CM_ SG_ 929 MDC_Response_CMACByte4 "MDC发送给传感器的挑战应答值，CMAC（随机数拼接会话ID）后，取结果的低64位";
CM_ SG_ 929 MDC_Response_CMACByte5 "MDC发送给传感器的挑战应答值，CMAC（随机数拼接会话ID）后，取结果的低64位";
CM_ SG_ 929 MDC_Response_CMACByte6 "MDC发送给传感器的挑战应答值，CMAC（随机数拼接会话ID）后，取结果的低64位";
CM_ SG_ 929 MDC_Response_CMACByte7 "MDC发送给传感器的挑战应答值，CMAC（随机数拼接会话ID）后，取结果的低64位";
CM_ SG_ 929 MDC_Response_CMACByte8 "MDC发送给传感器的挑战应答值，CMAC（随机数拼接会话ID）后，取结果的低64位";
CM_ SG_ 960 Mdc_KeyLearnSubID "获取传感器密钥学习状态，此字段携带1";
CM_ SG_ 960 Mdc_KeyLearn_Numbers "查询密钥学习状态个数，最多12个";
CM_ SG_ 960 Mdc_KeyLearn_SKID1 "根据查询密钥个数读取密钥ID个数，1~12。0为无效值";
CM_ SG_ 960 Mdc_KeyLearn_SKID2 "根据查询密钥个数读取密钥ID个数，1~12。0为无效值";
CM_ SG_ 960 Mdc_KeyLearn_SKID3 "根据查询密钥个数读取密钥ID个数，1~12。0为无效值";
CM_ SG_ 960 Mdc_KeyLearn_SKID4 "根据查询密钥个数读取密钥ID个数，1~12。0为无效值";
CM_ SG_ 960 Mdc_KeyLearn_SKID5 "根据查询密钥个数读取密钥ID个数，1~12。0为无效值";
CM_ SG_ 960 Mdc_KeyLearn_SKID6 "根据查询密钥个数读取密钥ID个数，1~12。0为无效值";
CM_ SG_ 960 Mdc_KeyLearn_SKID7 "根据查询密钥个数读取密钥ID个数，1~12。0为无效值";
CM_ SG_ 960 Mdc_KeyLearn_SKID8 "根据查询密钥个数读取密钥ID个数，1~12。0为无效值";
CM_ SG_ 960 Mdc_KeyLearn_SKID9 "根据查询密钥个数读取密钥ID个数，1~12。0为无效值";
CM_ SG_ 960 Mdc_KeyLearn_SKID10 "根据查询密钥个数读取密钥ID个数，1~12。0为无效值";
CM_ SG_ 960 Mdc_KeyLearn_SKID11 "根据查询密钥个数读取密钥ID个数，1~12。0为无效值";
CM_ SG_ 960 Mdc_KeyLearn_SKID12 "根据查询密钥个数读取密钥ID个数，1~12。0为无效值";
CM_ SG_ 962 Mdc_KeyLearnSubID_Send "MDC给传感器发送SKC和SC，此字段携带2";
CM_ SG_ 962 Mdc_KeyLearn_transmit_SKID "传输保护密钥ID";
CM_ SG_ 962 Mdc_KeyLearn_update_SKID "更新密钥ID";
CM_ SG_ 962 Mdc_KeyLearn_SKCByte1 "128bit的SKC密文，AES128-GCM，none-padding";
CM_ SG_ 962 Mdc_KeyLearn_SKCByte2 "128bit的SKC密文，AES128-GCM，none-padding";
CM_ SG_ 962 Mdc_KeyLearn_SKCByte3 "128bit的SKC密文，AES128-GCM，none-padding";
CM_ SG_ 962 Mdc_KeyLearn_SKCByte4 "128bit的SKC密文，AES128-GCM，none-padding";
CM_ SG_ 962 Mdc_KeyLearn_SKCByte5 "128bit的SKC密文，AES128-GCM，none-padding";
CM_ SG_ 962 Mdc_KeyLearn_SKCByte6 "128bit的SKC密文，AES128-GCM，none-padding";
CM_ SG_ 962 Mdc_KeyLearn_SKCByte7 "128bit的SKC密文，AES128-GCM，none-padding";
CM_ SG_ 962 Mdc_KeyLearn_SKCByte8 "128bit的SKC密文，AES128-GCM，none-padding";
CM_ SG_ 962 Mdc_KeyLearn_SKCByte9 "128bit的SKC密文，AES128-GCM，none-padding";
CM_ SG_ 962 Mdc_KeyLearn_SKCByte10 "128bit的SKC密文，AES128-GCM，none-padding";
CM_ SG_ 962 Mdc_KeyLearn_SKCByte11 "128bit的SKC密文，AES128-GCM，none-padding";
CM_ SG_ 962 Mdc_KeyLearn_SKCByte12 "128bit的SKC密文，AES128-GCM，none-padding";
CM_ SG_ 962 Mdc_KeyLearn_SKCByte13 "128bit的SKC密文，AES128-GCM，none-padding";
CM_ SG_ 962 Mdc_KeyLearn_SKCByte14 "128bit的SKC密文，AES128-GCM，none-padding";
CM_ SG_ 962 Mdc_KeyLearn_SKCByte15 "128bit的SKC密文，AES128-GCM，none-padding";
CM_ SG_ 962 Mdc_KeyLearn_SKCByte16 "128bit的SKC密文，AES128-GCM，none-padding";
CM_ SG_ 962 Mdc_KeyLearn_MACByte1 "GCM计算的MAC，AES128-GCM，none-padding";
CM_ SG_ 962 Mdc_KeyLearn_MACByte2 "GCM计算的MAC，AES129-GCM，none-padding";
CM_ SG_ 962 Mdc_KeyLearn_MACByte3 "GCM计算的MAC，AES130-GCM，none-padding";
CM_ SG_ 962 Mdc_KeyLearn_MACByte4 "GCM计算的MAC，AES131-GCM，none-padding";
CM_ SG_ 962 Mdc_KeyLearn_MACByte5 "GCM计算的MAC，AES132-GCM，none-padding";
CM_ SG_ 962 Mdc_KeyLearn_MACByte6 "GCM计算的MAC，AES133-GCM，none-padding";
CM_ SG_ 962 Mdc_KeyLearn_MACByte7 "GCM计算的MAC，AES134-GCM，none-padding";
CM_ SG_ 962 Mdc_KeyLearn_MACByte8 "GCM计算的MAC，AES135-GCM，none-padding";
CM_ SG_ 962 Mdc_KeyLearn_MACByte9 "GCM计算的MAC，AES136-GCM，none-padding";
CM_ SG_ 962 Mdc_KeyLearn_MACByte10 "GCM计算的MAC，AES137-GCM，none-padding";
CM_ SG_ 962 Mdc_KeyLearn_MACByte11 "GCM计算的MAC，AES138-GCM，none-padding";
CM_ SG_ 962 Mdc_KeyLearn_MACByte12 "GCM计算的MAC，AES139-GCM，none-padding";
CM_ SG_ 962 Mdc_KeyLearn_MACByte13 "GCM计算的MAC，AES140-GCM，none-padding";
CM_ SG_ 962 Mdc_KeyLearn_MACByte14 "GCM计算的MAC，AES141-GCM，none-padding";
CM_ SG_ 962 Mdc_KeyLearn_MACByte15 "GCM计算的MAC，AES142-GCM，none-padding";
CM_ SG_ 962 Mdc_KeyLearn_MACByte16 "GCM计算的MAC，AES143-GCM，none-padding";
CM_ SG_ 962 Mdc_KeyLearn_IVByte1 "96bit 的IV";
CM_ SG_ 962 Mdc_KeyLearn_IVByte2 "96bit 的IV";
CM_ SG_ 962 Mdc_KeyLearn_IVByte3 "96bit 的IV";
CM_ SG_ 962 Mdc_KeyLearn_IVByte4 "96bit 的IV";
CM_ SG_ 962 Mdc_KeyLearn_IVByte5 "96bit 的IV";
CM_ SG_ 962 Mdc_KeyLearn_IVByte6 "96bit 的IV";
CM_ SG_ 962 Mdc_KeyLearn_IVByte7 "96bit 的IV";
CM_ SG_ 962 Mdc_KeyLearn_IVByte8 "96bit 的IV";
CM_ SG_ 962 Mdc_KeyLearn_IVByte9 "96bit 的IV";
CM_ SG_ 962 Mdc_KeyLearn_IVByte10 "96bit 的IV";
CM_ SG_ 962 Mdc_KeyLearn_IVByte11 "96bit 的IV";
CM_ SG_ 962 Mdc_KeyLearn_IVByte12 "96bit 的IV";
CM_ SG_ 962 Mdc_KeyLearn_SC "3字节SC";
CM_ SG_ 963 Mdc_KeyLearnSubID_SKSetting "MDC设置传感器学习状态，传感器收到此消息置为已学习。此字段携带5";
CM_ SG_ 963 Mdc_KeyLearn_SKID "需要设置学习状态的密钥ID";
CM_ SG_ 964 Mdc_KeyLearnSubID_CleanID "MDC清除传感器学习状态，此字段携带6";
CM_ SG_ 964 Mdc_KeyLearn_Clean_SKID "清除学习状态的密钥ID。HuaweiPSK不能清除，此处不能携带0（密钥清除报文的保护密钥的ID）";
CM_ SG_ 964 Mdc_KeyLearn_Clean_SCByte1 "密文=AES128-GCM(8bit密钥ID（低位） |24bit SC |96bit 填充0";
CM_ SG_ 964 Mdc_KeyLearn_Clean_SCByte2 "密文=AES128-GCM(8bit密钥ID（低位） |24bit SC |96bit 填充0";
CM_ SG_ 964 Mdc_KeyLearn_Clean_SCByte3 "密文=AES128-GCM(8bit密钥ID（低位） |24bit SC |96bit 填充0";
CM_ SG_ 964 Mdc_KeyLearn_Clean_SCByte4 "密文=AES128-GCM(8bit密钥ID（低位） |24bit SC |96bit 填充0";
CM_ SG_ 964 Mdc_KeyLearn_Clean_SCByte5 "密文=AES128-GCM(8bit密钥ID（低位） |24bit SC |96bit 填充0";
CM_ SG_ 964 Mdc_KeyLearn_Clean_SCByte6 "密文=AES128-GCM(8bit密钥ID（低位） |24bit SC |96bit 填充0";
CM_ SG_ 964 Mdc_KeyLearn_Clean_SCByte7 "密文=AES128-GCM(8bit密钥ID（低位） |24bit SC |96bit 填充0";
CM_ SG_ 964 Mdc_KeyLearn_Clean_SCByte8 "密文=AES128-GCM(8bit密钥ID（低位） |24bit SC |96bit 填充0";
CM_ SG_ 964 Mdc_KeyLearn_Clean_SCByte9 "密文=AES128-GCM(8bit密钥ID（低位） |24bit SC |96bit 填充0";
CM_ SG_ 964 Mdc_KeyLearn_Clean_SCByte10 "密文=AES128-GCM(8bit密钥ID（低位） |24bit SC |96bit 填充0";
CM_ SG_ 964 Mdc_KeyLearn_Clean_SCByte11 "密文=AES128-GCM(8bit密钥ID（低位） |24bit SC |96bit 填充0";
CM_ SG_ 964 Mdc_KeyLearn_Clean_SCByte12 "密文=AES128-GCM(8bit密钥ID（低位） |24bit SC |96bit 填充0";
CM_ SG_ 964 Mdc_KeyLearn_Clean_SCByte13 "密文=AES128-GCM(8bit密钥ID（低位） |24bit SC |96bit 填充0";
CM_ SG_ 964 Mdc_KeyLearn_Clean_SCByte14 "密文=AES128-GCM(8bit密钥ID（低位） |24bit SC |96bit 填充0";
CM_ SG_ 964 Mdc_KeyLearn_Clean_SCByte15 "密文=AES128-GCM(8bit密钥ID（低位） |24bit SC |96bit 填充0";
CM_ SG_ 964 Mdc_KeyLearn_Clean_SCByte16 "密文=AES128-GCM(8bit密钥ID（低位） |24bit SC |96bit 填充0";
CM_ SG_ 964 Mdc_KeyLearn_Clean_MACByte1 "AES-GCM计算的MAC";
CM_ SG_ 964 Mdc_KeyLearn_Clean_MACByte2 "AES-GCM计算的MAC";
CM_ SG_ 964 Mdc_KeyLearn_Clean_MACByte3 "AES-GCM计算的MAC";
CM_ SG_ 964 Mdc_KeyLearn_Clean_MACByte4 "AES-GCM计算的MAC";
CM_ SG_ 964 Mdc_KeyLearn_Clean_MACByte5 "AES-GCM计算的MAC";
CM_ SG_ 964 Mdc_KeyLearn_Clean_MACByte6 "AES-GCM计算的MAC";
CM_ SG_ 964 Mdc_KeyLearn_Clean_MACByte7 "AES-GCM计算的MAC";
CM_ SG_ 964 Mdc_KeyLearn_Clean_MACByte8 "AES-GCM计算的MAC";
CM_ SG_ 964 Mdc_KeyLearn_Clean_MACByte9 "AES-GCM计算的MAC";
CM_ SG_ 964 Mdc_KeyLearn_Clean_MACByte10 "AES-GCM计算的MAC";
CM_ SG_ 964 Mdc_KeyLearn_Clean_MACByte11 "AES-GCM计算的MAC";
CM_ SG_ 964 Mdc_KeyLearn_Clean_MACByte12 "AES-GCM计算的MAC";
CM_ SG_ 964 Mdc_KeyLearn_Clean_MACByte13 "AES-GCM计算的MAC";
CM_ SG_ 964 Mdc_KeyLearn_Clean_MACByte14 "AES-GCM计算的MAC";
CM_ SG_ 964 Mdc_KeyLearn_Clean_MACByte15 "AES-GCM计算的MAC";
CM_ SG_ 964 Mdc_KeyLearn_Clean_MACByte16 "AES-GCM计算的MAC";
CM_ SG_ 964 Mdc_KeyLearn_Clean_IVByte1 "96bit 的IV";
CM_ SG_ 964 Mdc_KeyLearn_Clean_IVByte2 "96bit 的IV";
CM_ SG_ 964 Mdc_KeyLearn_Clean_IVByte3 "96bit 的IV";
CM_ SG_ 964 Mdc_KeyLearn_Clean_IVByte4 "96bit 的IV";
CM_ SG_ 964 Mdc_KeyLearn_Clean_IVByte5 "96bit 的IV";
CM_ SG_ 964 Mdc_KeyLearn_Clean_IVByte6 "96bit 的IV";
CM_ SG_ 964 Mdc_KeyLearn_Clean_IVByte7 "96bit 的IV";
CM_ SG_ 964 Mdc_KeyLearn_Clean_IVByte8 "96bit 的IV";
CM_ SG_ 964 Mdc_KeyLearn_Clean_IVByte9 "96bit 的IV";
CM_ SG_ 964 Mdc_KeyLearn_Clean_IVByte10 "96bit 的IV";
CM_ SG_ 964 Mdc_KeyLearn_Clean_IVByte11 "96bit 的IV";
CM_ SG_ 964 Mdc_KeyLearn_Clean_IVByte12 "96bit 的IV";
CM_ SG_ 961 Mdc_VerifySubID_Random "MDC发送随机数，此字段携带1";
CM_ SG_ 961 Mdc_Verify_SKID "需要校验的密钥ID";
CM_ SG_ 961 Mdc_Verify_Random "4字节的随机数";
CM_ SG_ 965 Mdc_Verify_ResultID "MDC发送认证成功，此字段携带2";
CM_ SG_ 965 Mdc_Verify_Result_SKID "校验的密钥ID";
CM_ SG_ 773 sensorVersion "传感器版本";
BA_DEF_ BO_  "GenMsgSendType" ENUM  "Cycle","Event","CE";
BA_DEF_ BO_  "GenMsgCycleTime" INT 0 0;
BA_DEF_ SG_  "GenSigSendType" ENUM  "Cycle","OnChange","OnWrite","IfActive","OnChangeWithRepetition","OnWriteWithRepetition","IfActiveWithRepetition";
BA_DEF_ SG_  "GenSigStartValue" INT 0 0;
BA_DEF_ BO_  "VFrameFormat" ENUM  "StandardCAN","ExtendedCAN","reserved","reserved","reserved","reserved","reserved","reserved","reserved","reserved","reserved","reserved","reserved","reserved","StandardCAN_FD","ExtendedCAN_FD";
BA_DEF_DEF_  "GenMsgSendType" "Cycle";
BA_DEF_DEF_  "GenMsgCycleTime" 0;
BA_DEF_DEF_  "GenSigSendType" "Cycle";
BA_DEF_DEF_  "GenSigStartValue" 0;
BA_DEF_DEF_  "VFrameFormat" "";
BA_ "GenMsgCycleTime" BO_ 517 20;
BA_ "VFrameFormat" BO_ 517 14;
BA_ "GenMsgSendType" BO_ 544 1;
BA_ "GenMsgCycleTime" BO_ 560 40;
BA_ "GenMsgCycleTime" BO_ 576 1000;
BA_ "VFrameFormat" BO_ 576 14;
BA_ "GenMsgSendType" BO_ 592 1;
BA_ "VFrameFormat" BO_ 592 14;
BA_ "GenMsgCycleTime" BO_ 593 500;
BA_ "VFrameFormat" BO_ 593 14;
BA_ "GenMsgSendType" BO_ 672 1;
BA_ "GenMsgSendType" BO_ 673 1;
BA_ "VFrameFormat" BO_ 673 14;
BA_ "GenMsgSendType" BO_ 674 1;
BA_ "VFrameFormat" BO_ 674 14;
BA_ "GenMsgSendType" BO_ 706 1;
BA_ "VFrameFormat" BO_ 706 14;
BA_ "GenMsgSendType" BO_ 708 1;
BA_ "VFrameFormat" BO_ 708 14;
BA_ "GenMsgSendType" BO_ 707 1;
BA_ "VFrameFormat" BO_ 707 14;
BA_ "GenMsgCycleTime" BO_ 608 20;
BA_ "VFrameFormat" BO_ 608 14;
BA_ "GenMsgCycleTime" BO_ 609 20;
BA_ "VFrameFormat" BO_ 609 14;
BA_ "GenMsgCycleTime" BO_ 610 20;
BA_ "VFrameFormat" BO_ 610 14;
BA_ "GenMsgCycleTime" BO_ 611 20;
BA_ "VFrameFormat" BO_ 611 14;
BA_ "GenMsgCycleTime" BO_ 624 40;
BA_ "VFrameFormat" BO_ 624 14;
BA_ "GenMsgCycleTime" BO_ 625 40;
BA_ "VFrameFormat" BO_ 625 14;
BA_ "GenMsgCycleTime" BO_ 626 40;
BA_ "VFrameFormat" BO_ 626 14;
BA_ "GenMsgCycleTime" BO_ 640 20;
BA_ "VFrameFormat" BO_ 640 14;
BA_ "GenMsgCycleTime" BO_ 641 40;
BA_ "GenMsgCycleTime" BO_ 642 20;
BA_ "GenMsgCycleTime" BO_ 768 1000;
BA_ "GenMsgCycleTime" BO_ 769 20;
BA_ "VFrameFormat" BO_ 769 14;
BA_ "GenMsgSendType" BO_ 770 1;
BA_ "VFrameFormat" BO_ 770 14;
BA_ "GenMsgSendType" BO_ 771 1;
BA_ "GenMsgCycleTime" BO_ 772 500;
BA_ "GenMsgSendType" BO_ 928 1;
BA_ "VFrameFormat" BO_ 928 14;
BA_ "GenMsgSendType" BO_ 929 1;
BA_ "VFrameFormat" BO_ 929 14;
BA_ "GenMsgSendType" BO_ 960 1;
BA_ "VFrameFormat" BO_ 960 14;
BA_ "GenMsgSendType" BO_ 962 1;
BA_ "VFrameFormat" BO_ 962 14;
BA_ "GenMsgSendType" BO_ 963 1;
BA_ "VFrameFormat" BO_ 963 14;
BA_ "GenMsgSendType" BO_ 964 1;
BA_ "VFrameFormat" BO_ 964 14;
BA_ "GenMsgSendType" BO_ 961 1;
BA_ "VFrameFormat" BO_ 961 14;
BA_ "GenMsgSendType" BO_ 965 1;
BA_ "VFrameFormat" BO_ 965 14;
BA_ "GenMsgSendType" BO_ 773 1;
BA_ "GenSigSendType" SG_ 672 PAS_Device_Vertify_Times 1;
BA_ "GenSigSendType" SG_ 672 PAS_Device_Vertify_Status 1;
BA_ "GenSigSendType" SG_ 673 PAS_RandomByte1 1;
BA_ "GenSigSendType" SG_ 673 PAS_RandomByte2 1;
BA_ "GenSigSendType" SG_ 673 PAS_RandomByte3 1;
BA_ "GenSigSendType" SG_ 673 PAS_RandomByte4 1;
BA_ "GenSigSendType" SG_ 673 PAS_RandomByte5 1;
BA_ "GenSigSendType" SG_ 673 PAS_RandomByte6 1;
BA_ "GenSigSendType" SG_ 673 PAS_RandomByte7 1;
BA_ "GenSigSendType" SG_ 673 PAS_RandomByte8 1;
BA_ "GenSigSendType" SG_ 673 PAS_SessionID 1;
BA_ "GenSigSendType" SG_ 674 PAS_Verification_Result 1;
BA_ "GenSigSendType" SG_ 674 PAS_SessionID 1;
BA_ "GenSigSendType" SG_ 674 PAS_CMACByte1 1;
BA_ "GenSigSendType" SG_ 674 PAS_CMACByte2 1;
BA_ "GenSigSendType" SG_ 674 PAS_CMACByte3 1;
BA_ "GenSigSendType" SG_ 674 PAS_CMACByte4 1;
BA_ "GenSigSendType" SG_ 674 PAS_CMACByte5 1;
BA_ "GenSigSendType" SG_ 674 PAS_CMACByte6 1;
BA_ "GenSigSendType" SG_ 674 PAS_CMACByte7 1;
BA_ "GenSigSendType" SG_ 674 PAS_CMACByte8 1;
BA_ "GenSigSendType" SG_ 706 PAS_Key_Learn_SubID 1;
BA_ "GenSigSendType" SG_ 706 PAS_Key_Learn_Numbers 1;
BA_ "GenSigStartValue" SG_ 706 PAS_Key_Learn_Numbers 1;
BA_ "GenSigSendType" SG_ 706 PAS_SKID1 1;
BA_ "GenSigStartValue" SG_ 706 PAS_SKID1 1;
BA_ "GenSigSendType" SG_ 706 PAS_SK_Learn_Status1 1;
BA_ "GenSigSendType" SG_ 706 PAS_SKID2 1;
BA_ "GenSigStartValue" SG_ 706 PAS_SKID2 1;
BA_ "GenSigSendType" SG_ 706 PAS_SK_Learn_Status2 1;
BA_ "GenSigSendType" SG_ 706 PAS_SKID3 1;
BA_ "GenSigStartValue" SG_ 706 PAS_SKID3 1;
BA_ "GenSigSendType" SG_ 706 PAS_SK_Learn_Status3 1;
BA_ "GenSigSendType" SG_ 706 PAS_SKID4 1;
BA_ "GenSigStartValue" SG_ 706 PAS_SKID4 1;
BA_ "GenSigSendType" SG_ 706 PAS_SK_Learn_Status4 1;
BA_ "GenSigSendType" SG_ 706 PAS_SKID5 1;
BA_ "GenSigStartValue" SG_ 706 PAS_SKID5 1;
BA_ "GenSigSendType" SG_ 706 PAS_SK_Learn_Status5 1;
BA_ "GenSigSendType" SG_ 706 PAS_SKID6 1;
BA_ "GenSigStartValue" SG_ 706 PAS_SKID6 1;
BA_ "GenSigSendType" SG_ 706 PAS_SK_Learn_Status6 1;
BA_ "GenSigSendType" SG_ 706 PAS_SKID7 1;
BA_ "GenSigStartValue" SG_ 706 PAS_SKID7 1;
BA_ "GenSigSendType" SG_ 706 PAS_SK_Learn_Status7 1;
BA_ "GenSigSendType" SG_ 706 PAS_SKID8 1;
BA_ "GenSigStartValue" SG_ 706 PAS_SKID8 1;
BA_ "GenSigSendType" SG_ 706 PAS_SK_Learn_Status8 1;
BA_ "GenSigSendType" SG_ 706 PAS_SKID9 1;
BA_ "GenSigStartValue" SG_ 706 PAS_SKID9 1;
BA_ "GenSigSendType" SG_ 706 PAS_SK_Learn_Status9 1;
BA_ "GenSigSendType" SG_ 706 PAS_SKID10 1;
BA_ "GenSigStartValue" SG_ 706 PAS_SKID10 1;
BA_ "GenSigSendType" SG_ 706 PAS_SK_Learn_Status10 1;
BA_ "GenSigSendType" SG_ 706 PAS_SKID11 1;
BA_ "GenSigStartValue" SG_ 706 PAS_SKID11 1;
BA_ "GenSigSendType" SG_ 706 PAS_SK_Learn_Status11 1;
BA_ "GenSigSendType" SG_ 706 PAS_SKID12 1;
BA_ "GenSigStartValue" SG_ 706 PAS_SKID12 1;
BA_ "GenSigSendType" SG_ 706 PAS_SK_Learn_Status12 1;
BA_ "GenSigSendType" SG_ 708 PASKeyLearnSubIDSettingResponse 1;
BA_ "GenSigSendType" SG_ 708 PAS_SK_Setting_Response 1;
BA_ "GenSigStartValue" SG_ 708 PAS_SK_Setting_Response 1;
BA_ "GenSigSendType" SG_ 708 PAS_SK_Setting_Status 1;
BA_ "GenSigSendType" SG_ 707 PAS_VerifySubID 1;
BA_ "GenSigSendType" SG_ 707 PAS_Verify_SKID 1;
BA_ "GenSigStartValue" SG_ 707 PAS_Verify_SKID 1;
BA_ "GenSigSendType" SG_ 707 PAS_Verify_AES_Result 1;
BA_ "GenSigSendType" SG_ 707 PAS_Verify_MACbyte1 1;
BA_ "GenSigSendType" SG_ 707 PAS_Verify_MACbyte2 1;
BA_ "GenSigSendType" SG_ 707 PAS_Verify_MACbyte3 1;
BA_ "GenSigSendType" SG_ 707 PAS_Verify_MACbyte4 1;
BA_ "GenSigSendType" SG_ 707 PAS_Verify_MACbyte5 1;
BA_ "GenSigSendType" SG_ 707 PAS_Verify_MACbyte6 1;
BA_ "GenSigSendType" SG_ 707 PAS_Verify_MACbyte7 1;
BA_ "GenSigSendType" SG_ 707 PAS_Verify_MACbyte8 1;
BA_ "GenSigSendType" SG_ 707 PAS_Verify_MACbyte9 1;
BA_ "GenSigSendType" SG_ 707 PAS_Verify_MACbyte10 1;
BA_ "GenSigSendType" SG_ 707 PAS_Verify_MACbyte11 1;
BA_ "GenSigSendType" SG_ 707 PAS_Verify_MACbyte12 1;
BA_ "GenSigSendType" SG_ 707 PAS_Verify_MACbyte13 1;
BA_ "GenSigSendType" SG_ 707 PAS_Verify_MACbyte14 1;
BA_ "GenSigSendType" SG_ 707 PAS_Verify_MACbyte15 1;
BA_ "GenSigSendType" SG_ 707 PAS_Verify_MACbyte16 1;
BA_ "GenSigSendType" SG_ 707 PAS_Verify_IVByte1 1;
BA_ "GenSigSendType" SG_ 707 PAS_Verify_IVByte2 1;
BA_ "GenSigSendType" SG_ 707 PAS_Verify_IVByte3 1;
BA_ "GenSigSendType" SG_ 707 PAS_Verify_IVByte4 1;
BA_ "GenSigSendType" SG_ 707 PAS_Verify_IVByte5 1;
BA_ "GenSigSendType" SG_ 707 PAS_Verify_IVByte6 1;
BA_ "GenSigSendType" SG_ 707 PAS_Verify_IVByte7 1;
BA_ "GenSigSendType" SG_ 707 PAS_Verify_IVByte8 1;
BA_ "GenSigSendType" SG_ 707 PAS_Verify_IVByte9 1;
BA_ "GenSigSendType" SG_ 707 PAS_Verify_IVByte10 1;
BA_ "GenSigSendType" SG_ 707 PAS_Verify_IVByte11 1;
BA_ "GenSigSendType" SG_ 707 PAS_Verify_IVByte12 1;
BA_ "GenSigSendType" SG_ 770 PAS_Sonar1_Req 1;
BA_ "GenSigSendType" SG_ 770 PAS_Sonar1_Req_counter 1;
BA_ "GenSigSendType" SG_ 770 PAS_Sonar2_Req 1;
BA_ "GenSigSendType" SG_ 770 PAS_Sonar2_Req_counter 1;
BA_ "GenSigSendType" SG_ 770 PAS_Sonar3_Req 1;
BA_ "GenSigSendType" SG_ 770 PAS_Sonar3_Req_counter 1;
BA_ "GenSigSendType" SG_ 770 PAS_Sonar4_Req 1;
BA_ "GenSigSendType" SG_ 770 PAS_Sonar4_Req_counter 1;
BA_ "GenSigSendType" SG_ 770 PAS_Sonar7_Req 1;
BA_ "GenSigSendType" SG_ 770 PAS_Sonar7_Req_counter 1;
BA_ "GenSigSendType" SG_ 770 PAS_Sonar8_Req 1;
BA_ "GenSigSendType" SG_ 770 PAS_Sonar8_Req_counter 1;
BA_ "GenSigSendType" SG_ 770 PAS_Sonar9_Req 1;
BA_ "GenSigSendType" SG_ 770 PAS_Sonar9_Req_counter 1;
BA_ "GenSigSendType" SG_ 770 PAS_Sonar10_Req 1;
BA_ "GenSigSendType" SG_ 770 PAS_Sonar10_Req_counter 1;
BA_ "GenSigSendType" SG_ 770 PAS_Sonar0_Req 1;
BA_ "GenSigSendType" SG_ 770 PAS_Sonar0_Req_counter 1;
BA_ "GenSigSendType" SG_ 770 PAS_Sonar5_Req 1;
BA_ "GenSigSendType" SG_ 770 PAS_Sonar5_Req_counter 1;
BA_ "GenSigSendType" SG_ 770 PAS_Sonar6_Req 1;
BA_ "GenSigSendType" SG_ 770 PAS_Sonar6_Req_counter 1;
BA_ "GenSigSendType" SG_ 770 PAS_Sonar11_Req 1;
BA_ "GenSigSendType" SG_ 770 PAS_Sonar11_Req_counter 1;
BA_ "GenSigSendType" SG_ 770 Sonar_Req_RollingCounter 1;
BA_ "GenSigSendType" SG_ 770 Sonar_Req_Checksum 1;
BA_ "GenSigSendType" SG_ 770 Fill4bit 1;
BA_ "GenSigSendType" SG_ 770 PAS_Function_Req 1;
BA_ "GenSigSendType" SG_ 771 Ack_Alarm_Id 1;
BA_ "GenSigSendType" SG_ 771 Ack_Alarm_State 1;
BA_ "GenSigSendType" SG_ 771 Ack_Alarm_Level 1;
BA_ "GenSigSendType" SG_ 771 Ack_Transaction_Id 1;
BA_ "GenSigSendType" SG_ 771 Ack_Alarm_Checksum 1;
BA_ "GenSigSendType" SG_ 771 Ack_Alarm_RollingCounter 1;
BA_ "GenSigSendType" SG_ 771 Fill4bit 1;
BA_ "GenSigSendType" SG_ 928 MDC_RandomByte1 1;
BA_ "GenSigSendType" SG_ 928 MDC_RandomByte2 1;
BA_ "GenSigSendType" SG_ 928 MDC_RandomByte3 1;
BA_ "GenSigSendType" SG_ 928 MDC_RandomByte4 1;
BA_ "GenSigSendType" SG_ 928 MDC_RandomByte5 1;
BA_ "GenSigSendType" SG_ 928 MDC_RandomByte6 1;
BA_ "GenSigSendType" SG_ 928 MDC_RandomByte7 1;
BA_ "GenSigSendType" SG_ 928 MDC_RandomByte8 1;
BA_ "GenSigSendType" SG_ 928 MDC_SessionID 1;
BA_ "GenSigSendType" SG_ 929 MDC_Response_Result 1;
BA_ "GenSigSendType" SG_ 929 MDC_Response_SessionID 1;
BA_ "GenSigSendType" SG_ 929 MDC_Response_CMACByte1 1;
BA_ "GenSigSendType" SG_ 929 MDC_Response_CMACByte2 1;
BA_ "GenSigSendType" SG_ 929 MDC_Response_CMACByte3 1;
BA_ "GenSigSendType" SG_ 929 MDC_Response_CMACByte4 1;
BA_ "GenSigSendType" SG_ 929 MDC_Response_CMACByte5 1;
BA_ "GenSigSendType" SG_ 929 MDC_Response_CMACByte6 1;
BA_ "GenSigSendType" SG_ 929 MDC_Response_CMACByte7 1;
BA_ "GenSigSendType" SG_ 929 MDC_Response_CMACByte8 1;
BA_ "GenSigSendType" SG_ 960 Mdc_KeyLearnSubID 1;
BA_ "GenSigSendType" SG_ 960 Mdc_KeyLearn_Numbers 1;
BA_ "GenSigStartValue" SG_ 960 Mdc_KeyLearn_Numbers 1;
BA_ "GenSigSendType" SG_ 960 Mdc_KeyLearn_SKID1 1;
BA_ "GenSigStartValue" SG_ 960 Mdc_KeyLearn_SKID1 1;
BA_ "GenSigSendType" SG_ 960 Mdc_KeyLearn_SKID2 1;
BA_ "GenSigStartValue" SG_ 960 Mdc_KeyLearn_SKID2 1;
BA_ "GenSigSendType" SG_ 960 Mdc_KeyLearn_SKID3 1;
BA_ "GenSigStartValue" SG_ 960 Mdc_KeyLearn_SKID3 1;
BA_ "GenSigSendType" SG_ 960 Mdc_KeyLearn_SKID4 1;
BA_ "GenSigStartValue" SG_ 960 Mdc_KeyLearn_SKID4 1;
BA_ "GenSigSendType" SG_ 960 Mdc_KeyLearn_SKID5 1;
BA_ "GenSigStartValue" SG_ 960 Mdc_KeyLearn_SKID5 1;
BA_ "GenSigSendType" SG_ 960 Mdc_KeyLearn_SKID6 1;
BA_ "GenSigStartValue" SG_ 960 Mdc_KeyLearn_SKID6 1;
BA_ "GenSigSendType" SG_ 960 Mdc_KeyLearn_SKID7 1;
BA_ "GenSigStartValue" SG_ 960 Mdc_KeyLearn_SKID7 1;
BA_ "GenSigSendType" SG_ 960 Mdc_KeyLearn_SKID8 1;
BA_ "GenSigStartValue" SG_ 960 Mdc_KeyLearn_SKID8 1;
BA_ "GenSigSendType" SG_ 960 Mdc_KeyLearn_SKID9 1;
BA_ "GenSigStartValue" SG_ 960 Mdc_KeyLearn_SKID9 1;
BA_ "GenSigSendType" SG_ 960 Mdc_KeyLearn_SKID10 1;
BA_ "GenSigStartValue" SG_ 960 Mdc_KeyLearn_SKID10 1;
BA_ "GenSigSendType" SG_ 960 Mdc_KeyLearn_SKID11 1;
BA_ "GenSigStartValue" SG_ 960 Mdc_KeyLearn_SKID11 1;
BA_ "GenSigSendType" SG_ 960 Mdc_KeyLearn_SKID12 1;
BA_ "GenSigStartValue" SG_ 960 Mdc_KeyLearn_SKID12 1;
BA_ "GenSigSendType" SG_ 962 Mdc_KeyLearnSubID_Send 1;
BA_ "GenSigSendType" SG_ 962 Mdc_KeyLearn_transmit_SKID 1;
BA_ "GenSigStartValue" SG_ 962 Mdc_KeyLearn_transmit_SKID 1;
BA_ "GenSigSendType" SG_ 962 Mdc_KeyLearn_update_SKID 1;
BA_ "GenSigStartValue" SG_ 962 Mdc_KeyLearn_update_SKID 1;
BA_ "GenSigSendType" SG_ 962 Mdc_KeyLearn_SKCByte1 1;
BA_ "GenSigSendType" SG_ 962 Mdc_KeyLearn_SKCByte2 1;
BA_ "GenSigSendType" SG_ 962 Mdc_KeyLearn_SKCByte3 1;
BA_ "GenSigSendType" SG_ 962 Mdc_KeyLearn_SKCByte4 1;
BA_ "GenSigSendType" SG_ 962 Mdc_KeyLearn_SKCByte5 1;
BA_ "GenSigSendType" SG_ 962 Mdc_KeyLearn_SKCByte6 1;
BA_ "GenSigSendType" SG_ 962 Mdc_KeyLearn_SKCByte7 1;
BA_ "GenSigSendType" SG_ 962 Mdc_KeyLearn_SKCByte8 1;
BA_ "GenSigSendType" SG_ 962 Mdc_KeyLearn_SKCByte9 1;
BA_ "GenSigSendType" SG_ 962 Mdc_KeyLearn_SKCByte10 1;
BA_ "GenSigSendType" SG_ 962 Mdc_KeyLearn_SKCByte11 1;
BA_ "GenSigSendType" SG_ 962 Mdc_KeyLearn_SKCByte12 1;
BA_ "GenSigSendType" SG_ 962 Mdc_KeyLearn_SKCByte13 1;
BA_ "GenSigSendType" SG_ 962 Mdc_KeyLearn_SKCByte14 1;
BA_ "GenSigSendType" SG_ 962 Mdc_KeyLearn_SKCByte15 1;
BA_ "GenSigSendType" SG_ 962 Mdc_KeyLearn_SKCByte16 1;
BA_ "GenSigSendType" SG_ 962 Mdc_KeyLearn_MACByte1 1;
BA_ "GenSigSendType" SG_ 962 Mdc_KeyLearn_MACByte2 1;
BA_ "GenSigSendType" SG_ 962 Mdc_KeyLearn_MACByte3 1;
BA_ "GenSigSendType" SG_ 962 Mdc_KeyLearn_MACByte4 1;
BA_ "GenSigSendType" SG_ 962 Mdc_KeyLearn_MACByte5 1;
BA_ "GenSigSendType" SG_ 962 Mdc_KeyLearn_MACByte6 1;
BA_ "GenSigSendType" SG_ 962 Mdc_KeyLearn_MACByte7 1;
BA_ "GenSigSendType" SG_ 962 Mdc_KeyLearn_MACByte8 1;
BA_ "GenSigSendType" SG_ 962 Mdc_KeyLearn_MACByte9 1;
BA_ "GenSigSendType" SG_ 962 Mdc_KeyLearn_MACByte10 1;
BA_ "GenSigSendType" SG_ 962 Mdc_KeyLearn_MACByte11 1;
BA_ "GenSigSendType" SG_ 962 Mdc_KeyLearn_MACByte12 1;
BA_ "GenSigSendType" SG_ 962 Mdc_KeyLearn_MACByte13 1;
BA_ "GenSigSendType" SG_ 962 Mdc_KeyLearn_MACByte14 1;
BA_ "GenSigSendType" SG_ 962 Mdc_KeyLearn_MACByte15 1;
BA_ "GenSigSendType" SG_ 962 Mdc_KeyLearn_MACByte16 1;
BA_ "GenSigSendType" SG_ 962 Mdc_KeyLearn_IVByte1 1;
BA_ "GenSigSendType" SG_ 962 Mdc_KeyLearn_IVByte2 1;
BA_ "GenSigSendType" SG_ 962 Mdc_KeyLearn_IVByte3 1;
BA_ "GenSigSendType" SG_ 962 Mdc_KeyLearn_IVByte4 1;
BA_ "GenSigSendType" SG_ 962 Mdc_KeyLearn_IVByte5 1;
BA_ "GenSigSendType" SG_ 962 Mdc_KeyLearn_IVByte6 1;
BA_ "GenSigSendType" SG_ 962 Mdc_KeyLearn_IVByte7 1;
BA_ "GenSigSendType" SG_ 962 Mdc_KeyLearn_IVByte8 1;
BA_ "GenSigSendType" SG_ 962 Mdc_KeyLearn_IVByte9 1;
BA_ "GenSigSendType" SG_ 962 Mdc_KeyLearn_IVByte10 1;
BA_ "GenSigSendType" SG_ 962 Mdc_KeyLearn_IVByte11 1;
BA_ "GenSigSendType" SG_ 962 Mdc_KeyLearn_IVByte12 1;
BA_ "GenSigSendType" SG_ 962 Mdc_KeyLearn_SC 1;
BA_ "GenSigSendType" SG_ 963 Mdc_KeyLearnSubID_SKSetting 1;
BA_ "GenSigSendType" SG_ 963 Mdc_KeyLearn_SKID 1;
BA_ "GenSigStartValue" SG_ 963 Mdc_KeyLearn_SKID 1;
BA_ "GenSigSendType" SG_ 964 Mdc_KeyLearnSubID_CleanID 1;
BA_ "GenSigSendType" SG_ 964 Mdc_KeyLearn_Clean_SKID 1;
BA_ "GenSigStartValue" SG_ 964 Mdc_KeyLearn_Clean_SKID 1;
BA_ "GenSigSendType" SG_ 964 Mdc_KeyLearn_Clean_SCByte1 1;
BA_ "GenSigSendType" SG_ 964 Mdc_KeyLearn_Clean_SCByte2 1;
BA_ "GenSigSendType" SG_ 964 Mdc_KeyLearn_Clean_SCByte3 1;
BA_ "GenSigSendType" SG_ 964 Mdc_KeyLearn_Clean_SCByte4 1;
BA_ "GenSigSendType" SG_ 964 Mdc_KeyLearn_Clean_SCByte5 1;
BA_ "GenSigSendType" SG_ 964 Mdc_KeyLearn_Clean_SCByte6 1;
BA_ "GenSigSendType" SG_ 964 Mdc_KeyLearn_Clean_SCByte7 1;
BA_ "GenSigSendType" SG_ 964 Mdc_KeyLearn_Clean_SCByte8 1;
BA_ "GenSigSendType" SG_ 964 Mdc_KeyLearn_Clean_SCByte9 1;
BA_ "GenSigSendType" SG_ 964 Mdc_KeyLearn_Clean_SCByte10 1;
BA_ "GenSigSendType" SG_ 964 Mdc_KeyLearn_Clean_SCByte11 1;
BA_ "GenSigSendType" SG_ 964 Mdc_KeyLearn_Clean_SCByte12 1;
BA_ "GenSigSendType" SG_ 964 Mdc_KeyLearn_Clean_SCByte13 1;
BA_ "GenSigSendType" SG_ 964 Mdc_KeyLearn_Clean_SCByte14 1;
BA_ "GenSigSendType" SG_ 964 Mdc_KeyLearn_Clean_SCByte15 1;
BA_ "GenSigSendType" SG_ 964 Mdc_KeyLearn_Clean_SCByte16 1;
BA_ "GenSigSendType" SG_ 964 Mdc_KeyLearn_Clean_MACByte1 1;
BA_ "GenSigSendType" SG_ 964 Mdc_KeyLearn_Clean_MACByte2 1;
BA_ "GenSigSendType" SG_ 964 Mdc_KeyLearn_Clean_MACByte3 1;
BA_ "GenSigSendType" SG_ 964 Mdc_KeyLearn_Clean_MACByte4 1;
BA_ "GenSigSendType" SG_ 964 Mdc_KeyLearn_Clean_MACByte5 1;
BA_ "GenSigSendType" SG_ 964 Mdc_KeyLearn_Clean_MACByte6 1;
BA_ "GenSigSendType" SG_ 964 Mdc_KeyLearn_Clean_MACByte7 1;
BA_ "GenSigSendType" SG_ 964 Mdc_KeyLearn_Clean_MACByte8 1;
BA_ "GenSigSendType" SG_ 964 Mdc_KeyLearn_Clean_MACByte9 1;
BA_ "GenSigSendType" SG_ 964 Mdc_KeyLearn_Clean_MACByte10 1;
BA_ "GenSigSendType" SG_ 964 Mdc_KeyLearn_Clean_MACByte11 1;
BA_ "GenSigSendType" SG_ 964 Mdc_KeyLearn_Clean_MACByte12 1;
BA_ "GenSigSendType" SG_ 964 Mdc_KeyLearn_Clean_MACByte13 1;
BA_ "GenSigSendType" SG_ 964 Mdc_KeyLearn_Clean_MACByte14 1;
BA_ "GenSigSendType" SG_ 964 Mdc_KeyLearn_Clean_MACByte15 1;
BA_ "GenSigSendType" SG_ 964 Mdc_KeyLearn_Clean_MACByte16 1;
BA_ "GenSigSendType" SG_ 964 Mdc_KeyLearn_Clean_IVByte1 1;
BA_ "GenSigSendType" SG_ 964 Mdc_KeyLearn_Clean_IVByte2 1;
BA_ "GenSigSendType" SG_ 964 Mdc_KeyLearn_Clean_IVByte3 1;
BA_ "GenSigSendType" SG_ 964 Mdc_KeyLearn_Clean_IVByte4 1;
BA_ "GenSigSendType" SG_ 964 Mdc_KeyLearn_Clean_IVByte5 1;
BA_ "GenSigSendType" SG_ 964 Mdc_KeyLearn_Clean_IVByte6 1;
BA_ "GenSigSendType" SG_ 964 Mdc_KeyLearn_Clean_IVByte7 1;
BA_ "GenSigSendType" SG_ 964 Mdc_KeyLearn_Clean_IVByte8 1;
BA_ "GenSigSendType" SG_ 964 Mdc_KeyLearn_Clean_IVByte9 1;
BA_ "GenSigSendType" SG_ 964 Mdc_KeyLearn_Clean_IVByte10 1;
BA_ "GenSigSendType" SG_ 964 Mdc_KeyLearn_Clean_IVByte11 1;
BA_ "GenSigSendType" SG_ 964 Mdc_KeyLearn_Clean_IVByte12 1;
BA_ "GenSigSendType" SG_ 961 Mdc_VerifySubID_Random 1;
BA_ "GenSigSendType" SG_ 961 Mdc_Verify_SKID 1;
BA_ "GenSigStartValue" SG_ 961 Mdc_Verify_SKID 1;
BA_ "GenSigSendType" SG_ 961 Mdc_Verify_Random 1;
BA_ "GenSigSendType" SG_ 965 Mdc_Verify_ResultID 1;
BA_ "GenSigSendType" SG_ 965 Mdc_Verify_Result_SKID 1;
BA_ "GenSigStartValue" SG_ 965 Mdc_Verify_Result_SKID 1;
BA_ "GenSigSendType" SG_ 965 Mdc_Verify_Result_Status 1;
VAL_ 517 PAS_Sonar6_Emit 0 "off" 1 "receive only" 2 "emit and receive" ;
VAL_ 517 PAS_Sonar7_Emit 0 "off" 1 "receive only" 2 "emit and receive" ;
VAL_ 517 PAS_Sonar8_Emit 0 "off" 1 "receive only" 2 "emit and receive" ;
VAL_ 517 PAS_Sonar9_Emit 0 "off" 1 "receive only" 2 "emit and receive" ;
VAL_ 517 PAS_Sonar10_Emit 0 "off" 1 "receive only" 2 "emit and receive" ;
VAL_ 517 PAS_Sonar11_Emit 0 "off" 1 "receive only" 2 "emit and receive" ;
VAL_ 517 PASSonarInfoRearRollingCounter 15 "Invalid" ;
VAL_ 517 Fill4bit 15 "填充位" ;
VAL_ 544 PAS_WakeUp_Response 0 "未收到唤醒报文" 1 "收到唤醒报文" ;
VAL_ 544 PAS_SonarMode_Response 0 "未收探头工作模式指令报文" 1 "收到工作模式指令报文" ;
VAL_ 544 PAS_Response_RollingCounter 15 "Invalid" ;
VAL_ 544 Fill4bit 15 "填充位" ;
VAL_ 560 PAS_SensorStsLR_FLS 0 "normal    0x1:Fail" ;
VAL_ 560 PAS_SensorStsLR_FRS 0 "normal    0x1:Fail" ;
VAL_ 560 PAS_SensorStsSR_FL 0 "normal    0x1:Fail" ;
VAL_ 560 PAS_SensorStsSR_FML 0 "normal    0x1:Fail" ;
VAL_ 560 PAS_SensorStsSR_FMR 0 "normal    0x1:Fail" ;
VAL_ 560 PAS_SensorStsSR_FR 0 "normal    0x1:Fail" ;
VAL_ 560 PAS_SensorStsLR_RLS 0 "normal    0x1:Fail" ;
VAL_ 560 PAS_SensorStsLR_RRS 0 "normal    0x1:Fail" ;
VAL_ 560 PAS_SensorStsSR_RL 0 "normal    0x1:Fail" ;
VAL_ 560 PAS_SensorStsSR_RML 0 "normal    0x1:Fail" ;
VAL_ 560 PAS_SensorStsSR_RMR 0 "normal    0x1:Fail" ;
VAL_ 560 PAS_SensorStsSR_RR 0 "normal    0x1:Fail" ;
VAL_ 560 PAS_ECU_Status 0 "normal    0x1:Fail" ;
VAL_ 560 PAS_ECU_VehStatus_Reponse 0 "接收到车辆状态信息" 1 " 未接收到车辆状态信息" ;
VAL_ 560 sensorVersion_Status 0 "未收到版本信息（沿用上次配置）" 1 "收到传感器版本信息" ;
VAL_ 560 PAS_SensorStatus_RollingCounter 15 "Invalid" ;
VAL_ 560 Fill4bit 15 "填充位" ;
VAL_ 576 PAS_ECUInfo_RollingCounter 15 "Invalid" ;
VAL_ 576 Fill4bit 15 "填充位" ;
VAL_ 592 Rpt_Alarm_State 0 "告警恢复" 1 " 告警产生" ;
VAL_ 592 Rpt_Alarm_Level 0 "提示" 1 "一般" 2 " 严重" ;
VAL_ 592 Rpt_Alarm_RollingCounter 15 "Invalid" ;
VAL_ 592 Fill4bit 15 "填充位" ;
VAL_ 593 PAS_Sonar1_ControlBusFailure 0 "探头正常" 1 "探头不正常" ;
VAL_ 593 PAS_Sonar1_RingingTimeFailure 0 "探头正常" 1 "探头不正常" ;
VAL_ 593 PAS_Sonar1_ShortToGND 0 "探头正常" 1 "探头不正常" ;
VAL_ 593 PAS_Sonar1_ShortToPositivePole 0 "探头正常" 1 "探头不正常" ;
VAL_ 593 PAS_Sonar1_TypeMismatch 0 "探头正常" 1 "探头不正常" ;
VAL_ 593 PAS_Sonar2_ControlBusFailure 0 "探头正常" 1 "探头不正常" ;
VAL_ 593 PAS_Sonar2_RingingTimeFailure 0 "探头正常" 1 "探头不正常" ;
VAL_ 593 PAS_Sonar2_ShortToGND 0 "探头正常" 1 "探头不正常" ;
VAL_ 593 PAS_Sonar2_ShortToPositivePole 0 "探头正常" 1 "探头不正常" ;
VAL_ 593 PAS_Sonar2_TypeMismatch 0 "探头正常" 1 "探头不正常" ;
VAL_ 593 PAS_Sonar3_ControlBusFailure 0 "探头正常" 1 "探头不正常" ;
VAL_ 593 PAS_Sonar3_RingingTimeFailure 0 "探头正常" 1 "探头不正常" ;
VAL_ 593 PAS_Sonar3_ShortToGND 0 "探头正常" 1 "探头不正常" ;
VAL_ 593 PAS_Sonar3_ShortToPositivePole 0 "探头正常" 1 "探头不正常" ;
VAL_ 593 PAS_Sonar3_TypeMismatch 0 "探头正常" 1 "探头不正常" ;
VAL_ 593 PAS_Sonar3_PowerVoltage_Low 0 "探头正常" 1 "探头不正常" ;
VAL_ 593 PAS_Sonar3_PowerVoltage_High 0 "探头正常" 1 "探头不正常" ;
VAL_ 593 PAS_Sonar4_ControlBusFailure 0 "探头正常" 1 "探头不正常" ;
VAL_ 593 PAS_Sonar4_RingingTimeFailure 0 "探头正常" 1 "探头不正常" ;
VAL_ 593 PAS_Sonar4_ShortToGND 0 "探头正常" 1 "探头不正常" ;
VAL_ 593 PAS_Sonar4_ShortToPositivePole 0 "探头正常" 1 "探头不正常" ;
VAL_ 593 PAS_Sonar4_TypeMismatch 0 "探头正常" 1 "探头不正常" ;
VAL_ 593 PAS_Sonar7_ControlBusFailure 0 "探头正常" 1 "探头不正常" ;
VAL_ 593 PAS_Sonar7_RingingTimeFailure 0 "探头正常" 1 "探头不正常" ;
VAL_ 593 PAS_Sonar7_ShortToGND 0 "探头正常" 1 "探头不正常" ;
VAL_ 593 PAS_Sonar7_ShortToPositivePole 0 "探头正常" 1 "探头不正常" ;
VAL_ 593 PAS_Sonar7_TypeMismatch 0 "探头正常" 1 "探头不正常" ;
VAL_ 593 PAS_Sonar8_ControlBusFailure 0 "探头正常" 1 "探头不正常" ;
VAL_ 593 PAS_Sonar8_RingingTimeFailure 0 "探头正常" 1 "探头不正常" ;
VAL_ 593 PAS_Sonar8_ShortToGND 0 "探头正常" 1 "探头不正常" ;
VAL_ 593 PAS_Sonar8_ShortToPositivePole 0 "探头正常" 1 "探头不正常" ;
VAL_ 593 PAS_Sonar8_TypeMismatch 0 "探头正常" 1 "探头不正常" ;
VAL_ 593 PAS_Sonar9_ControlBusFailure 0 "探头正常" 1 "探头不正常" ;
VAL_ 593 PAS_Sonar9_RingingTimeFailure 0 "探头正常" 1 "探头不正常" ;
VAL_ 593 PAS_Sonar9_ShortToGND 0 "探头正常" 1 "探头不正常" ;
VAL_ 593 PAS_Sonar9_ShortToPositivePole 0 "探头正常" 1 "探头不正常" ;
VAL_ 593 PAS_Sonar9_TypeMismatch 0 "探头正常" 1 "探头不正常" ;
VAL_ 593 PAS_Sonar10_ControlBusFailure 0 "探头正常" 1 "探头不正常" ;
VAL_ 593 PAS_Sonar10_RingingTimeFailure 0 "探头正常" 1 "探头不正常" ;
VAL_ 593 PAS_Sonar10_ShortToGND 0 "探头正常" 1 "探头不正常" ;
VAL_ 593 PAS_Sonar10_ShortToPositivePole 0 "探头正常" 1 "探头不正常" ;
VAL_ 593 PAS_Sonar10_TypeMismatch 0 "探头正常" 1 "探头不正常" ;
VAL_ 593 PAS_Sonar0_ControlBusFailure 0 "探头正常" 1 "探头不正常" ;
VAL_ 593 PAS_Sonar0_RingingTimeFailure 0 "探头正常" 1 "探头不正常" ;
VAL_ 593 PAS_Sonar0_ShortToGND 0 "探头正常" 1 "探头不正常" ;
VAL_ 593 PAS_Sonar0_ShortToPositivePole 0 "探头正常" 1 "探头不正常" ;
VAL_ 593 PAS_Sonar0_TypeMismatch 0 "探头正常" 1 "探头不正常" ;
VAL_ 593 PAS_Sonar5_ControlBusFailure 0 "探头正常" 1 "探头不正常" ;
VAL_ 593 PAS_Sonar5_RingingTimeFailure 0 "探头正常" 1 "探头不正常" ;
VAL_ 593 PAS_Sonar5_ShortToGND 0 "探头正常" 1 "探头不正常" ;
VAL_ 593 PAS_Sonar5_ShortToPositivePole 0 "探头正常" 1 "探头不正常" ;
VAL_ 593 PAS_Sonar5_TypeMismatch 0 "探头正常" 1 "探头不正常" ;
VAL_ 593 PAS_Sonar6_ControlBusFailure 0 "探头正常" 1 "探头不正常" ;
VAL_ 593 PAS_Sonar6_RingingTimeFailure 0 "探头正常" 1 "探头不正常" ;
VAL_ 593 PAS_Sonar6_ShortToGND 0 "探头正常" 1 "探头不正常" ;
VAL_ 593 PAS_Sonar6_ShortToPositivePole 0 "探头正常" 1 "探头不正常" ;
VAL_ 593 PAS_Sonar6_TypeMismatch 0 "探头正常" 1 "探头不正常" ;
VAL_ 593 PAS_Sonar11_ControlBusFailure 0 "探头正常" 1 "探头不正常" ;
VAL_ 593 PAS_Sonar11_RingingTimeFailure 0 "探头正常" 1 "探头不正常" ;
VAL_ 593 PAS_Sonar11_ShortToGND 0 "探头正常" 1 "探头不正常" ;
VAL_ 593 PAS_Sonar11_ShortToPositivePole 0 "探头正常" 1 "探头不正常" ;
VAL_ 593 PAS_Sonar11_TypeMismatch 0 "探头正常" 1 "探头不正常" ;
VAL_ 593 PAS_ECU_OverVoltage 0 "normal" 1 "Fail" ;
VAL_ 593 PAS_ECU_UnderVoltage 0 "normal" 1 "Fail" ;
VAL_ 593 PAS_ECU_BusOff_ERROR 0 "No CAN Busoff error" 1 " CAN Busoff error" ;
VAL_ 593 PAS_MDC_COMMU_ERROR 0 "normal" 1 "Fail" ;
VAL_ 593 PAS_ECU_EEPROM_ERROR 0 "normal" 1 "Fail" ;
VAL_ 593 PAS_DiagnosisInfo_RollingCounter 15 "Invalid" ;
VAL_ 593 Fill4bit 15 "填充位" ;
VAL_ 593 PAS_MDCSIGNAL_ERROR 0 "normal" 1 "MDC发出无效信号" ;
VAL_ 593 PAS_ECU_INTERNAL_ERROR 0 "normal" 1 "USS ECU内部故障" ;
VAL_ 593 PAS_TIMESYNC_ERROR 0 "normal" 1 "时间同步异常" ;
VAL_ 593 PAS_KEYLEARN_ERROR 0 "normal" 1 "密钥学习异常" ;
VAL_ 593 PAS_AUTHEN_ERROR 0 "normal" 1 "设备认证异常" ;
VAL_ 593 PAS_Sonar0_Internal_failure 0 "normal" 1 "Fail" ;
VAL_ 593 PAS_Sonar1_Internal_failure 0 "normal" 1 "Fail" ;
VAL_ 593 PAS_Sonar2_Internal_failure 0 "normal" 1 "Fail" ;
VAL_ 593 PAS_Sonar3_Internal_failure 0 "normal" 1 "Fail" ;
VAL_ 593 PAS_Sonar4_Internal_failure 0 "normal" 1 "Fail" ;
VAL_ 593 PAS_Sonar5_Internal_failure 0 "normal" 1 "Fail" ;
VAL_ 593 PAS_Sonar6_Internal_failure 0 "normal" 1 "Fail" ;
VAL_ 593 PAS_Sonar7_Internal_failure 0 "normal" 1 "Fail" ;
VAL_ 593 PAS_Sonar8_Internal_failure 0 "normal" 1 "Fail" ;
VAL_ 593 PAS_Sonar9_Internal_failure 0 "normal" 1 "Fail" ;
VAL_ 593 PAS_Sonar10_Internal_failure 0 "normal" 1 "Fail" ;
VAL_ 593 PAS_Sonar11_Internal_failure 0 "normal" 1 "Fail" ;
VAL_ 593 USS_Front_ShortToGND 0 "normal" 1 "Fail" ;
VAL_ 593 USS_Front_ShortToUbat 0 "normal" 1 "Fail" ;
VAL_ 593 USS_Rear_ShortToGND 0 "normal" 1 "Fail" ;
VAL_ 593 USS_Rear_ShortToUbat 0 "normal" 1 "Fail" ;
VAL_ 593 VHM_Error 0 "normal" 1 "Fail" ;
VAL_ 593 Sensor_Version_Fail 0 "normal" 1 "Fail" ;
VAL_ 672 PAS_Device_Vertify_Status 0 "未认证" 1 " 已认证" ;
VAL_ 674 PAS_Verification_Result 0 "认证成功" 1 "密钥未学习" 2 "FV校验失败（挑战应答不使用）" 3 "MAC校验失败" 4 "认证报文超时" 5 "未认证" 6 "其他认证错误" ;
VAL_ 706 PAS_SK_Learn_Status1 0 "未学习" 1 "已学习" ;
VAL_ 706 PAS_SK_Learn_Status2 0 "未学习" 1 "已学习" ;
VAL_ 706 PAS_SK_Learn_Status3 0 "未学习" 1 "已学习" ;
VAL_ 706 PAS_SK_Learn_Status4 0 "未学习" 1 "已学习" ;
VAL_ 706 PAS_SK_Learn_Status5 0 "未学习" 1 "已学习" ;
VAL_ 706 PAS_SK_Learn_Status6 0 "未学习" 1 "已学习" ;
VAL_ 706 PAS_SK_Learn_Status7 0 "未学习" 1 "已学习" ;
VAL_ 706 PAS_SK_Learn_Status8 0 "未学习" 1 "已学习" ;
VAL_ 706 PAS_SK_Learn_Status9 0 "未学习" 1 "已学习" ;
VAL_ 706 PAS_SK_Learn_Status10 0 "未学习" 1 "已学习" ;
VAL_ 706 PAS_SK_Learn_Status11 0 "未学习" 1 "已学习" ;
VAL_ 706 PAS_SK_Learn_Status12 0 "未学习" 1 "已学习" ;
VAL_ 708 PAS_SK_Setting_Status 0 "未学习" 1 "已学习" ;
VAL_ 608 UPC_Object1_Type 0 "None" 1 "Point" 2 "Straight0Corner" 3 "Straight1Corner" 4 "Straight2Corner" 5 "Reserved" 7 " Invalid" ;
VAL_ 608 UPC_Object1_ExistProbability 127 " Invalid" ;
VAL_ 608 UPC_Object1_Height 0 "Low" 1 "High" 2 "Traversable" 3 " Unknown" ;
VAL_ 608 UPC_Object1_HeightProbability 2 "TALL" 1 "LOW" ;
VAL_ 608 UPCObject1PositionUpdateTime 4095 " Invalid" ;
VAL_ 608 UPC_Object1_Point1PositionX 2047 " Invalid" ;
VAL_ 608 UPC_Object1_Point1PositionY 2047 " Invalid" ;
VAL_ 608 UPC_Object1_Point2PositionX 2047 " Invalid" ;
VAL_ 608 UPC_Object1_Point2PositionY 2047 " Invalid" ;
VAL_ 608 UPC_Object1_ID 0 " Invalid" ;
VAL_ 608 UPC_Object2_Type 0 "None" 1 "Point" 2 "Straight0Corner" 3 "Straight1Corner" 4 "Straight2Corner" 5 "Reserved" 7 " Invalid" ;
VAL_ 608 UPC_Object2_ExistProbability 127 " Invalid" ;
VAL_ 608 UPC_Object2_Height 0 "Low" 1 "High" 2 "Traversible" 3 " Unknown" ;
VAL_ 608 UPC_Object2_HeightProbability 7 " Invalid" ;
VAL_ 608 UPCObject2PositionUpdateTime 4095 " Invalid" ;
VAL_ 608 UPC_Object2_Point1PositionX 2047 " Invalid" ;
VAL_ 608 UPC_Object2_Point1PositionY 2047 " Invalid" ;
VAL_ 608 UPC_Object2_Point2PositionX 2047 " Invalid" ;
VAL_ 608 UPC_Object2_Point2PositionY 2047 " Invalid" ;
VAL_ 608 UPC_Object2_ID 0 " Invalid" ;
VAL_ 608 UPC_Object3_Type 0 "None" 1 "Point" 2 "Straight0Corner" 3 "Straight1Corner" 4 "Straight2Corner" 5 "Reserved" 7 " Invalid" ;
VAL_ 608 UPC_Object3_ExistProbability 127 " Invalid" ;
VAL_ 608 UPC_Object3_Height 0 "Low" 1 "High" 2 "Traversible" 3 " Unknown" ;
VAL_ 608 UPC_Object3_HeightProbability 7 " Invalid" ;
VAL_ 608 UPCObject3PositionUpdateTime 4095 " Invalid" ;
VAL_ 608 UPC_Object3_Point1PositionX 2047 " Invalid" ;
VAL_ 608 UPC_Object3_Point1PositionY 2047 " Invalid" ;
VAL_ 608 UPC_Object3_Point2PositionX 2047 " Invalid" ;
VAL_ 608 UPC_Object3_Point2PositionY 2047 " Invalid" ;
VAL_ 608 UPC_Object3_ID 0 " Invalid" ;
VAL_ 608 UPC_Object4_Type 0 "None" 1 "Point" 2 "Straight0Corner" 3 "Straight1Corner" 4 "Straight2Corner" 5 "Reserved" 7 " Invalid" ;
VAL_ 608 UPC_Object4_ExistProbability 127 " Invalid" ;
VAL_ 608 UPC_Object4_Height 0 "Low" 1 "High" 2 "Traversible" 3 " Unknown" ;
VAL_ 608 UPC_Object4_HeightProbability 7 " Invalid" ;
VAL_ 608 UPCObject4PositionUpdateTime 4095 " Invalid" ;
VAL_ 608 UPC_Object4_Point1PositionX 2047 " Invalid" ;
VAL_ 608 UPC_Object4_Point1PositionY 2047 " Invalid" ;
VAL_ 608 UPC_Object4_Point2PositionX 2047 " Invalid" ;
VAL_ 608 UPC_Object4_Point2PositionY 2047 " Invalid" ;
VAL_ 608 UPC_Object4_ID 0 " Invalid" ;
VAL_ 608 UPC_Object5_Type 0 "None" 1 "Point" 2 "Straight0Corner" 3 "Straight1Corner" 4 "Straight2Corner" 5 "Reserved" 7 " Invalid" ;
VAL_ 608 UPC_Object5_ExistProbability 127 " Invalid" ;
VAL_ 608 UPC_Object5_Height 0 "Low" 1 "High" 2 "Traversable" 3 " Unknown" ;
VAL_ 608 UPC_Object5_HeightProbability 7 " Invalid" ;
VAL_ 608 UPCObject5PositionUpdateTime 4095 " Invalid" ;
VAL_ 608 UPC_Object5_Point1PositionX 2047 " Invalid" ;
VAL_ 608 UPC_Object5_Point1PositionY 2047 " Invalid" ;
VAL_ 608 UPC_Object5_Point2PositionX 2047 " Invalid" ;
VAL_ 608 UPC_Object5_Point2PositionY 2047 " Invalid" ;
VAL_ 608 UPC_Object5_ID 0 " Invalid" ;
VAL_ 608 PAS_Obj1_5_RollingCounter 15 "Invalid" ;
VAL_ 609 UPC_Object6_Type 0 "None" 1 "Point" 2 "Straight0Corner" 3 "Straight1Corner" 4 "Straight2Corner" 5 "Reserved" 7 " Invalid" ;
VAL_ 609 UPC_Object6_ExistProbability 127 " Invalid" ;
VAL_ 609 UPC_Object6_Height 0 "Low" 1 "High" 2 "Traversable" 3 " Unknown" ;
VAL_ 609 UPC_Object6_HeightProbability 7 " Invalid" ;
VAL_ 609 UPCObject6PositionUpdateTime 4095 " Invalid" ;
VAL_ 609 UPC_Object6_Point1PositionX 2047 " Invalid" ;
VAL_ 609 UPC_Object6_Point1PositionY 2047 " Invalid" ;
VAL_ 609 UPC_Object6_Point2PositionX 2047 " Invalid" ;
VAL_ 609 UPC_Object6_Point2PositionY 2047 " Invalid" ;
VAL_ 609 UPC_Object6_ID 0 " Invalid" ;
VAL_ 609 UPC_Object7_Type 0 "None" 1 "Point" 2 "Straight0Corner" 3 "Straight1Corner" 4 "Straight2Corner" 5 "Reserved" 7 " Invalid" ;
VAL_ 609 UPC_Object7_ExistProbability 127 " Invalid" ;
VAL_ 609 UPC_Object7_Height 0 "Low" 1 "High" 2 "Traversible" 3 " Unknown" ;
VAL_ 609 UPC_Object7_HeightProbability 7 " Invalid" ;
VAL_ 609 UPCObject7PositionUpdateTime 4095 " Invalid" ;
VAL_ 609 UPC_Object7_Point1PositionX 2047 " Invalid" ;
VAL_ 609 UPC_Object7_Point1PositionY 2047 " Invalid" ;
VAL_ 609 UPC_Object7_Point2PositionX 2047 " Invalid" ;
VAL_ 609 UPC_Object7_Point2PositionY 2047 " Invalid" ;
VAL_ 609 UPC_Object7_ID 0 " Invalid" ;
VAL_ 609 UPC_Object8_Type 0 "None" 1 "Point" 2 "Straight0Corner" 3 "Straight1Corner" 4 "Straight2Corner" 5 "Reserved" 7 " Invalid" ;
VAL_ 609 UPC_Object8_ExistProbability 127 " Invalid" ;
VAL_ 609 UPC_Object8_Height 0 "Low" 1 "High" 2 "Traversible" 3 " Unknown" ;
VAL_ 609 UPC_Object8_HeightProbability 7 " Invalid" ;
VAL_ 609 UPCObject8PositionUpdateTime 4095 " Invalid" ;
VAL_ 609 UPC_Object8_Point1PositionX 2047 " Invalid" ;
VAL_ 609 UPC_Object8_Point1PositionY 2047 " Invalid" ;
VAL_ 609 UPC_Object8_Point2PositionX 2047 " Invalid" ;
VAL_ 609 UPC_Object8_Point2PositionY 2047 " Invalid" ;
VAL_ 609 UPC_Object8_ID 0 " Invalid" ;
VAL_ 609 UPC_Object9_Type 0 "None" 1 "Point" 2 "Straight0Corner" 3 "Straight1Corner" 4 "Straight2Corner" 5 "Reserved" 7 " Invalid" ;
VAL_ 609 UPC_Object9_ExistProbability 127 " Invalid" ;
VAL_ 609 UPC_Object9_Height 0 "Low" 1 "High" 2 "Traversible" 3 " Unknown" ;
VAL_ 609 UPC_Object9_HeightProbability 7 " Invalid" ;
VAL_ 609 UPCObject9PositionUpdateTime 4095 " Invalid" ;
VAL_ 609 UPC_Object9_Point1PositionX 2047 " Invalid" ;
VAL_ 609 UPC_Object9_Point1PositionY 2047 " Invalid" ;
VAL_ 609 UPC_Object9_Point2PositionX 2047 " Invalid" ;
VAL_ 609 UPC_Object9_Point2PositionY 2047 " Invalid" ;
VAL_ 609 UPC_Object9_ID 0 " Invalid" ;
VAL_ 609 UPC_Object10_Type 0 "None" 1 "Point" 2 "Straight0Corner" 3 "Straight1Corner" 4 "Straight2Corner" 5 "Reserved" 7 " Invalid" ;
VAL_ 609 UPC_Object10_ExistProbability 127 " Invalid" ;
VAL_ 609 UPC_Object10_Height 0 "Low" 1 "High" 2 "Traversable" 3 " Unknown" ;
VAL_ 609 UPC_Object10_HeightProbability 7 " Invalid" ;
VAL_ 609 UPCObject10PositionUpdateTime 4095 " Invalid" ;
VAL_ 609 UPC_Object10_Point1PositionX 2047 " Invalid" ;
VAL_ 609 UPC_Object10_Point1PositionY 2047 " Invalid" ;
VAL_ 609 UPC_Object10_Point2PositionX 2047 " Invalid" ;
VAL_ 609 UPC_Object10_Point2PositionY 2047 " Invalid" ;
VAL_ 609 UPC_Object10_ID 0 " Invalid" ;
VAL_ 609 PAS_Obj6_10_RollingCounter 15 "Invalid" ;
VAL_ 610 UPC_Object11_Type 0 "None" 1 "Point" 2 "Straight0Corner" 3 "Straight1Corner" 4 "Straight2Corner" 5 "Reserved" 7 " Invalid" ;
VAL_ 610 UPC_Object11_ExistProbability 127 " Invalid" ;
VAL_ 610 UPC_Object11_Height 0 "Low" 1 "High" 2 "Traversable" 3 " Unknown" ;
VAL_ 610 UPC_Object11_HeightProbability 7 " Invalid" ;
VAL_ 610 UPCObject11PositionUpdateTime 4095 " Invalid" ;
VAL_ 610 UPC_Object11_Point1PositionX 2047 " Invalid" ;
VAL_ 610 UPC_Object11_Point1PositionY 2047 " Invalid" ;
VAL_ 610 UPC_Object11_Point2PositionX 2047 " Invalid" ;
VAL_ 610 UPC_Object11_Point2PositionY 2047 " Invalid" ;
VAL_ 610 UPC_Object11_ID 0 " Invalid" ;
VAL_ 610 UPC_Object12_Type 0 "None" 1 "Point" 2 "Straight0Corner" 3 "Straight1Corner" 4 "Straight2Corner" 5 "Reserved" 7 " Invalid" ;
VAL_ 610 UPC_Object12_ExistProbability 127 " Invalid" ;
VAL_ 610 UPC_Object12_Height 0 "Low" 1 "High" 2 "Traversible" 3 " Unknown" ;
VAL_ 610 UPC_Object12_HeightProbability 7 " Invalid" ;
VAL_ 610 UPCObject12PositionUpdateTime 4095 " Invalid" ;
VAL_ 610 UPC_Object12_Point1PositionX 2047 " Invalid" ;
VAL_ 610 UPC_Object12_Point1PositionY 2047 " Invalid" ;
VAL_ 610 UPC_Object12_Point2PositionX 2047 " Invalid" ;
VAL_ 610 UPC_Object12_Point2PositionY 2047 " Invalid" ;
VAL_ 610 UPC_Object12_ID 0 " Invalid" ;
VAL_ 610 UPC_Object13_Type 0 "None" 1 "Point" 2 "Straight0Corner" 3 "Straight1Corner" 4 "Straight2Corner" 5 "Reserved" 7 " Invalid" ;
VAL_ 610 UPC_Object13_ExistProbability 127 " Invalid" ;
VAL_ 610 UPC_Object13_Height 0 "Low" 1 "High" 2 "Traversible" 3 " Unknown" ;
VAL_ 610 UPC_Object13_HeightProbability 7 " Invalid" ;
VAL_ 610 UPCObject13PositionUpdateTime 4095 " Invalid" ;
VAL_ 610 UPC_Object13_Point1PositionX 2047 " Invalid" ;
VAL_ 610 UPC_Object13_Point1PositionY 2047 " Invalid" ;
VAL_ 610 UPC_Object13_Point2PositionX 2047 " Invalid" ;
VAL_ 610 UPC_Object13_Point2PositionY 2047 " Invalid" ;
VAL_ 610 UPC_Object13_ID 0 " Invalid" ;
VAL_ 610 UPC_Object14_Type 0 "None" 1 "Point" 2 "Straight0Corner" 3 "Straight1Corner" 4 "Straight2Corner" 5 "Reserved" 7 " Invalid" ;
VAL_ 610 UPC_Object14_ExistProbability 127 " Invalid" ;
VAL_ 610 UPC_Object14_Height 0 "Low" 1 "High" 2 "Traversible" 3 " Unknown" ;
VAL_ 610 UPC_Object14_HeightProbability 7 " Invalid" ;
VAL_ 610 UPCObject14PositionUpdateTime 4095 " Invalid" ;
VAL_ 610 UPC_Object14_Point1PositionX 2047 " Invalid" ;
VAL_ 610 UPC_Object14_Point1PositionY 2047 " Invalid" ;
VAL_ 610 UPC_Object14_Point2PositionX 2047 " Invalid" ;
VAL_ 610 UPC_Object14_Point2PositionY 2047 " Invalid" ;
VAL_ 610 UPC_Object14_ID 0 " Invalid" ;
VAL_ 610 UPC_Object15_Type 0 "None" 1 "Point" 2 "Straight0Corner" 3 "Straight1Corner" 4 "Straight2Corner" 5 "Reserved" 7 " Invalid" ;
VAL_ 610 UPC_Object15_ExistProbability 127 " Invalid" ;
VAL_ 610 UPC_Object15_Height 0 "Low" 1 "High" 2 "Traversable" 3 " Unknown" ;
VAL_ 610 UPC_Object15_HeightProbability 7 " Invalid" ;
VAL_ 610 UPCObject15PositionUpdateTime 4095 " Invalid" ;
VAL_ 610 UPC_Object15_Point1PositionX 2047 " Invalid" ;
VAL_ 610 UPC_Object15_Point1PositionY 2047 " Invalid" ;
VAL_ 610 UPC_Object15_Point2PositionX 2047 " Invalid" ;
VAL_ 610 UPC_Object15_Point2PositionY 2047 " Invalid" ;
VAL_ 610 UPC_Object15_ID 0 " Invalid" ;
VAL_ 610 PAS_Obj11_15_RollingCounter 15 "Invalid" ;
VAL_ 611 UPC_Object16_Type 0 "None" 1 "Point" 2 "Straight0Corner" 3 "Straight1Corner" 4 "Straight2Corner" 5 "Reserved" 7 " Invalid" ;
VAL_ 611 UPC_Object16_ExistProbability 127 " Invalid" ;
VAL_ 611 UPC_Object16_Height 0 "Low" 1 "High" 2 "Traversable" 3 " Unknown" ;
VAL_ 611 UPC_Object16_HeightProbability 7 " Invalid" ;
VAL_ 611 UPCObject16PositionUpdateTime 4095 " Invalid" ;
VAL_ 611 UPC_Object16_Point1PositionX 2047 " Invalid" ;
VAL_ 611 UPC_Object16_Point1PositionY 2047 " Invalid" ;
VAL_ 611 UPC_Object16_Point2PositionX 2047 " Invalid" ;
VAL_ 611 UPC_Object16_Point2PositionY 2047 " Invalid" ;
VAL_ 611 UPC_Object16_ID 0 " Invalid" ;
VAL_ 611 UPC_Object17_Type 0 "None" 1 "Point" 2 "Straight0Corner" 3 "Straight1Corner" 4 "Straight2Corner" 5 "Reserved" 7 " Invalid" ;
VAL_ 611 UPC_Object17_ExistProbability 127 " Invalid" ;
VAL_ 611 UPC_Object17_Height 0 "Low" 1 "High" 2 "Traversible" 3 " Unknown" ;
VAL_ 611 UPC_Object17_HeightProbability 7 " Invalid" ;
VAL_ 611 UPCObject17PositionUpdateTime 4095 " Invalid" ;
VAL_ 611 UPC_Object17_Point1PositionX 2047 " Invalid" ;
VAL_ 611 UPC_Object17_Point1PositionY 2047 " Invalid" ;
VAL_ 611 UPC_Object17_Point2PositionX 2047 " Invalid" ;
VAL_ 611 UPC_Object17_Point2PositionY 2047 " Invalid" ;
VAL_ 611 UPC_Object17_ID 0 " Invalid" ;
VAL_ 611 UPC_Object18_Type 0 "None" 1 "Point" 2 "Straight0Corner" 3 "Straight1Corner" 4 "Straight2Corner" 5 "Reserved" 7 " Invalid" ;
VAL_ 611 UPC_Object18_ExistProbability 127 " Invalid" ;
VAL_ 611 UPC_Object18_Height 0 "Low" 1 "High" 2 "Traversible" 3 " Unknown" ;
VAL_ 611 UPC_Object18_HeightProbability 7 " Invalid" ;
VAL_ 611 UPCObject18PositionUpdateTime 4095 " Invalid" ;
VAL_ 611 UPC_Object18_Point1PositionX 2047 " Invalid" ;
VAL_ 611 UPC_Object18_Point1PositionY 2047 " Invalid" ;
VAL_ 611 UPC_Object18_Point2PositionX 2047 " Invalid" ;
VAL_ 611 UPC_Object18_Point2PositionY 2047 " Invalid" ;
VAL_ 611 UPC_Object18_ID 0 " Invalid" ;
VAL_ 611 UPC_Object19_Type 0 "None" 1 "Point" 2 "Straight0Corner" 3 "Straight1Corner" 4 "Straight2Corner" 5 "Reserved" 7 " Invalid" ;
VAL_ 611 UPC_Object19_ExistProbability 127 " Invalid" ;
VAL_ 611 UPC_Object19_Height 0 "Low" 1 "High" 2 "Traversible" 3 " Unknown" ;
VAL_ 611 UPC_Object19_HeightProbability 7 " Invalid" ;
VAL_ 611 UPCObject19PositionUpdateTime 4095 " Invalid" ;
VAL_ 611 UPC_Object19_Point1PositionX 2047 " Invalid" ;
VAL_ 611 UPC_Object19_Point1PositionY 2047 " Invalid" ;
VAL_ 611 UPC_Object19_Point2PositionX 2047 " Invalid" ;
VAL_ 611 UPC_Object19_Point2PositionY 2047 " Invalid" ;
VAL_ 611 UPC_Object19_ID 0 " Invalid" ;
VAL_ 611 UPC_Object20_Type 0 "None" 1 "Point" 2 "Straight0Corner" 3 "Straight1Corner" 4 "Straight2Corner" 5 "Reserved" 7 " Invalid" ;
VAL_ 611 UPC_Object20_ExistProbability 127 " Invalid" ;
VAL_ 611 UPC_Object20_Height 0 "Low" 1 "High" 2 "Traversable" 3 " Unknown" ;
VAL_ 611 UPC_Object20_HeightProbability 7 " Invalid" ;
VAL_ 611 UPCObject20PositionUpdateTime 4095 " Invalid" ;
VAL_ 611 UPC_Object20_Point1PositionX 2047 " Invalid" ;
VAL_ 611 UPC_Object20_Point1PositionY 2047 " Invalid" ;
VAL_ 611 UPC_Object20_Point2PositionX 2047 " Invalid" ;
VAL_ 611 UPC_Object20_Point2PositionY 2047 " Invalid" ;
VAL_ 611 UPC_Object20_ID 0 " Invalid" ;
VAL_ 611 PAS_Obj16_20_RollingCounter 15 "Invalid" ;
VAL_ 624 UPC_ParkingSlot1_ID 0 "No Space" 255 " Invalid" ;
VAL_ 624 UPC_ParkingSlot1_Status 0 "PSNone" 1 "PSOk" 2 " Reserved" ;
VAL_ 624 UPC_ParkingSlot1_Type 0 "None" 1 "LeftParallel" 2 "RightParallel" 3 "LeftCross" 4 "RightCross" 5 "Reserved" 7 " Invalid" ;
VAL_ 624 UPC_ParkingSlot1_ObjectType 0 "None" 1 "Curb" 2 "Wall" 3 "Virtual" 4 "Low" 5 "High" 6 "Unknow" 7 " Reserved" ;
VAL_ 624 UPC_ParkingSlot1_Length 2046 "No Space" 2047 " Invalid" ;
VAL_ 624 UPC_ParkingSlot1_Depth 1022 "No Space" 1023 " Invalid" ;
VAL_ 624 UPCParkSlot1Point1ObjectType 0 "None" 1 "Virtual" 2 "Real" 3 " Reserved" ;
VAL_ 624 UPCParkSlot1Point2ObjectType 0 "None" 1 "Virtual" 2 "Real" 3 " Reserved" ;
VAL_ 624 UPCParkSlot1Point1PositionAngle 126 "No Space" 127 " Invalid" ;
VAL_ 624 UPCParkSlot1Point2PositionAngle 126 "No Space" 127 " Invalid" ;
VAL_ 624 UPCParkSlot1Point1PositionX 8190 "No Space" 8191 " Invalid" ;
VAL_ 624 UPCParkSlot1Point1PositionY 8190 "No Space" 8191 " Invalid" ;
VAL_ 624 UPCParkSlot1Point2PositionX 8190 "No Space" 8191 " Invalid" ;
VAL_ 624 UPCParkSlot1Point2PositionY 8190 "No Space" 8191 " Invalid" ;
VAL_ 624 UPCParkSlot1PositionUpdateTime 4095 " Invalid" ;
VAL_ 624 UPC_ParkingSlot2_ID 0 "No Space" 255 " Invalid" ;
VAL_ 624 UPC_ParkingSlot2_Status 0 "PSNone" 1 "PSOk" 2 " Reserved" ;
VAL_ 624 UPC_ParkingSlot2_Type 0 "None" 1 "LeftParallel" 2 "RightParallel" 3 "LeftCross" 4 "RightCross" 5 "Reserved" 7 " Invalid" ;
VAL_ 624 UPC_ParkingSlot2_ObjectType 0 "None" 1 "Curb" 2 "Wall" 3 "Virtual" 4 "Low" 5 "High" 6 "Unknow" 7 " Reserved" ;
VAL_ 624 UPC_ParkingSlot2_Length 2046 "No Space" 2047 " Invalid" ;
VAL_ 624 UPC_ParkingSlot2_Depth 1022 "No Space" 1023 " Invalid" ;
VAL_ 624 UPCParkSlot2Point1ObjectType 0 "None" 1 "Virtual" 2 "Real" 3 " Reserved" ;
VAL_ 624 UPCParkSlot2Point2ObjectType 0 "None" 1 "Virtual" 2 "Real" 3 " Reserved" ;
VAL_ 624 UPCParkSlot2Point1PositionAngle 126 "No Space" 127 " Invalid" ;
VAL_ 624 UPCParkSlot2Point2PositionAngle 126 "No Space" 127 " Invalid" ;
VAL_ 624 UPCParkSlot2Point1PositionX 8190 "No Space" 8191 " Invalid" ;
VAL_ 624 UPCParkSlot2Point1PositionY 8190 "No Space" 8191 " Invalid" ;
VAL_ 624 UPCParkSlot2Point2PositionX 8190 "No Space" 8191 " Invalid" ;
VAL_ 624 UPCParkSlot2Point2PositionY 8190 "No Space" 8191 " Invalid" ;
VAL_ 624 UPCParkSlot2PositionUpdateTime 4095 " Invalid" ;
VAL_ 624 UPC_ParkingSlot3_ID 0 "No Space" 255 " Invalid" ;
VAL_ 624 UPC_ParkingSlot3_Status 0 "PSNone" 1 "PSOk" 2 " Reserved" ;
VAL_ 624 UPC_ParkingSlot3_Type 0 "None" 1 "LeftParallel" 2 "RightParallel" 3 "LeftCross" 4 "RightCross" 5 "Reserved" 7 " Invalid" ;
VAL_ 624 UPC_ParkingSlot3_ObjectType 0 "None" 1 "Curb" 2 "Wall" 3 "Virtual" 4 "Low" 5 "High" 6 "Unknow" 7 " Reserved" ;
VAL_ 624 UPC_ParkingSlot3_Length 2046 "No Space" 2047 " Invalid" ;
VAL_ 624 UPC_ParkingSlot3_Depth 1022 "No Space" 1023 " Invalid" ;
VAL_ 624 UPCParkSlot3Point1ObjectType 0 "None" 1 "Virtual" 2 "Real" 3 " Reserved" ;
VAL_ 624 UPCParkSlot3Point2ObjectType 0 "None" 1 "Virtual" 2 "Real" 3 " Reserved" ;
VAL_ 624 UPCParkSlot3Point1PositionAngle 126 "No Space" 127 " Invalid" ;
VAL_ 624 UPCParkSlot3Point2PositionAngle 126 "No Space" 127 " Invalid" ;
VAL_ 624 UPCParkSlot3Point1PositionX 8190 "No Space" 8191 " Invalid" ;
VAL_ 624 UPCParkSlot3Point1PositionY 8190 "No Space" 8191 " Invalid" ;
VAL_ 624 UPCParkSlot3Point2PositionX 8190 "No Space" 8191 " Invalid" ;
VAL_ 624 UPCParkSlot3Point2PositionY 8190 "No Space" 8191 " Invalid" ;
VAL_ 624 UPCParkSlot3PositionUpdateTime 4095 " Invalid" ;
VAL_ 624 PAS_Slot1_3_RollingCounter 15 "Invalid" ;
VAL_ 625 UPC_ParkingSlot4_ID 0 "No Space" 255 " Invalid" ;
VAL_ 625 UPC_ParkingSlot4_Status 0 "PSNone" 1 "PSOk" 2 " Reserved" ;
VAL_ 625 UPC_ParkingSlot4_Type 0 "None" 1 "LeftParallel" 2 "RightParallel" 3 "LeftCross" 4 "RightCross" 5 "Reserved" 7 " Invalid" ;
VAL_ 625 UPC_ParkingSlot4_ObjectType 0 "None" 1 "Curb" 2 "Wall" 3 "Virtual" 4 "Low" 5 "High" 6 "Unknow" 7 " Reserved" ;
VAL_ 625 UPC_ParkingSlot4_Length 2046 "No Space" 2047 " Invalid" ;
VAL_ 625 UPC_ParkingSlot4_Depth 1022 "No Space" 1023 " Invalid" ;
VAL_ 625 UPCParkSlot4Point1ObjectType 0 "None" 1 "Virtual" 2 "Real" 3 " Reserved" ;
VAL_ 625 UPCParkSlot4Point2ObjectType 0 "None" 1 "Virtual" 2 "Real" 3 " Reserved" ;
VAL_ 625 UPCParkSlot4Point1PositionAngle 126 "No Space" 127 " Invalid" ;
VAL_ 625 UPCParkSlot4Point2PositionAngle 126 "No Space" 127 " Invalid" ;
VAL_ 625 UPCParkSlot4Point1PositionX 8190 "No Space" 8191 " Invalid" ;
VAL_ 625 UPCParkSlot4Point1PositionY 8190 "No Space" 8191 " Invalid" ;
VAL_ 625 UPCParkSlot4Point2PositionX 8190 "No Space" 8191 " Invalid" ;
VAL_ 625 UPCParkSlot4Point2PositionY 8190 "No Space" 8191 " Invalid" ;
VAL_ 625 UPCParkSlot4PositionUpdateTime 4095 " Invalid" ;
VAL_ 625 UPC_ParkingSlot5_ID 0 "No Space" 255 " Invalid" ;
VAL_ 625 UPC_ParkingSlot5_Status 0 "PSNone" 1 "PSOk" 2 " Reserved" ;
VAL_ 625 UPC_ParkingSlot5_Type 0 "None" 1 "LeftParallel" 2 "RightParallel" 3 "LeftCross" 4 "RightCross" 5 "Reserved" 7 " Invalid" ;
VAL_ 625 UPC_ParkingSlot5_ObjectType 0 "None" 1 "Curb" 2 "Wall" 3 "Virtual" 4 "Low" 5 "High" 6 "Unknow" 7 " Reserved" ;
VAL_ 625 UPC_ParkingSlot5_Length 2046 "No Space" 2047 " Invalid" ;
VAL_ 625 UPC_ParkingSlot5_Depth 1022 "No Space" 1023 " Invalid" ;
VAL_ 625 UPCParkSlot5Point1ObjectType 0 "None" 1 "Virtual" 2 "Real" 3 " Reserved" ;
VAL_ 625 UPCParkSlot5Point2ObjectType 0 "None" 1 "Virtual" 2 "Real" 3 " Reserved" ;
VAL_ 625 UPCParkSlot5Point1PositionAngle 126 "No Space" 127 " Invalid" ;
VAL_ 625 UPCParkSlot5Point2PositionAngle 126 "No Space" 127 " Invalid" ;
VAL_ 625 UPCParkSlot5Point1PositionX 8190 "No Space" 8191 " Invalid" ;
VAL_ 625 UPCParkSlot5Point1PositionY 8190 "No Space" 8191 " Invalid" ;
VAL_ 625 UPCParkSlot5Point2PositionX 8190 "No Space" 8191 " Invalid" ;
VAL_ 625 UPCParkSlot5Point2PositionY 8190 "No Space" 8191 " Invalid" ;
VAL_ 625 UPCParkSlot5PositionUpdateTime 4095 " Invalid" ;
VAL_ 625 UPC_ParkingSlot6_ID 0 "No Space" 255 " Invalid" ;
VAL_ 625 UPC_ParkingSlot6_Status 0 "PSNone" 1 "PSOk" 2 " Reserved" ;
VAL_ 625 UPC_ParkingSlot6_Type 0 "None" 1 "LeftParallel" 2 "RightParallel" 3 "LeftCross" 4 "RightCross" 5 "Reserved" 7 " Invalid" ;
VAL_ 625 UPC_ParkingSlot6_ObjectType 0 "None" 1 "Curb" 2 "Wall" 3 "Virtual" 4 "Low" 5 "High" 6 "Unknow" 7 " Reserved" ;
VAL_ 625 UPC_ParkingSlot6_Length 2046 "No Space" 2047 " Invalid" ;
VAL_ 625 UPC_ParkingSlot6_Depth 1022 "No Space" 1023 " Invalid" ;
VAL_ 625 UPCParkSlot6Point1ObjectType 0 "None" 1 "Virtual" 2 "Real" 3 " Reserved" ;
VAL_ 625 UPCParkSlot6Point2ObjectType 0 "None" 1 "Virtual" 2 "Real" 3 " Reserved" ;
VAL_ 625 UPCParkSlot6Point1PositionAngle 126 "No Space" 127 " Invalid" ;
VAL_ 625 UPCParkSlot6Point2PositionAngle 126 "No Space" 127 " Invalid" ;
VAL_ 625 UPCParkSlot6Point1PositionX 8190 "No Space" 8191 " Invalid" ;
VAL_ 625 UPCParkSlot6Point1PositionY 8190 "No Space" 8191 " Invalid" ;
VAL_ 625 UPCParkSlot6Point2PositionX 8190 "No Space" 8191 " Invalid" ;
VAL_ 625 UPCParkSlot6Point2PositionY 8190 "No Space" 8191 " Invalid" ;
VAL_ 625 UPCParkSlot6PositionUpdateTime 4095 " Invalid" ;
VAL_ 625 PAS_Slot4_6_RollingCounter 15 "Invalid" ;
VAL_ 626 UPC_ParkingSlot7_ID 0 "No Space" 255 " Invalid" ;
VAL_ 626 UPC_ParkingSlot7_Status 0 "PSNone" 1 "PSOk" 2 " Reserved" ;
VAL_ 626 UPC_ParkingSlot7_Type 0 "None" 1 "LeftParallel" 2 "RightParallel" 3 "LeftCross" 4 "RightCross" 5 "Reserved" 7 " Invalid" ;
VAL_ 626 UPC_ParkingSlot7_ObjectType 0 "None" 1 "Curb" 2 "Wall" 3 "Virtual" 4 "Low" 5 "High" 6 "Unknow" 7 " Reserved" ;
VAL_ 626 UPC_ParkingSlot7_Length 2046 "No Space" 2047 " Invalid" ;
VAL_ 626 UPC_ParkingSlot7_Depth 1022 "No Space" 1023 " Invalid" ;
VAL_ 626 UPCParkSlot7Point1ObjectType 0 "None" 1 "Virtual" 2 "Real" 3 " Reserved" ;
VAL_ 626 UPCParkSlot7Point2ObjectType 0 "None" 1 "Virtual" 2 "Real" 3 " Reserved" ;
VAL_ 626 UPCParkSlot7Point1PositionAngle 126 "No Space" 127 " Invalid" ;
VAL_ 626 UPCParkSlot7Point2PositionAngle 126 "No Space" 127 " Invalid" ;
VAL_ 626 UPCParkSlot7Point1PositionX 8190 "No Space" 8191 " Invalid" ;
VAL_ 626 UPCParkSlot7Point1PositionY 8190 "No Space" 8191 " Invalid" ;
VAL_ 626 UPCParkSlot7Point2PositionX 8190 "No Space" 8191 " Invalid" ;
VAL_ 626 UPCParkSlot7Point2PositionY 8190 "No Space" 8191 " Invalid" ;
VAL_ 626 UPCParkSlot7PositionUpdateTime 4095 " Invalid" ;
VAL_ 626 UPC_ParkingSlot8_ID 0 "No Space" 255 " Invalid" ;
VAL_ 626 UPC_ParkingSlot8_Status 0 "PSNone" 1 "PSOk" 2 " Reserved" ;
VAL_ 626 UPC_ParkingSlot8_Type 0 "None" 1 "LeftParallel" 2 "RightParallel" 3 "LeftCross" 4 "RightCross" 5 "Reserved" 7 " Invalid" ;
VAL_ 626 UPC_ParkingSlot8_ObjectType 0 "None" 1 "Curb" 2 "Wall" 3 "Virtual" 4 "Low" 5 "High" 6 "Unknow" 7 " Reserved" ;
VAL_ 626 UPC_ParkingSlot8_Length 2046 "No Space" 2047 " Invalid" ;
VAL_ 626 UPC_ParkingSlot8_Depth 1022 "No Space" 1023 " Invalid" ;
VAL_ 626 UPCParkSlot8Point1ObjectType 0 "None" 1 "Virtual" 2 "Real" 3 " Reserved" ;
VAL_ 626 UPCParkSlot8Point2ObjectType 0 "None" 1 "Virtual" 2 "Real" 3 " Reserved" ;
VAL_ 626 UPCParkSlot8Point1PositionAngle 126 "No Space" 127 " Invalid" ;
VAL_ 626 UPCParkSlot8Point2PositionAngle 126 "No Space" 127 " Invalid" ;
VAL_ 626 UPCParkSlot8Point1PositionX 8190 "No Space" 8191 " Invalid" ;
VAL_ 626 UPCParkSlot8Point1PositionY 8190 "No Space" 8191 " Invalid" ;
VAL_ 626 UPCParkSlot8Point2PositionX 8190 "No Space" 8191 " Invalid" ;
VAL_ 626 UPCParkSlot8Point2PositionY 8190 "No Space" 8191 " Invalid" ;
VAL_ 626 UPCParkSlot8PositionUpdateTime 4095 " Invalid" ;
VAL_ 626 PAS_Slot7_8_RollingCounter 15 "Invalid" ;
VAL_ 640 UPCVehiclePositionUpdateTime 4095 " Invalid" ;
VAL_ 640 PAS_VehPos_RollingCounter 15 "Invalid" ;
VAL_ 641 PAS_PSL_Status 0 "Off" 1 "Standby" 2 "Searching" 3 "Guidance" 4 "Failure" 5 " Reserved" ;
VAL_ 641 PAS_PSL_RollingCounter 15 "Invalid" ;
VAL_ 642 PAS_Echo_WorkMode 0 "Off" 1 "Standby" 2 "FrontRearActive" 3 "FrontActiveAndRearFailure" 4 "RearActiveAndFrontFailure" 5 "SystemFailure" 6 "suspension Adjust" 7 "resetting" 8 "~0xF: Reserved" ;
VAL_ 642 PAS_MapObject_OuputStatus 0 "Off" 1 "Standby" 2 "FrontRearActive" 3 "FrontActiveAndRearFailure" 4 "RearActiveAndFrontFailure" 5 "SystemFailure" 6 " Reserved" ;
VAL_ 642 PAS_EchoMap_RollingCounter 15 "Invalid" ;
VAL_ 768 MDC_PAS_Control 0 "system off" 1 "standby" 2 "Enable" 3 "reserved" ;
VAL_ 768 Fill4bit 255 "填充位" ;
VAL_ 769 MDC_ESC_VehicleSpeed_Valid 0 "Invalid" 1 " Valid" ;
VAL_ 769 MDC_SAS_SteerWheelAngle_Valid 0 "Invalid" 1 " Valid" ;
VAL_ 769 MDC_BCM_OutTemp_Valid 0 "Invalid" 1 " Valid" ;
VAL_ 769 MDC_VCU_GearStatus 0 "P" 1 "N" 2 "D" 3 "R" ;
VAL_ 769 MDC_VCU_GearStatus_Valid 0 "Invalid" 1 " Valid" ;
VAL_ 769 MDC_ESC_FLWheelSpeedRC_Valid 0 "Invalid" 1 " Valid" ;
VAL_ 769 MDC_ESC_FRWheelSpeedRC_Valid 0 "Invalid" 1 " Valid" ;
VAL_ 769 MDC_ESC_RLWheelSpeedRC_Valid 0 "Invalid" 1 " Valid" ;
VAL_ 769 MDC_ESC_RRWheelSpeedRC_Valid 0 "Invalid" 1 " Valid" ;
VAL_ 769 MDC_ESC_FLWheelDirection 0 "FORWARD" 1 "BACKWARD" 2 "STANDSTILL" 3 " INVALID" ;
VAL_ 769 MDC_ESC_FLWheelDirection_Valid 0 "Invalid" 1 " Valid" ;
VAL_ 769 MDC_ESC_FRWheelDirection 0 "FORWARD" 1 "BACKWARD" 2 "STANDSTILL" 3 " INVALID" ;
VAL_ 769 MDC_ESC_FRWheelDirection_Valid 0 "Invalid" 1 " Valid" ;
VAL_ 769 MDC_ESC_RLWheelDirection 0 "FORWARD" 1 "BACKWARD" 2 "STANDSTILL" 3 " INVALID" ;
VAL_ 769 MDC_ESC_RLWheelDirection_Valid 0 "Invalid" 1 " Valid" ;
VAL_ 769 MDC_ESC_RRWheelDirection 0 "FORWARD" 1 "BACKWARD" 2 "STANDSTILL" 3 " INVALID" ;
VAL_ 769 MDC_ESC_RRWheelDirection_Valid 0 "Invalid" 1 " Valid" ;
VAL_ 769 YawRateSensor_St 0 "Invalid" 1 " Valid" ;
VAL_ 769 wheelspeedValid 0 "0x0-invali" ;
VAL_ 769 ecasVehiclePositionState 0 "Initializing" 1 "Very High" 2 "High" 3 "Standard" 4 "Low" 5 "Very Low" 6 "invalid" 7 "no air suspension" ;
VAL_ 769 ecasVehicleUpDownState 0 "standby" 1 "Up" 2 "Down" 3 "reserve" 4 "reserve" 5 "reserve" 6 "reserve" 7 "invalid" ;
VAL_ 769 VehiclePositionStateValid 0 "Invalid" 1 "valid" ;
VAL_ 769 VehicleUpDownStateValid 0 "Invalid" 1 "valid" ;
VAL_ 770 PAS_Sonar1_Req 0 "off" 1 "receive only" 2 "emit and receive" ;
VAL_ 770 PAS_Sonar2_Req 0 "off" 1 "receive only" 2 "emit and receive" ;
VAL_ 770 PAS_Sonar3_Req 0 "off" 1 "receive only" 2 "emit and receive" ;
VAL_ 770 PAS_Sonar4_Req 0 "off" 1 "receive only" 2 "emit and receive" ;
VAL_ 770 PAS_Sonar7_Req 0 "off" 1 "receive only" 2 "emit and receive" ;
VAL_ 770 PAS_Sonar8_Req 0 "off" 1 "receive only" 2 "emit and receive" ;
VAL_ 770 PAS_Sonar9_Req 0 "off" 1 "receive only" 2 "emit and receive" ;
VAL_ 770 PAS_Sonar10_Req 0 "off" 1 "receive only" 2 "emit and receive" ;
VAL_ 770 PAS_Sonar0_Req 0 "off" 1 "receive only" 2 "emit and receive" ;
VAL_ 770 PAS_Sonar5_Req 0 "off" 1 "receive only" 2 "emit and receive" ;
VAL_ 770 PAS_Sonar6_Req 0 "off" 1 "receive only" 2 "emit and receive" ;
VAL_ 770 PAS_Sonar11_Req 0 "off" 1 "receive only" 2 "emit and receive" ;
VAL_ 770 Fill4bit 255 "填充位" ;
VAL_ 770 PAS_Function_Req 1 "低速模式" 0 "高速模式（默认模式）" ;
VAL_ 771 Ack_Alarm_State 0 "告警恢复" 1 " 告警产生" ;
VAL_ 771 Ack_Alarm_Level 0 "提示" 1 "一般" 2 " 严重" ;
VAL_ 771 Fill4bit 255 "填充位" ;
VAL_ 929 MDC_Response_Result 0 "处理成功" 1 " 处理失败" ;
VAL_ 965 Mdc_Verify_Result_Status 0 "失败" 1 "成功" ;
VAL_ 773 sensorVersion 9 "F1A / F1A_m" 0 "mode1:F2 EV" 1 "mode2:F2 EVR" 2 "mode3:F1" ;
